VERSION ""

NS_ :

BS_:

BU_: Dummy_FO EOCM2cp_K2_FO EOCM2cp_K1_FO EOCM2cp_IMX6_FO CECM_R1_FO CMMb_FO CMMa_FO RSRR_FO LRR_FO CIPM_FO IMU2_FO IMU1_FO CGM3b_FO

BO_ 1369 UUDT_Resp_From_RSRR_FO: 8 RSRR_FO
 SG_ DgnInf_OBJ559 : 7|64@0+ (1,0) [0|1.84467440737096E+019] ""  CECM_R1_FO,CGM3b_FO

BO_ 1346 UUDT_Resp_From_LRR: 8 LRR_FO
 SG_ DgnInf_OBJ542 : 7|64@0+ (1,0) [0|1.84467440737096E+019] ""  CECM_R1_FO,CGM3b_FO

BO_ 601 USDT_Req_to_RSRR_FO: 8 CGM3b_FO
 SG_ DgnInf : 7|64@0+ (1,0) [0|1.84467440737096E+019] ""  RSRR_FO

BO_ 578 USDT_Req_to_LRR_FO: 8 CGM3b_FO
 SG_ DgnInf : 7|64@0+ (1,0) [0|1.84467440737096E+019] ""  LRR_FO

BO_ 1616 USDT_Resp_From_EOCM2cp_IMX6_FO: 8 EOCM2cp_IMX6_FO
 SG_ DgnInf : 7|64@0+ (1,0) [0|1.84467440737096E+019] ""  CECM_R1_FO,CGM3b_FO

BO_ 1373 UUDT_Resp_From_CGM3b_FO: 8 CGM3b_FO
 SG_ DgnInf_FO55D : 7|64@0+ (1,0) [0|1.84467440737096E+019] ""  CECM_R1_FO

BO_ 1629 USDT_Resp_From_CGM3b_FO: 8 CGM3b_FO
 SG_ DgnInf : 7|64@0+ (1,0) [0|1.84467440737096E+019] ""  CECM_R1_FO

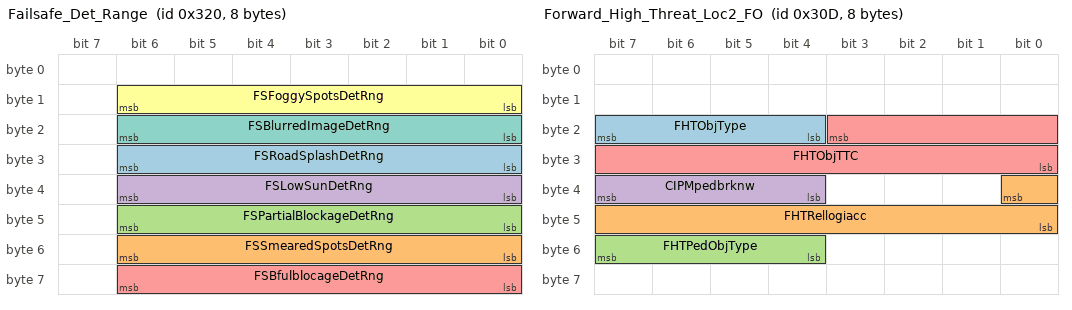
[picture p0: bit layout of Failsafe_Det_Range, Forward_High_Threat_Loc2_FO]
BO_ 800 Failsafe_Det_Range: 8 EOCM2cp_K1_FO
 SG_ FSRoadSplashDetRng : 30|7@0+ (1,-0) [0|127] ""  CGM3b_FO,CECM_R1_FO
 SG_ FSSmearedSpotsDetRng : 54|7@0+ (1,-0) [0|127] ""  CGM3b_FO,CECM_R1_FO
 SG_ FSPartialBlockageDetRng : 46|7@0+ (1,-0) [0|127] ""  CGM3b_FO,CECM_R1_FO
 SG_ FSLowSunDetRng : 38|7@0+ (1,-0) [0|127] ""  CGM3b_FO,CECM_R1_FO
 SG_ FSBfulblocageDetRng : 62|7@0+ (1,-0) [0|127] ""  CGM3b_FO,CECM_R1_FO
 SG_ FSFoggySpotsDetRng : 14|7@0+ (1,-0) [0|127] ""  CGM3b_FO,CECM_R1_FO
 SG_ FSBlurredImageDetRng : 22|7@0+ (1,-0) [0|127] ""  CGM3b_FO,CECM_R1_FO

BO_ 781 Forward_High_Threat_Loc2_FO: 8 EOCM2cp_K1_FO
 SG_ FHTObjType : 23|4@0+ (1,0) [0|15] ""  CECM_R1_FO
 SG_ FHTRellogiacc : 32|9@0- (0.125,0) [-32|31.875] ""  CECM_R1_FO,CGM3b_FO
 SG_ FHTPedObjType : 55|4@0+ (1,0) [0|15] ""  CECM_R1_FO,CGM3b_FO
 SG_ CIPMpedbrknw : 39|4@0+ (1,0) [0|15] ""  CECM_R1_FO,CGM3b_FO
 SG_ FHTObjTTC : 19|12@0+ (0.025,0) [0|102.375] ""  CECM_R1_FO,CGM3b_FO

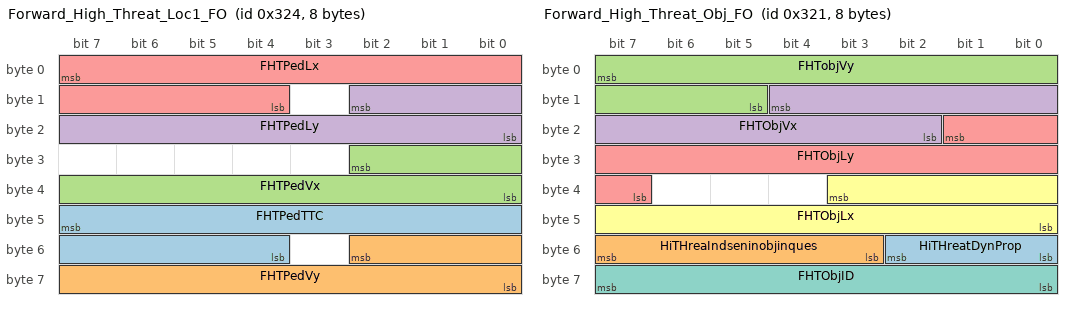
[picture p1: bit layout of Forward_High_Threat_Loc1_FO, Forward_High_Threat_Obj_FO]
BO_ 804 Forward_High_Threat_Loc1_FO: 8 EOCM2cp_K1_FO
 SG_ FHTPedTTC : 47|12@0+ (0.025,0) [0|102.375] ""  CGM3b_FO,CECM_R1_FO
 SG_ FHTPedVy : 50|11@0- (0.125,0) [-128|127.875] ""  CGM3b_FO,CECM_R1_FO
 SG_ FHTPedVx : 26|11@0- (0.125,0) [-128|127.875] ""  CGM3b_FO,CECM_R1_FO
 SG_ FHTPedLy : 10|11@0- (0.125,0) [-128|127.875] ""  CGM3b_FO,CECM_R1_FO
 SG_ FHTPedLx : 7|12@0- (0.125,0) [-256|255.875] ""  CGM3b_FO,CECM_R1_FO

BO_ 801 Forward_High_Threat_Obj_FO: 8 EOCM2cp_K1_FO
 SG_ HiTHreatDynProp : 50|3@0+ (1,0) [0|7] ""  CGM3b_FO,CECM_R1_FO
 SG_ HiTHreaIndseninobjinques : 55|5@0+ (1,0) [0|31] ""  CGM3b_FO,CECM_R1_FO
 SG_ FHTobjVy : 7|11@0- (0.125,0) [-128|127.875] ""  CGM3b_FO,CECM_R1_FO
 SG_ FHTObjVx : 12|11@0- (0.125,0) [-128|127.875] ""  CGM3b_FO,CECM_R1_FO
 SG_ FHTObjLy : 17|11@0- (0.125,0) [-128|127.875] ""  CGM3b_FO,CECM_R1_FO
 SG_ FHTObjLx : 35|12@0- (0.125,0) [-256|255.875] ""  CGM3b_FO,CECM_R1_FO
 SG_ FHTObjID : 63|8@0+ (1,0) [0|255] ""  CGM3b_FO,CECM_R1_FO

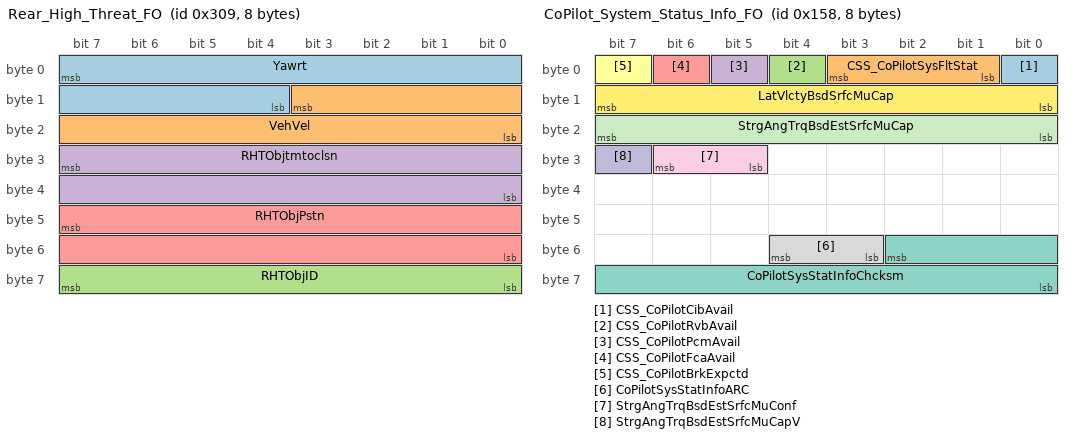
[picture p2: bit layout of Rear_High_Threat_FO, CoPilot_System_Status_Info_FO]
BO_ 777 Rear_High_Threat_FO: 8 EOCM2cp_K2_FO
 SG_ Yawrt : 7|12@0- (0.05,0) [-102.4|102.35] "deg/sec"  CGM3b_FO,CECM_R1_FO
 SG_ VehVel : 11|12@0- (0.0625,0) [-128|127.9375] ""  CGM3b_FO,CECM_R1_FO
 SG_ RHTObjID : 63|8@0+ (1,0) [0|255] ""  CGM3b_FO,CECM_R1_FO
 SG_ RHTObjtmtoclsn : 31|16@0+ (0.001526,0) [0|100.00641] ""  CGM3b_FO,CECM_R1_FO
 SG_ RHTObjPstn : 47|16@0- (0.003052,0) [-100.007936|100.004884] ""  CGM3b_FO,CECM_R1_FO

BO_ 605 USDT_Req_to_CGM3b_FO: 8 CECM_R1_FO
 SG_ DgnInf : 7|64@0+ (1,0) [0|1.84467440737096E+019] ""  CGM3b_FO

BO_ 1366 UUDT_Resp_From_CMMb_FO: 8 CMMb_FO
 SG_ DgnInf_FO556 : 7|64@0+ (1,0) [0|1.84467440737096E+019] ""  CGM3b_FO

BO_ 587 USDT_Req_to_EOCM2cp_K2_FO: 8 CGM3b_FO
 SG_ DgnInf : 7|64@0+ (1,0) [0|1.84467440737096E+019] ""  EOCM2cp_K2_FO

BO_ 1355 UUDT_Resp_From_EOCM2cp_K2_FO: 8 EOCM2cp_K2_FO
 SG_ DgnInf_OBJ54B : 7|64@0+ (1,0) [0|1.84467440737096E+019] ""  CECM_R1_FO,CGM3b_FO

BO_ 1611 USDT_Resp_From_EOCM2cp_K2_FO: 8 EOCM2cp_K2_FO
 SG_ DgnInf : 7|64@0+ (1,0) [0|1.84467440737096E+019] ""  CECM_R1_FO,CGM3b_FO

BO_ 1916 DTC_Triggered_77C_FO: 7 CMMb_FO
 SG_ DTCI_DTCFaultType_77C : 55|8@0+ (1,0) [0|255] ""  CGM3b_FO
 SG_ DTCI_CodeSupported_77C : 40|1@0+ (1,0) [0|1] ""  CGM3b_FO
 SG_ DTCI_CurrentStatus_77C : 41|1@0+ (1,0) [0|1] ""  CGM3b_FO
 SG_ DTCI_TstNPsdCdClrdSt_77C : 42|1@0+ (1,0) [0|1] ""  CGM3b_FO
 SG_ DTCI_TstFldCdClrdStat_77C : 43|1@0+ (1,0) [0|1] ""  CGM3b_FO
 SG_ DTCI_HistStat_77C : 44|1@0+ (1,0) [0|1] ""  CGM3b_FO
 SG_ DTCI_TstNPsdPwrUpSt_77C : 45|1@0+ (1,0) [0|1] ""  CGM3b_FO
 SG_ DTCI_TstFldPwrUpSt_77C : 46|1@0+ (1,0) [0|1] ""  CGM3b_FO
 SG_ DTCI_WrnIndRqdSt_77C : 47|1@0+ (1,0) [0|1] ""  CGM3b_FO
 SG_ DTCI_DTCFailType_77C : 39|8@0+ (1,0) [0|255] ""  CGM3b_FO
 SG_ DTCI_DTCNumber_77C : 23|16@0+ (1,0) [0|65535] ""  CGM3b_FO
 SG_ DTCI_DTCSource_77C : 15|8@0+ (1,0) [0|255] ""  CGM3b_FO
 SG_ DTCI_DTCTriggered_77C : 0|1@0+ (1,0) [0|1] ""  CGM3b_FO
 SG_ DTCIUnused7_77C : 1|1@0+ (1,0) [0|1] ""  CGM3b_FO
 SG_ DTCIUnused6_77C : 2|1@0+ (1,0) [0|1] ""  CGM3b_FO
 SG_ DTCIUnused5_77C : 3|1@0+ (1,0) [0|1] ""  CGM3b_FO
 SG_ DTCIUnused4_77C : 4|1@0+ (1,0) [0|1] ""  CGM3b_FO
 SG_ DTCIUnused3_77C : 5|1@0+ (1,0) [0|1] ""  CGM3b_FO
 SG_ DTCIUnused2_77C : 6|1@0+ (1,0) [0|1] ""  CGM3b_FO
 SG_ DTCIUnused1_77C : 7|1@0+ (1,0) [0|1] ""  CGM3b_FO

BO_ 1365 UUDT_Resp_From_CIPM_FO: 8 CIPM_FO
 SG_ DgnInf_OBJ555 : 7|64@0+ (1,0) [0|1.84467440737096E+019] ""  CECM_R1_FO,CGM3b_FO

BO_ 2034 CCP_Data_Transmission_Object_FO: 8 Dummy_FO
 SG_ DgnInf : 7|64@0+ (1,0) [0|1.84467440737096E+019] ""  CGM3b_FO

BO_ 2032 CCP_Command_Receive_Object_FO: 8 CGM3b_FO
 SG_ DgnInf : 7|64@0+ (1,0) [0|1.84467440737096E+019] ""  Dummy_FO

BO_ 1604 USDT_Resp_From_6DOFIMU1_FO: 8 IMU1_FO
 SG_ DgnInf : 7|64@0+ (1,0) [0|1.84467440737096E+019] ""  CECM_R1_FO,CGM3b_FO

BO_ 1608 USDT_Resp_From_6DOFIMU2_FO: 8 IMU2_FO
 SG_ DgnInf : 7|64@0+ (1,0) [0|1.84467440737096E+019] ""  CECM_R1_FO,CGM3b_FO

BO_ 1348 UUDT_Resp_From_6DOFIMU1_FO: 8 IMU1_FO
 SG_ DgnInf_OBJ544 : 7|64@0+ (1,0) [0|1.84467440737096E+019] ""  CECM_R1_FO,CGM3b_FO

BO_ 1352 UUDT_Resp_From_6DOFIMU2_FO: 8 IMU2_FO
 SG_ DgnInf_OBJ548 : 7|64@0+ (1,0) [0|1.84467440737096E+019] ""  CECM_R1_FO,CGM3b_FO

BO_ 1929 DTC_Triggered_789_FO: 7 Dummy_FO
 SG_ DTCI_CodeSupported_789 : 40|1@0+ (1,0) [0|1] ""  CGM3b_FO
 SG_ DTCI_CurrentStatus_789 : 41|1@0+ (1,0) [0|1] ""  CGM3b_FO
 SG_ DTCI_DTCFailType_789 : 39|8@0+ (1,0) [0|255] ""  CGM3b_FO
 SG_ DTCI_DTCFaultType_789 : 55|8@0+ (1,0) [0|255] ""  CGM3b_FO
 SG_ DTCI_DTCNumber_789 : 23|16@0+ (1,0) [0|65535] ""  CGM3b_FO
 SG_ DTCI_DTCSource_789 : 15|8@0+ (1,0) [0|255] ""  CGM3b_FO
 SG_ DTCI_DTCTriggered_789 : 0|1@0+ (1,0) [0|1] ""  CGM3b_FO
 SG_ DTCI_HistStat_789 : 44|1@0+ (1,0) [0|1] ""  CGM3b_FO
 SG_ DTCI_TstFldCdClrdStat_789 : 43|1@0+ (1,0) [0|1] ""  CGM3b_FO
 SG_ DTCI_TstFldPwrUpSt_789 : 46|1@0+ (1,0) [0|1] ""  CGM3b_FO
 SG_ DTCI_TstNPsdCdClrdSt_789 : 42|1@0+ (1,0) [0|1] ""  CGM3b_FO
 SG_ DTCI_TstNPsdPwrUpSt_789 : 45|1@0+ (1,0) [0|1] ""  CGM3b_FO
 SG_ DTCIUnused1_789 : 7|1@0+ (1,0) [0|1] ""  CGM3b_FO
 SG_ DTCIUnused2_789 : 6|1@0+ (1,0) [0|1] ""  CGM3b_FO
 SG_ DTCIUnused3_789 : 5|1@0+ (1,0) [0|1] ""  CGM3b_FO
 SG_ DTCIUnused4_789 : 4|1@0+ (1,0) [0|1] ""  CGM3b_FO
 SG_ DTCIUnused5_789 : 3|1@0+ (1,0) [0|1] ""  CGM3b_FO
 SG_ DTCIUnused6_789 : 2|1@0+ (1,0) [0|1] ""  CGM3b_FO
 SG_ DTCIUnused7_789 : 1|1@0+ (1,0) [0|1] ""  CGM3b_FO
 SG_ DTCI_WrnIndRqdSt_789 : 47|1@0+ (1,0) [0|1] ""  CGM3b_FO

BO_ 1622 USDT_Resp_From_CMMb_FO: 8 CMMb_FO
 SG_ DgnInf : 7|64@0+ (1,0) [0|1.84467440737096E+019] ""  CGM3b_FO

BO_ 597 USDT_Req_to_CIPM_FO: 8 CECM_R1_FO
 SG_ DgnInf : 7|64@0+ (1,0) [0|1.84467440737096E+019] ""  CIPM_FO

BO_ 580 USDT_Req_to_6DOFIMU1_FO: 8 CGM3b_FO
 SG_ DgnInf : 7|64@0+ (1,0) [0|1.84467440737096E+019] ""  IMU1_FO

BO_ 344 CoPilot_System_Status_Info_FO: 8 EOCM2cp_K1_FO
 SG_ CSS_CoPilotCibAvail : 0|1@0+ (1,0) [0|1] ""  CGM3b_FO,CECM_R1_FO
 SG_ CSS_CoPilotSysFltStat : 3|3@0+ (1,0) [0|7] ""  CGM3b_FO,CECM_R1_FO
 SG_ CSS_CoPilotRvbAvail : 4|1@0+ (1,0) [0|1] ""  CGM3b_FO,CECM_R1_FO
 SG_ CSS_CoPilotPcmAvail : 5|1@0+ (1,0) [0|1] ""  CGM3b_FO,CECM_R1_FO
 SG_ CSS_CoPilotFcaAvail : 6|1@0+ (1,0) [0|1] ""  CGM3b_FO,CECM_R1_FO
 SG_ CSS_CoPilotBrkExpctd : 7|1@0+ (1,0) [0|1] ""  CGM3b_FO,CECM_R1_FO
 SG_ CoPilotSysStatInfoChcksm : 50|11@0+ (1,0) [0|2047] ""  CGM3b_FO,CECM_R1_FO
 SG_ CoPilotSysStatInfoARC : 52|2@0+ (1,0) [0|0] ""  CGM3b_FO,CECM_R1_FO
 SG_ StrgAngTrqBsdEstSrfcMuConf : 30|2@0+ (1,0) [0|3] ""  CGM3b_FO,CECM_R1_FO
 SG_ StrgAngTrqBsdEstSrfcMuCapV : 31|1@0+ (1,0) [0|1] ""  CGM3b_FO,CECM_R1_FO
 SG_ StrgAngTrqBsdEstSrfcMuCap : 23|8@0+ (0.01,0) [0|2.55] ""  CGM3b_FO,CECM_R1_FO
 SG_ LatVlctyBsdSrfcMuCap : 15|8@0+ (0.01,0) [0|2.55] ""  CGM3b_FO,CECM_R1_FO

BO_ 1605 USDT_Resp_From_CECM_FO: 8 CECM_R1_FO
 SG_ DgnInf : 7|64@0+ (1,0) [0|1.84467440737096E+019] ""  CGM3b_FO

BO_ 598 USDT_Req_to_CMMb_FO: 8 CGM3b_FO
 SG_ DgnInf : 7|64@0+ (1,0) [0|1.84467440737096E+019] ""  CMMb_FO

BO_ 1349 UUDT_Resp_From_CECM_FO: 8 CECM_R1_FO
 SG_ DgnInf_FO545 : 7|64@0+ (1,0) [0|1.84467440737096E+019] ""  CGM3b_FO

BO_ 584 USDT_Req_to_6DOFIMU2_FO: 8 CGM3b_FO
 SG_ DgnInf : 7|64@0+ (1,0) [0|1.84467440737096E+019] ""  IMU2_FO

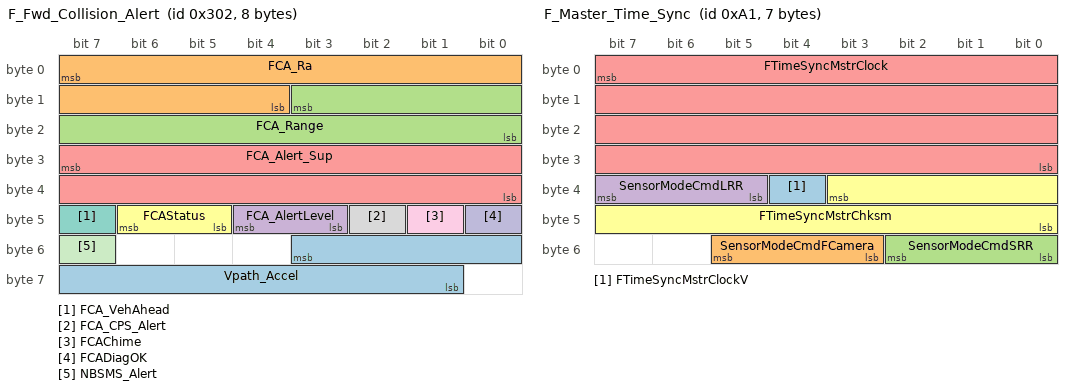
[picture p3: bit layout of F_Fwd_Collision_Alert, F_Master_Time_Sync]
BO_ 770 F_Fwd_Collision_Alert: 8 EOCM2cp_K1_FO
 SG_ Vpath_Accel : 51|11@0- (0.125,0) [-128|127.875] "m/s^2"  CGM3b_FO,Dummy_FO
 SG_ FCA_Ra : 7|12@0- (0.125,0) [-256|255.875] "m"  CGM3b_FO,Dummy_FO
 SG_ FCA_Range : 11|12@0- (0.125,0) [-256|255.875] "m"  CGM3b_FO,Dummy_FO
 SG_ FCA_AlertLevel : 44|2@0+ (1,0) [0|3] ""  CGM3b_FO,Dummy_FO
 SG_ FCA_Alert_Sup : 31|16@0+ (1,0) [0|65535] ""  CGM3b_FO,Dummy_FO
 SG_ FCAStatus : 46|2@0+ (1,0) [0|3] ""  CGM3b_FO,Dummy_FO
 SG_ FCA_VehAhead : 47|1@0+ (1,0) [0|1] ""  CGM3b_FO,Dummy_FO
 SG_ FCA_CPS_Alert : 42|1@0+ (1,0) [0|1] ""  CGM3b_FO,Dummy_FO
 SG_ FCAChime : 41|1@0+ (1,0) [0|1] ""  CGM3b_FO,Dummy_FO
 SG_ FCADiagOK : 40|1@0+ (1,0) [0|1] ""  CGM3b_FO,Dummy_FO
 SG_ NBSMS_Alert : 55|1@0+ (1,0) [0|1] ""  CGM3b_FO,Dummy_FO

BO_ 161 F_Master_Time_Sync: 7 EOCM2cp_K1_FO
 SG_ FTimeSyncMstrClockV : 36|1@0+ (1,0) [0|1] ""  CIPM_FO,RSRR_FO,LRR_FO,CGM3b_FO
 SG_ SensorModeCmdFCamera : 53|3@0+ (1,0) [0|7] ""  CIPM_FO,RSRR_FO,LRR_FO,CGM3b_FO
 SG_ SensorModeCmdSRR : 50|3@0+ (1,0) [0|7] ""  CIPM_FO,RSRR_FO,LRR_FO,CGM3b_FO
 SG_ SensorModeCmdLRR : 39|3@0+ (1,0) [0|7] ""  CIPM_FO,RSRR_FO,LRR_FO,CGM3b_FO
 SG_ FTimeSyncMstrClock : 7|32@0+ (1,0) [0|4294967295] "ms"  CIPM_FO,RSRR_FO,LRR_FO,CGM3b_FO
 SG_ FTimeSyncMstrChksm : 35|12@0+ (1,0) [0|4095] ""  CIPM_FO,RSRR_FO,LRR_FO,CGM3b_FO

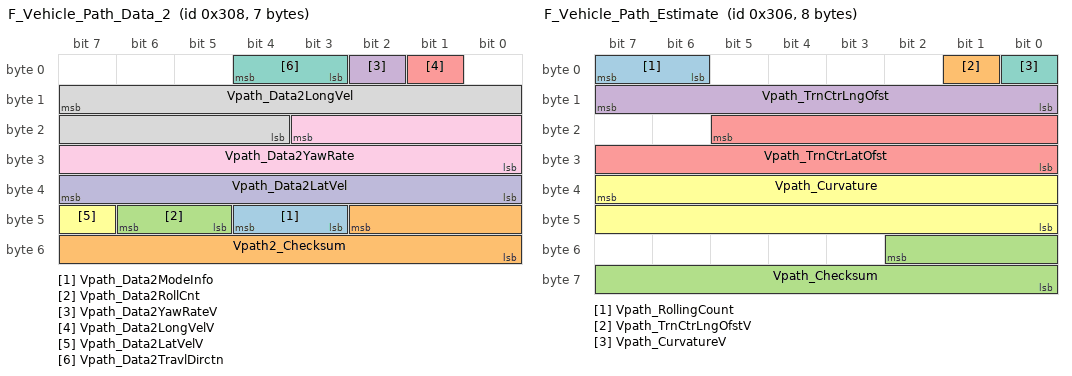
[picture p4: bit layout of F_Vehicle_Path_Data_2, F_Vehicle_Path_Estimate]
BO_ 776 F_Vehicle_Path_Data_2: 7 EOCM2cp_K1_FO
 SG_ Vpath_Data2ModeInfo : 44|2@0+ (1,0) [0|3] ""  CIPM_FO,RSRR_FO,LRR_FO,CGM3b_FO
 SG_ Vpath2_Checksum : 42|11@0+ (1,0) [0|2047] ""  CIPM_FO,RSRR_FO,LRR_FO,CGM3b_FO
 SG_ Vpath_Data2RollCnt : 46|2@0+ (1,0) [0|3] ""  CIPM_FO,RSRR_FO,LRR_FO,CGM3b_FO
 SG_ Vpath_Data2YawRateV : 2|1@0+ (1,0) [0|1] ""  CIPM_FO,RSRR_FO,LRR_FO,CGM3b_FO
 SG_ Vpath_Data2LongVelV : 1|1@0+ (1,0) [0|1] ""  CIPM_FO,RSRR_FO,LRR_FO,CGM3b_FO
 SG_ Vpath_Data2LatVelV : 47|1@0+ (1,0) [0|1] ""  CIPM_FO,RSRR_FO,LRR_FO,CGM3b_FO
 SG_ Vpath_Data2TravlDirctn : 4|2@0+ (1,0) [0|3] ""  CIPM_FO,RSRR_FO,LRR_FO,CGM3b_FO
 SG_ Vpath_Data2LongVel : 15|12@0- (0.0625,0) [-128|127.9375] "m/s"  CIPM_FO,RSRR_FO,LRR_FO,CGM3b_FO
 SG_ Vpath_Data2YawRate : 19|12@0- (0.0625,0) [-128|127.9375] "deg/s"  CIPM_FO,RSRR_FO,LRR_FO,CGM3b_FO
 SG_ Vpath_Data2LatVel : 39|8@0- (0.05,0) [-6.4|6.35] "m/s"  CIPM_FO,RSRR_FO,LRR_FO,CGM3b_FO

BO_ 774 F_Vehicle_Path_Estimate: 8 EOCM2cp_K1_FO
 SG_ Vpath_RollingCount : 7|2@0+ (1,0) [0|3] ""  CIPM_FO,RSRR_FO,LRR_FO,CGM3b_FO
 SG_ Vpath_TrnCtrLngOfstV : 1|1@0+ (1,0) [0|1] ""  CIPM_FO,RSRR_FO,LRR_FO,CGM3b_FO
 SG_ Vpath_Checksum : 50|11@0+ (1,0) [0|2047] ""  CIPM_FO,RSRR_FO,LRR_FO,CGM3b_FO
 SG_ Vpath_TrnCtrLngOfst : 15|8@0- (0.1,0) [-12.8|12.7] "m"  CIPM_FO,RSRR_FO,LRR_FO,CGM3b_FO
 SG_ Vpath_TrnCtrLatOfst : 21|14@0- (1,0) [-8192|8191] "m"  CIPM_FO,RSRR_FO,LRR_FO,CGM3b_FO
 SG_ Vpath_Curvature : 39|16@0- (1E-005,0) [-0.32768|0.32767] "1/m"  CIPM_FO,RSRR_FO,LRR_FO,CGM3b_FO
 SG_ Vpath_CurvatureV : 0|1@0+ (1,0) [0|1] ""  CIPM_FO,RSRR_FO,LRR_FO,CGM3b_FO

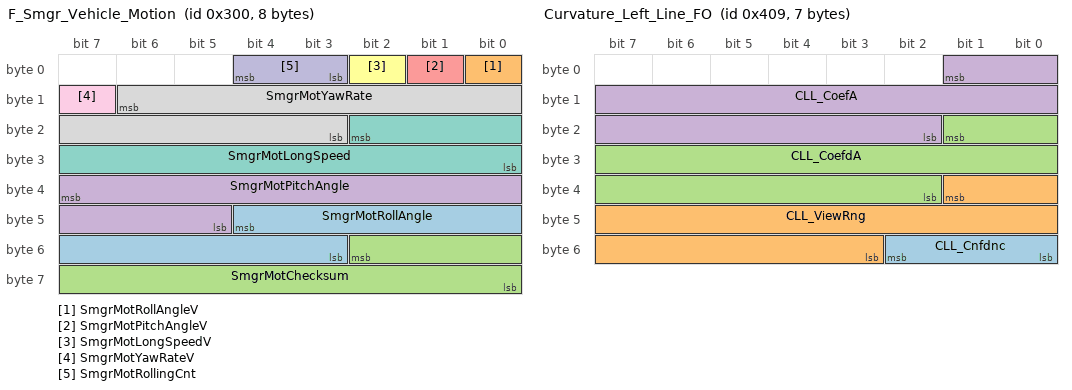
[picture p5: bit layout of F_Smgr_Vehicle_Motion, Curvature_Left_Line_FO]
BO_ 768 F_Smgr_Vehicle_Motion: 8 EOCM2cp_K1_FO
 SG_ SmgrMotRollAngle : 44|10@0- (0.1,0) [-51.2|51.1] "deg"  CIPM_FO,CGM3b_FO
 SG_ SmgrMotRollAngleV : 0|1@0+ (1,0) [0|1] ""  CIPM_FO,CGM3b_FO
 SG_ SmgrMotChecksum : 50|11@0+ (1,0) [0|2047] ""  CIPM_FO,CGM3b_FO
 SG_ SmgrMotPitchAngle : 39|11@0- (0.1,0) [-102.4|102.3] "deg"  CIPM_FO,CGM3b_FO
 SG_ SmgrMotPitchAngleV : 1|1@0+ (1,0) [0|1] ""  CIPM_FO,CGM3b_FO
 SG_ SmgrMotLongSpeedV : 2|1@0+ (1,0) [0|1] " "  CIPM_FO,CGM3b_FO
 SG_ SmgrMotLongSpeed : 18|11@0- (0.1,0) [-102.4|102.3] "m/s"  CIPM_FO,CGM3b_FO
 SG_ SmgrMotYawRate : 14|12@0- (0.05,0) [-102.4|102.35] "deg/s"  CIPM_FO,CGM3b_FO
 SG_ SmgrMotYawRateV : 15|1@0+ (1,0) [0|1] ""  CIPM_FO,CGM3b_FO
 SG_ SmgrMotRollingCnt : 4|2@0+ (1,0) [0|3] ""  CIPM_FO,CGM3b_FO

BO_ 264 Inertial_Trigger_FO: 1 EOCM2cp_K1_FO
 SG_ InrtlSnsrMstrTrgrSync : 7|5@0+ (1,0) [0|31] ""  IMU2_FO,IMU1_FO,CMMb_FO,CMMa_FO,CGM3b_FO

BO_ 586 USDT_Req_to_EOCM2cp_K1_FO: 8 CGM3b_FO
 SG_ DgnInf : 7|64@0+ (1,0) [0|1.84467440737096E+019] ""  EOCM2cp_K1_FO

BO_ 1354 UUDT_Resp_From_EOCM2cp_K1_FO: 8 EOCM2cp_K1_FO
 SG_ DgnInf_OBJ54A : 7|64@0+ (1,0) [0|1.84467440737096E+019] ""  CECM_R1_FO,CGM3b_FO

BO_ 1610 USDT_Resp_From_EOCM2cp_K1_FO: 8 EOCM2cp_K1_FO
 SG_ DgnInf : 7|64@0+ (1,0) [0|1.84467440737096E+019] ""  CECM_R1_FO,CGM3b_FO

BO_ 1033 Curvature_Left_Line_FO: 7 Dummy_FO
 SG_ CLL_Cnfdnc : 50|3@0+ (1,0) [0|7] ""  CGM3b_FO
 SG_ CLL_ViewRng : 33|15@0+ (0.0039064,0) [0|128.0010088] "m"  CGM3b_FO
 SG_ CLL_CoefdA : 17|16@0- (3.6622E-009,0) [-0.0001200029696|0.0001199993074] "1/m^2"  CGM3b_FO
 SG_ CLL_CoefA : 1|16@0- (6.1036E-007,0) [-0.02000027648|0.01999966612] "1/m"  CGM3b_FO

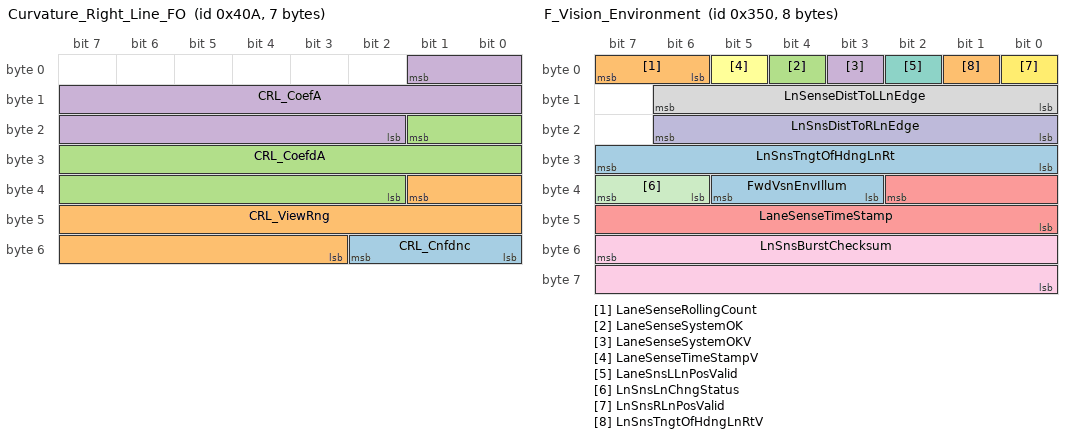
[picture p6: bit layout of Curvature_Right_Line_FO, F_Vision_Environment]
BO_ 1034 Curvature_Right_Line_FO: 7 Dummy_FO
 SG_ CRL_Cnfdnc : 50|3@0+ (1,0) [0|7] ""  CGM3b_FO
 SG_ CRL_ViewRng : 33|15@0+ (0.0039064,0) [0|128.0010088] "m"  CGM3b_FO
 SG_ CRL_CoefdA : 17|16@0- (3.6622E-009,0) [-0.0001200029696|0.0001199993074] "1/m^2"  CGM3b_FO
 SG_ CRL_CoefA : 1|16@0- (6.1036E-007,0) [-0.02000027648|0.01999966612] "1/m"  CGM3b_FO

BO_ 848 F_Vision_Environment: 8 CIPM_FO
 SG_ FwdVsnEnvIllum : 37|3@0+ (1,0) [0|7] ""  CGM3b_FO,EOCM2cp_K2_FO,EOCM2cp_K1_FO,EOCM2cp_IMX6_FO
 SG_ LaneSenseRollingCount : 7|2@0+ (1,0) [0|3] ""  CGM3b_FO,EOCM2cp_K2_FO,EOCM2cp_K1_FO,EOCM2cp_IMX6_FO
 SG_ LaneSenseSystemOK : 4|1@0+ (1,0) [0|1] ""  CGM3b_FO,EOCM2cp_K2_FO,EOCM2cp_K1_FO,EOCM2cp_IMX6_FO
 SG_ LaneSenseSystemOKV : 3|1@0+ (1,0) [0|1] ""  CGM3b_FO,EOCM2cp_K2_FO,EOCM2cp_K1_FO,EOCM2cp_IMX6_FO
 SG_ LaneSenseTimeStamp : 34|11@0+ (1,0) [0|2047] "ms"  CGM3b_FO,EOCM2cp_K2_FO,EOCM2cp_K1_FO,EOCM2cp_IMX6_FO
 SG_ LaneSenseTimeStampV : 5|1@0+ (1,0) [0|1] ""  CGM3b_FO,EOCM2cp_K2_FO,EOCM2cp_K1_FO,EOCM2cp_IMX6_FO
 SG_ LaneSnsLLnPosValid : 2|1@0+ (1,0) [0|1] ""  CGM3b_FO,EOCM2cp_K2_FO,EOCM2cp_K1_FO,EOCM2cp_IMX6_FO
 SG_ LnSenseDistToLLnEdge : 14|7@0+ (0.05,0) [0|6.35] "m"  CGM3b_FO,EOCM2cp_K2_FO,EOCM2cp_K1_FO,EOCM2cp_IMX6_FO
 SG_ LnSnsBurstChecksum : 55|16@0+ (1,0) [0|65535] ""  CGM3b_FO,EOCM2cp_K2_FO,EOCM2cp_K1_FO,EOCM2cp_IMX6_FO
 SG_ LnSnsDistToRLnEdge : 22|7@0+ (0.05,0) [0|6.35] "m"  CGM3b_FO,EOCM2cp_K2_FO,EOCM2cp_K1_FO,EOCM2cp_IMX6_FO
 SG_ LnSnsLnChngStatus : 39|2@0+ (1,0) [0|3] ""  CGM3b_FO,EOCM2cp_K2_FO,EOCM2cp_K1_FO,EOCM2cp_IMX6_FO
 SG_ LnSnsRLnPosValid : 0|1@0+ (1,0) [0|1] ""  CGM3b_FO,EOCM2cp_K2_FO,EOCM2cp_K1_FO,EOCM2cp_IMX6_FO
 SG_ LnSnsTngtOfHdngLnRt : 31|8@0- (0.002,0) [-0.256|0.254] "m/m"  CGM3b_FO,EOCM2cp_K2_FO,EOCM2cp_K1_FO,EOCM2cp_IMX6_FO
 SG_ LnSnsTngtOfHdngLnRtV : 1|1@0+ (1,0) [0|1] ""  CGM3b_FO,EOCM2cp_K2_FO,EOCM2cp_K1_FO,EOCM2cp_IMX6_FO

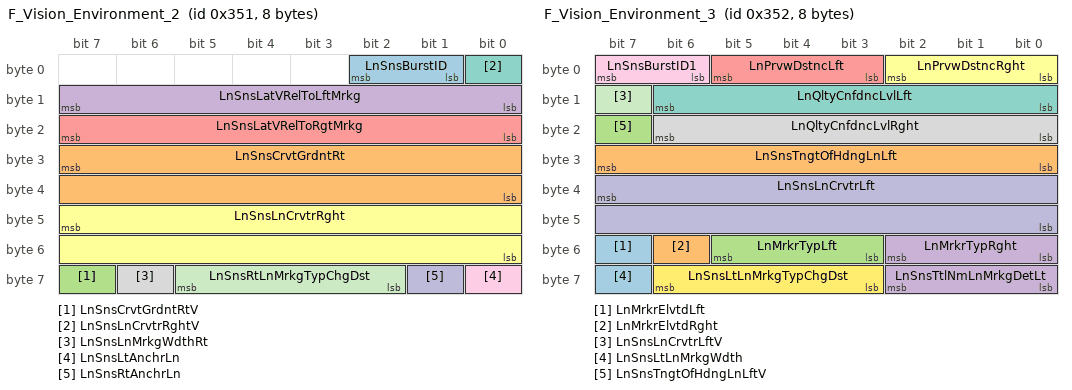
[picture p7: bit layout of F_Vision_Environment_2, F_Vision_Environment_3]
BO_ 849 F_Vision_Environment_2: 8 CIPM_FO
 SG_ LnSnsBurstID : 2|2@0+ (1,0) [0|3] ""  CGM3b_FO,EOCM2cp_K2_FO,EOCM2cp_K1_FO,EOCM2cp_IMX6_FO
 SG_ LnSnsCrvtGrdntRt : 31|16@0- (5.96E-008,0) [-0.0019529728|0.0019529132] "1/rad/s"  CGM3b_FO,EOCM2cp_K2_FO,EOCM2cp_K1_FO,EOCM2cp_IMX6_FO
 SG_ LnSnsCrvtGrdntRtV : 63|1@0+ (1,0) [0|1] ""  CGM3b_FO,EOCM2cp_K2_FO,EOCM2cp_K1_FO,EOCM2cp_IMX6_FO
 SG_ LnSnsLatVRelToLftMrkg : 15|8@0- (0.02,0) [-2.56|2.54] "m/s"  CGM3b_FO,EOCM2cp_K2_FO,EOCM2cp_K1_FO,EOCM2cp_IMX6_FO
 SG_ LnSnsLatVRelToRgtMrkg : 23|8@0- (0.02,0) [-2.56|2.54] "m/s"  CGM3b_FO,EOCM2cp_K2_FO,EOCM2cp_K1_FO,EOCM2cp_IMX6_FO
 SG_ LnSnsLnCrvtrRght : 47|16@0- (9.53E-007,0) [-0.031227904|0.031226951] "1/m"  CGM3b_FO,EOCM2cp_K2_FO,EOCM2cp_K1_FO,EOCM2cp_IMX6_FO
 SG_ LnSnsLnCrvtrRghtV : 0|1@0+ (1,0) [0|1] ""  CGM3b_FO,EOCM2cp_K2_FO,EOCM2cp_K1_FO,EOCM2cp_IMX6_FO
 SG_ LnSnsLnMrkgWdthRt : 62|1@0+ (1,0) [0|1] ""  CGM3b_FO,EOCM2cp_K2_FO,EOCM2cp_K1_FO,EOCM2cp_IMX6_FO
 SG_ LnSnsLtAnchrLn : 56|1@0+ (1,0) [0|1] ""  CGM3b_FO,EOCM2cp_K2_FO,EOCM2cp_K1_FO,EOCM2cp_IMX6_FO
 SG_ LnSnsRtAnchrLn : 57|1@0+ (1,0) [0|1] ""  CGM3b_FO,EOCM2cp_K2_FO,EOCM2cp_K1_FO,EOCM2cp_IMX6_FO
 SG_ LnSnsRtLnMrkgTypChgDst : 61|4@0+ (10,0) [0|150] "m"  CGM3b_FO,EOCM2cp_K2_FO,EOCM2cp_K1_FO,EOCM2cp_IMX6_FO

BO_ 850 F_Vision_Environment_3: 8 CIPM_FO
 SG_ LnMrkrElvtdLft : 55|1@0+ (1,0) [0|1] ""  CGM3b_FO,EOCM2cp_K2_FO,EOCM2cp_K1_FO,EOCM2cp_IMX6_FO
 SG_ LnMrkrElvtdRght : 54|1@0+ (1,0) [0|1] ""  CGM3b_FO,EOCM2cp_K2_FO,EOCM2cp_K1_FO,EOCM2cp_IMX6_FO
 SG_ LnMrkrTypLft : 53|3@0+ (1,0) [0|7] ""  CGM3b_FO,EOCM2cp_K2_FO,EOCM2cp_K1_FO,EOCM2cp_IMX6_FO
 SG_ LnMrkrTypRght : 50|3@0+ (1,0) [0|7] ""  CGM3b_FO,EOCM2cp_K2_FO,EOCM2cp_K1_FO,EOCM2cp_IMX6_FO
 SG_ LnPrvwDstncLft : 5|3@0+ (10,0) [0|70] "m"  CGM3b_FO,EOCM2cp_K2_FO,EOCM2cp_K1_FO,EOCM2cp_IMX6_FO
 SG_ LnPrvwDstncRght : 2|3@0+ (10,0) [0|70] "m"  CGM3b_FO,EOCM2cp_K2_FO,EOCM2cp_K1_FO,EOCM2cp_IMX6_FO
 SG_ LnQltyCnfdncLvlLft : 14|7@0+ (0.7874016,0) [0|100.0000032] "%"  CGM3b_FO,EOCM2cp_K2_FO,EOCM2cp_K1_FO,EOCM2cp_IMX6_FO
 SG_ LnQltyCnfdncLvlRght : 22|7@0+ (0.7874016,0) [0|100.0000032] "%"  CGM3b_FO,EOCM2cp_K2_FO,EOCM2cp_K1_FO,EOCM2cp_IMX6_FO
 SG_ LnSnsBurstID1 : 7|2@0+ (1,0) [0|3] ""  CGM3b_FO,EOCM2cp_K2_FO,EOCM2cp_K1_FO,EOCM2cp_IMX6_FO
 SG_ LnSnsLnCrvtrLft : 39|16@0- (9.53E-007,0) [-0.031227904|0.031226951] "1/m"  CGM3b_FO,EOCM2cp_K2_FO,EOCM2cp_K1_FO,EOCM2cp_IMX6_FO
 SG_ LnSnsLnCrvtrLftV : 15|1@0+ (1,0) [0|1] ""  CGM3b_FO,EOCM2cp_K2_FO,EOCM2cp_K1_FO,EOCM2cp_IMX6_FO
 SG_ LnSnsLtLnMrkgTypChgDst : 62|4@0+ (10,0) [0|150] "m"  CGM3b_FO,EOCM2cp_K2_FO,EOCM2cp_K1_FO,EOCM2cp_IMX6_FO
 SG_ LnSnsLtLnMrkgWdth : 63|1@0+ (1,0) [0|1] ""  CGM3b_FO,EOCM2cp_K2_FO,EOCM2cp_K1_FO,EOCM2cp_IMX6_FO
 SG_ LnSnsTngtOfHdngLnLft : 31|8@0- (0.002,0) [-0.256|0.254] "m/m"  CGM3b_FO,EOCM2cp_K2_FO,EOCM2cp_K1_FO,EOCM2cp_IMX6_FO
 SG_ LnSnsTngtOfHdngLnLftV : 23|1@0+ (1,0) [0|1] ""  CGM3b_FO,EOCM2cp_K2_FO,EOCM2cp_K1_FO,EOCM2cp_IMX6_FO
 SG_ LnSnsTtlNmLnMrkgDetLt : 58|3@0+ (1,0) [0|7] ""  CGM3b_FO,EOCM2cp_K2_FO,EOCM2cp_K1_FO,EOCM2cp_IMX6_FO

BO_ 851 F_Vision_Environment_4: 8 CIPM_FO
 SG_ LnMrkg3AnchrLnLin : 52|1@0+ (1,0) [0|1] ""  CGM3b_FO,EOCM2cp_K2_FO,EOCM2cp_K1_FO,EOCM2cp_IMX6_FO
 SG_ LnMrkg3LnMarkrElvtd : 46|1@0+ (1,0) [0|1] ""  CGM3b_FO,EOCM2cp_K2_FO,EOCM2cp_K1_FO,EOCM2cp_IMX6_FO
 SG_ LnMrkg3LnMrkgTypChgDst : 40|4@0+ (10,0) [0|150] "m"  CGM3b_FO,EOCM2cp_K2_FO,EOCM2cp_K1_FO,EOCM2cp_IMX6_FO
 SG_ LnMrkg3LnMrkgWdth : 41|1@0+ (1,0) [0|1] ""  CGM3b_FO,EOCM2cp_K2_FO,EOCM2cp_K1_FO,EOCM2cp_IMX6_FO
 SG_ LnMrkg3LnPrvwDst : 45|4@0+ (10,0) [0|150] "m"  CGM3b_FO,EOCM2cp_K2_FO,EOCM2cp_K1_FO,EOCM2cp_IMX6_FO
 SG_ LnMrkg4AnchrLnLin : 57|1@0+ (1,0) [0|1] ""  CGM3b_FO,EOCM2cp_K2_FO,EOCM2cp_K1_FO,EOCM2cp_IMX6_FO
 SG_ LnMrkg4LnMarkrElvtd : 51|1@0+ (1,0) [0|1] ""  CGM3b_FO,EOCM2cp_K2_FO,EOCM2cp_K1_FO,EOCM2cp_IMX6_FO
 SG_ LnMrkg4LnMrkgTypChgDst : 61|4@0+ (10,0) [0|150] "m"  CGM3b_FO,EOCM2cp_K2_FO,EOCM2cp_K1_FO,EOCM2cp_IMX6_FO
 SG_ LnMrkg4LnMrkgWdth : 62|1@0+ (1,0) [0|1] ""  CGM3b_FO,EOCM2cp_K2_FO,EOCM2cp_K1_FO,EOCM2cp_IMX6_FO
 SG_ LnMrkg4LnPrvwDst : 50|4@0+ (10,0) [0|150] "m"  CGM3b_FO,EOCM2cp_K2_FO,EOCM2cp_K1_FO,EOCM2cp_IMX6_FO
 SG_ LnSnsBurstID2 : 1|2@0+ (1,0) [0|3] ""  CGM3b_FO,EOCM2cp_K2_FO,EOCM2cp_K1_FO,EOCM2cp_IMX6_FO
 SG_ LnSnsCrvtGrdntLft : 15|16@0- (5.96E-008,0) [-0.0019529728|0.0019529132] "1/rad/s"  CGM3b_FO,EOCM2cp_K2_FO,EOCM2cp_K1_FO,EOCM2cp_IMX6_FO
 SG_ LnSnsCrvtGrdntLftV : 31|1@0+ (1,0) [0|1] ""  CGM3b_FO,EOCM2cp_K2_FO,EOCM2cp_K1_FO,EOCM2cp_IMX6_FO
 SG_ LnSnsLtLinCrsTm : 30|5@0+ (0.1,0) [0|3.1] "s"  CGM3b_FO,EOCM2cp_K2_FO,EOCM2cp_K1_FO,EOCM2cp_IMX6_FO
 SG_ LnSnsNumPrlLnsDetLt : 36|3@0+ (1,0) [0|7] ""  CGM3b_FO,EOCM2cp_K2_FO,EOCM2cp_K1_FO,EOCM2cp_IMX6_FO
 SG_ LnSnsNumPrlLnsDetRt : 33|3@0+ (1,0) [0|7] ""  CGM3b_FO,EOCM2cp_K2_FO,EOCM2cp_K1_FO,EOCM2cp_IMX6_FO
 SG_ LnSnsRtLinCrsTm : 25|5@0+ (0.1,0) [0|3.1] "s"  CGM3b_FO,EOCM2cp_K2_FO,EOCM2cp_K1_FO,EOCM2cp_IMX6_FO
 SG_ LnSnsTtlNmLnMrkgDetRt : 4|3@0+ (1,0) [0|7] ""  CGM3b_FO,EOCM2cp_K2_FO,EOCM2cp_K1_FO,EOCM2cp_IMX6_FO

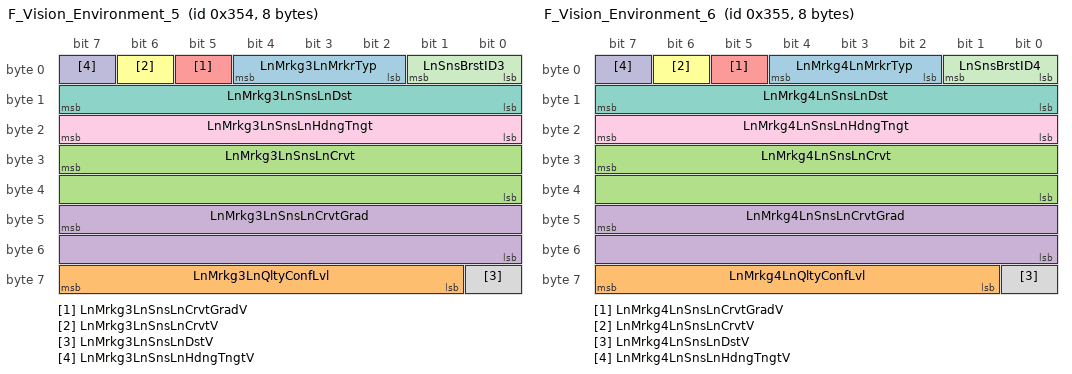
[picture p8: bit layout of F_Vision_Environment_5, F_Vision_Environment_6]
BO_ 852 F_Vision_Environment_5: 8 CIPM_FO
 SG_ LnMrkg3LnMrkrTyp : 4|3@0+ (1,0) [0|7] ""  CGM3b_FO,EOCM2cp_K2_FO,EOCM2cp_K1_FO,EOCM2cp_IMX6_FO
 SG_ LnMrkg3LnQltyConfLvl : 63|7@0+ (0.7874016,0) [0|100.0000032] "%"  CGM3b_FO,EOCM2cp_K2_FO,EOCM2cp_K1_FO,EOCM2cp_IMX6_FO
 SG_ LnMrkg3LnSnsLnCrvt : 31|16@0- (9.53E-007,0) [-0.031227904|0.031226951] "1/m"  CGM3b_FO,EOCM2cp_K2_FO,EOCM2cp_K1_FO,EOCM2cp_IMX6_FO
 SG_ LnMrkg3LnSnsLnCrvtGrad : 47|16@0- (5.96E-008,0) [-0.0019529728|0.0019529132] "1/(m*sec)"  CGM3b_FO,EOCM2cp_K2_FO,EOCM2cp_K1_FO,EOCM2cp_IMX6_FO
 SG_ LnMrkg3LnSnsLnCrvtGradV : 5|1@0+ (1,0) [0|1] ""  CGM3b_FO,EOCM2cp_K2_FO,EOCM2cp_K1_FO,EOCM2cp_IMX6_FO
 SG_ LnMrkg3LnSnsLnCrvtV : 6|1@0+ (1,0) [0|1] ""  CGM3b_FO,EOCM2cp_K2_FO,EOCM2cp_K1_FO,EOCM2cp_IMX6_FO
 SG_ LnMrkg3LnSnsLnDst : 15|8@0- (0.1,0) [-12.8|12.7] "m"  CGM3b_FO,EOCM2cp_K2_FO,EOCM2cp_K1_FO,EOCM2cp_IMX6_FO
 SG_ LnMrkg3LnSnsLnDstV : 56|1@0+ (1,0) [0|1] ""  CGM3b_FO,EOCM2cp_K2_FO,EOCM2cp_K1_FO,EOCM2cp_IMX6_FO
 SG_ LnMrkg3LnSnsLnHdngTngt : 23|8@0- (0.002,0) [-0.256|0.254] "m/m"  CGM3b_FO,EOCM2cp_K2_FO,EOCM2cp_K1_FO,EOCM2cp_IMX6_FO
 SG_ LnMrkg3LnSnsLnHdngTngtV : 7|1@0+ (1,0) [0|1] ""  CGM3b_FO,EOCM2cp_K2_FO,EOCM2cp_K1_FO,EOCM2cp_IMX6_FO
 SG_ LnSnsBrstID3 : 1|2@0+ (1,0) [0|3] ""  CGM3b_FO,EOCM2cp_K2_FO,EOCM2cp_K1_FO,EOCM2cp_IMX6_FO

BO_ 853 F_Vision_Environment_6: 8 CIPM_FO
 SG_ LnMrkg4LnMrkrTyp : 4|3@0+ (1,0) [0|7] ""  CGM3b_FO,EOCM2cp_K2_FO,EOCM2cp_K1_FO,EOCM2cp_IMX6_FO
 SG_ LnMrkg4LnQltyConfLvl : 63|7@0+ (0.7874016,0) [0|100.0000032] "%"  CGM3b_FO,EOCM2cp_K2_FO,EOCM2cp_K1_FO,EOCM2cp_IMX6_FO
 SG_ LnMrkg4LnSnsLnCrvt : 31|16@0- (9.53E-007,0) [-0.031227904|0.031226951] "1/m"  CGM3b_FO,EOCM2cp_K2_FO,EOCM2cp_K1_FO,EOCM2cp_IMX6_FO
 SG_ LnMrkg4LnSnsLnCrvtGrad : 47|16@0- (5.96E-008,0) [-0.0019529728|0.0019529132] "1/(m*sec)"  CGM3b_FO,EOCM2cp_K2_FO,EOCM2cp_K1_FO,EOCM2cp_IMX6_FO
 SG_ LnMrkg4LnSnsLnCrvtGradV : 5|1@0+ (1,0) [0|1] ""  CGM3b_FO,EOCM2cp_K2_FO,EOCM2cp_K1_FO,EOCM2cp_IMX6_FO
 SG_ LnMrkg4LnSnsLnCrvtV : 6|1@0+ (1,0) [0|1] ""  CGM3b_FO,EOCM2cp_K2_FO,EOCM2cp_K1_FO,EOCM2cp_IMX6_FO
 SG_ LnMrkg4LnSnsLnDst : 15|8@0- (0.1,0) [-12.8|12.7] "m"  CGM3b_FO,EOCM2cp_K2_FO,EOCM2cp_K1_FO,EOCM2cp_IMX6_FO
 SG_ LnMrkg4LnSnsLnDstV : 56|1@0+ (1,0) [0|1] ""  CGM3b_FO,EOCM2cp_K2_FO,EOCM2cp_K1_FO,EOCM2cp_IMX6_FO
 SG_ LnMrkg4LnSnsLnHdngTngt : 23|8@0- (0.002,0) [-0.256|0.254] "m/m"  CGM3b_FO,EOCM2cp_K2_FO,EOCM2cp_K1_FO,EOCM2cp_IMX6_FO
 SG_ LnMrkg4LnSnsLnHdngTngtV : 7|1@0+ (1,0) [0|1] ""  CGM3b_FO,EOCM2cp_K2_FO,EOCM2cp_K1_FO,EOCM2cp_IMX6_FO
 SG_ LnSnsBrstID4 : 1|2@0+ (1,0) [0|3] ""  CGM3b_FO,EOCM2cp_K2_FO,EOCM2cp_K1_FO,EOCM2cp_IMX6_FO

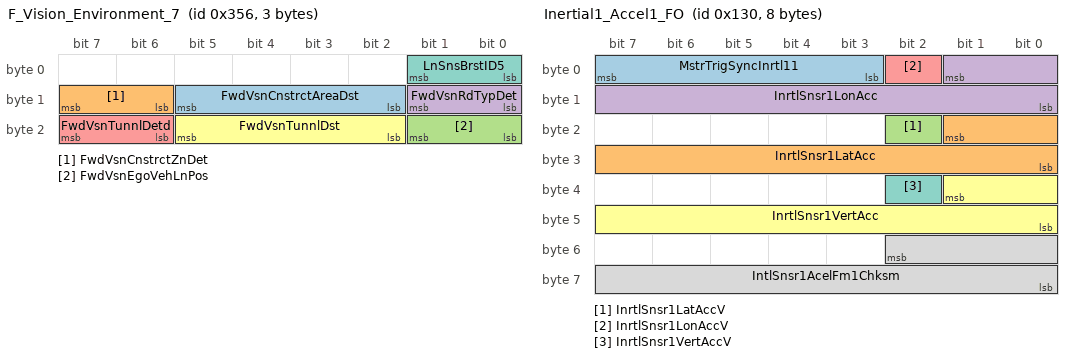
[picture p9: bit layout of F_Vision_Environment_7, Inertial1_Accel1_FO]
BO_ 854 F_Vision_Environment_7: 3 CIPM_FO
 SG_ FwdVsnCnstrctAreaDst : 13|4@0+ (10,0) [0|150] "m"  CGM3b_FO,EOCM2cp_K2_FO,EOCM2cp_K1_FO,EOCM2cp_IMX6_FO
 SG_ FwdVsnCnstrctZnDet : 15|2@0+ (1,0) [0|3] ""  CGM3b_FO,EOCM2cp_K2_FO,EOCM2cp_K1_FO,EOCM2cp_IMX6_FO
 SG_ FwdVsnEgoVehLnPos : 17|2@0+ (1,0) [0|3] ""  CGM3b_FO,EOCM2cp_K2_FO,EOCM2cp_K1_FO,EOCM2cp_IMX6_FO
 SG_ FwdVsnRdTypDet : 9|2@0+ (1,0) [0|3] ""  CGM3b_FO,EOCM2cp_K2_FO,EOCM2cp_K1_FO,EOCM2cp_IMX6_FO
 SG_ FwdVsnTunnlDetd : 23|2@0+ (1,0) [0|3] ""  CGM3b_FO,EOCM2cp_K2_FO,EOCM2cp_K1_FO,EOCM2cp_IMX6_FO
 SG_ FwdVsnTunnlDst : 21|4@0+ (10,0) [0|150] "m"  CGM3b_FO,EOCM2cp_K2_FO,EOCM2cp_K1_FO,EOCM2cp_IMX6_FO
 SG_ LnSnsBrstID5 : 1|2@0+ (1,0) [0|3] ""  CGM3b_FO,EOCM2cp_K2_FO,EOCM2cp_K1_FO,EOCM2cp_IMX6_FO

BO_ 304 Inertial1_Accel1_FO: 8 IMU1_FO
 SG_ MstrTrigSyncInrtl11 : 7|5@0+ (1,0) [0|31] ""  CMMb_FO,CMMa_FO,CGM3b_FO,EOCM2cp_K2_FO
 SG_ InrtlSnsr1LatAcc : 17|10@0- (0.0625,0) [-32|31.9375] "m/s^2"  CMMb_FO,CMMa_FO,CGM3b_FO,EOCM2cp_K2_FO
 SG_ InrtlSnsr1LatAccV : 18|1@0+ (1,0) [0|1] ""  CMMb_FO,CMMa_FO,CGM3b_FO,EOCM2cp_K2_FO
 SG_ InrtlSnsr1LonAcc : 1|10@0- (0.0625,0) [-32|31.9375] "m/s^2"  CMMb_FO,CMMa_FO,CGM3b_FO,EOCM2cp_K2_FO
 SG_ InrtlSnsr1LonAccV : 2|1@0+ (1,0) [0|1] ""  CMMb_FO,CMMa_FO,CGM3b_FO,EOCM2cp_K2_FO
 SG_ InrtlSnsr1VertAcc : 33|10@0- (0.0625,0) [-32|31.9375] "m/s^2"  CMMb_FO,CMMa_FO,CGM3b_FO,EOCM2cp_K2_FO
 SG_ InrtlSnsr1VertAccV : 34|1@0+ (1,0) [0|1] ""  CMMb_FO,CMMa_FO,CGM3b_FO,EOCM2cp_K2_FO
 SG_ IntlSnsr1AcelFm1Chksm : 50|11@0+ (1,0) [0|2047] ""  CMMb_FO,CMMa_FO,CGM3b_FO,EOCM2cp_K2_FO

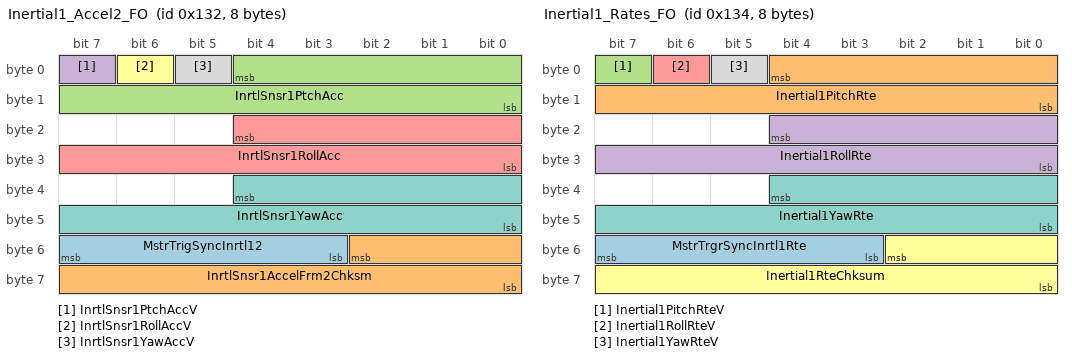
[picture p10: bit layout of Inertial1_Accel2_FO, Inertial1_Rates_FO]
BO_ 306 Inertial1_Accel2_FO: 8 IMU1_FO
 SG_ MstrTrigSyncInrtl12 : 55|5@0+ (1,0) [0|31] ""  CMMb_FO,CMMa_FO,CGM3b_FO,EOCM2cp_K2_FO
 SG_ InrtlSnsr1AccelFrm2Chksm : 50|11@0+ (1,0) [0|2047] ""  CMMb_FO,CMMa_FO,CGM3b_FO,EOCM2cp_K2_FO
 SG_ InrtlSnsr1PtchAcc : 4|13@0- (0.024,0) [-98.304|98.28] "deg/s^2"  CMMb_FO,CMMa_FO,CGM3b_FO,EOCM2cp_K2_FO
 SG_ InrtlSnsr1PtchAccV : 7|1@0+ (1,0) [0|1] ""  CMMb_FO,CMMa_FO,CGM3b_FO,EOCM2cp_K2_FO
 SG_ InrtlSnsr1RollAcc : 20|13@0- (0.024,0) [-98.304|98.28] "deg/s^2"  CMMb_FO,CMMa_FO,CGM3b_FO,EOCM2cp_K2_FO
 SG_ InrtlSnsr1RollAccV : 6|1@0+ (1,0) [0|1] ""  CMMb_FO,CMMa_FO,CGM3b_FO,EOCM2cp_K2_FO
 SG_ InrtlSnsr1YawAcc : 36|13@0- (0.024,0) [-98.304|98.28] "deg/s^2"  CMMb_FO,CMMa_FO,CGM3b_FO,EOCM2cp_K2_FO
 SG_ InrtlSnsr1YawAccV : 5|1@0+ (1,0) [0|1] ""  CMMb_FO,CMMa_FO,CGM3b_FO,EOCM2cp_K2_FO

BO_ 308 Inertial1_Rates_FO: 8 IMU1_FO
 SG_ MstrTrgrSyncInrtl1Rte : 55|5@0+ (1,0) [0|31] ""  CMMb_FO,CMMa_FO,CGM3b_FO,EOCM2cp_K2_FO
 SG_ Inertial1PitchRte : 4|13@0- (0.024,0) [-98.304|98.28] "deg/s"  CMMb_FO,CMMa_FO,CGM3b_FO,EOCM2cp_K2_FO
 SG_ Inertial1PitchRteV : 7|1@0+ (1,0) [0|1] ""  CMMb_FO,CMMa_FO,CGM3b_FO,EOCM2cp_K2_FO
 SG_ Inertial1RollRte : 20|13@0- (0.024,0) [-98.304|98.28] "deg/s"  CMMb_FO,CMMa_FO,CGM3b_FO,EOCM2cp_K2_FO
 SG_ Inertial1RollRteV : 6|1@0+ (1,0) [0|1] ""  CMMb_FO,CMMa_FO,CGM3b_FO,EOCM2cp_K2_FO
 SG_ Inertial1RteChksum : 50|11@0+ (1,0) [0|2047] ""  CMMb_FO,CMMa_FO,CGM3b_FO,EOCM2cp_K2_FO
 SG_ Inertial1YawRte : 36|13@0- (0.024,0) [-98.304|98.28] "deg/s"  CMMb_FO,CMMa_FO,CGM3b_FO,EOCM2cp_K2_FO
 SG_ Inertial1YawRteV : 5|1@0+ (1,0) [0|1] ""  CMMb_FO,CMMa_FO,CGM3b_FO,EOCM2cp_K2_FO

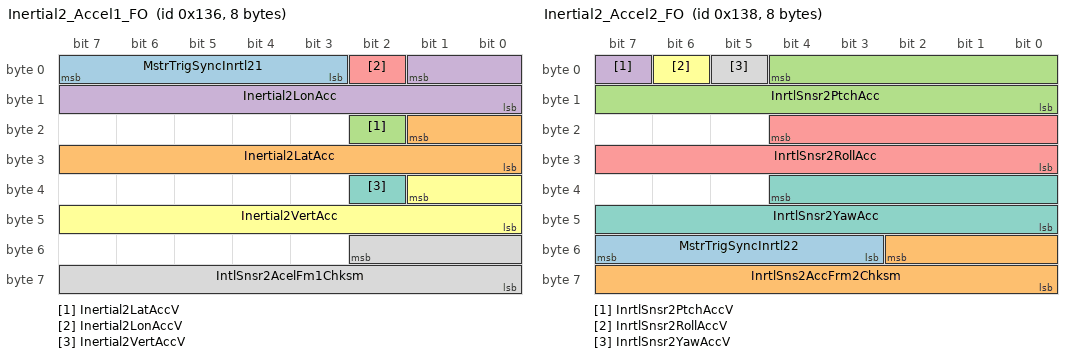
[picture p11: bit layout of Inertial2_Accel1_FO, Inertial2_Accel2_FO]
BO_ 310 Inertial2_Accel1_FO: 8 IMU2_FO
 SG_ MstrTrigSyncInrtl21 : 7|5@0+ (1,0) [0|31] ""  CMMb_FO,CMMa_FO,CGM3b_FO,EOCM2cp_K2_FO
 SG_ Inertial2LatAcc : 17|10@0- (0.0625,0) [-32|31.9375] "m/s^2"  CMMb_FO,CMMa_FO,CGM3b_FO,EOCM2cp_K2_FO
 SG_ Inertial2LatAccV : 18|1@0+ (1,0) [0|1] ""  CMMb_FO,CMMa_FO,CGM3b_FO,EOCM2cp_K2_FO
 SG_ Inertial2LonAcc : 1|10@0- (0.0625,0) [-32|31.9375] "m/s^2"  CMMb_FO,CMMa_FO,CGM3b_FO,EOCM2cp_K2_FO
 SG_ Inertial2LonAccV : 2|1@0+ (1,0) [0|1] ""  CMMb_FO,CMMa_FO,CGM3b_FO,EOCM2cp_K2_FO
 SG_ Inertial2VertAcc : 33|10@0- (0.0625,0) [-32|31.9375] "m/s^2"  CMMb_FO,CMMa_FO,CGM3b_FO,EOCM2cp_K2_FO
 SG_ Inertial2VertAccV : 34|1@0+ (1,0) [0|1] ""  CMMb_FO,CMMa_FO,CGM3b_FO,EOCM2cp_K2_FO
 SG_ IntlSnsr2AcelFm1Chksm : 50|11@0+ (1,0) [0|2047] ""  CMMb_FO,CMMa_FO,CGM3b_FO,EOCM2cp_K2_FO

BO_ 312 Inertial2_Accel2_FO: 8 IMU2_FO
 SG_ MstrTrigSyncInrtl22 : 55|5@0+ (1,0) [0|31] ""  CMMb_FO,CMMa_FO,CGM3b_FO,EOCM2cp_K2_FO
 SG_ InrtlSns2AccFrm2Chksm : 50|11@0+ (1,0) [0|2047] ""  CMMb_FO,CMMa_FO,CGM3b_FO,EOCM2cp_K2_FO
 SG_ InrtlSnsr2PtchAcc : 4|13@0- (0.024,0) [-98.304|98.28] "deg/s^2"  CMMb_FO,CMMa_FO,CGM3b_FO,EOCM2cp_K2_FO
 SG_ InrtlSnsr2PtchAccV : 7|1@0+ (1,0) [0|1] ""  CMMb_FO,CMMa_FO,CGM3b_FO,EOCM2cp_K2_FO
 SG_ InrtlSnsr2RollAcc : 20|13@0- (0.024,0) [-98.304|98.28] "deg/s^2"  CMMb_FO,CMMa_FO,CGM3b_FO,EOCM2cp_K2_FO
 SG_ InrtlSnsr2RollAccV : 6|1@0+ (1,0) [0|1] ""  CMMb_FO,CMMa_FO,CGM3b_FO,EOCM2cp_K2_FO
 SG_ InrtlSnsr2YawAcc : 36|13@0- (0.024,0) [-98.304|98.28] "deg/s^2"  CMMb_FO,CMMa_FO,CGM3b_FO,EOCM2cp_K2_FO
 SG_ InrtlSnsr2YawAccV : 5|1@0+ (1,0) [0|1] ""  CMMb_FO,CMMa_FO,CGM3b_FO,EOCM2cp_K2_FO

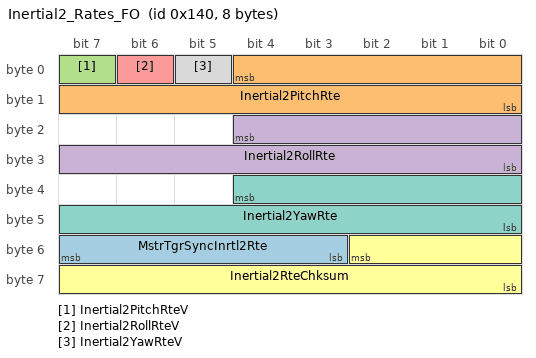
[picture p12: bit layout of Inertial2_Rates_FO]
BO_ 320 Inertial2_Rates_FO: 8 IMU2_FO
 SG_ MstrTgrSyncInrtl2Rte : 55|5@0+ (1,0) [0|31] ""  CGM3b_FO,CMMb_FO,CMMa_FO,EOCM2cp_K2_FO
 SG_ Inertial2PitchRte : 4|13@0- (0.024,0) [-98.304|98.28] "deg/s"  CMMb_FO,CMMa_FO,CGM3b_FO,EOCM2cp_K2_FO
 SG_ Inertial2PitchRteV : 7|1@0+ (1,0) [0|1] ""  CMMb_FO,CMMa_FO,CGM3b_FO,EOCM2cp_K2_FO
 SG_ Inertial2RollRte : 20|13@0- (0.024,0) [-98.304|98.28] "deg/s"  CMMb_FO,CMMa_FO,CGM3b_FO,EOCM2cp_K2_FO
 SG_ Inertial2RollRteV : 6|1@0+ (1,0) [0|1] ""  CMMb_FO,CMMa_FO,CGM3b_FO,EOCM2cp_K2_FO
 SG_ Inertial2RteChksum : 50|11@0+ (1,0) [0|2047] ""  CMMb_FO,CMMa_FO,CGM3b_FO,EOCM2cp_K2_FO
 SG_ Inertial2YawRte : 36|13@0- (0.024,0) [-98.304|98.28] "deg/s"  CMMb_FO,CMMa_FO,CGM3b_FO,EOCM2cp_K2_FO
 SG_ Inertial2YawRteV : 5|1@0+ (1,0) [0|1] ""  CMMb_FO,CMMa_FO,CGM3b_FO,EOCM2cp_K2_FO

BO_ 784 Body_Info_FO: 6 EOCM2cp_K1_FO
 SG_ EngRunAtv : 46|1@0+ (1,0) [0|1] ""  CGM3b_FO,RSRR_FO,LRR_FO,CIPM_FO
 SG_ StrgColUpDwnPos : 39|8@0+ (1,0) [0|255] ""  CGM3b_FO
 SG_ CPMAPINFO4 : 47|1@0+ (1,0) [0|1] ""  CGM3b_FO
 SG_ StrgColInOutPos : 31|8@0+ (1,0) [0|255] ""  CGM3b_FO
 SG_ StrgColCommsFlt : 19|2@0+ (1,0) [0|3] ""  CGM3b_FO
 SG_ DrDoorOpenSwActV : 16|1@0+ (1,0) [0|1] ""  CGM3b_FO
 SG_ DrDoorOpenSwAct : 17|1@0+ (1,0) [0|1] ""  CGM3b_FO
 SG_ DrvWndPosStat : 22|3@0+ (1,0) [0|7] ""  CIPM_FO,CGM3b_FO
 SG_ InterLghtStat : 23|1@0+ (1,0) [0|1] ""  CIPM_FO,CGM3b_FO
 SG_ DrvrHndsOnWhlZn3 : 13|1@0+ (1,0) [0|1] ""  CIPM_FO,CGM3b_FO
 SG_ DrvrHndsOnWhlZn2 : 14|1@0+ (1,0) [0|1] ""  CIPM_FO,CGM3b_FO
 SG_ DrvrHndsOnWhlZn1 : 15|1@0+ (1,0) [0|1] ""  CIPM_FO,CGM3b_FO
 SG_ WSWshSwAtv : 11|1@0+ (1,0) [0|1] ""  CIPM_FO,CGM3b_FO
 SG_ WSWprAct : 2|1@0+ (1,0) [0|1] ""  CIPM_FO,CGM3b_FO
 SG_ RtLwBmFld : 4|1@0+ (1,0) [0|1] ""  CIPM_FO,CGM3b_FO
 SG_ OtsdAmbtLtLvlStatV : 5|1@0+ (1,0) [0|1] ""  CIPM_FO,CGM3b_FO
 SG_ OtsdAmbtLtLvlStat : 7|2@0+ (1,0) [0|3] ""  CIPM_FO,CGM3b_FO
 SG_ LowBmAct : 1|1@0+ (1,0) [0|1] ""  CIPM_FO,CGM3b_FO
 SG_ LftLwBmFld : 3|1@0+ (1,0) [0|1] ""  CIPM_FO,CGM3b_FO
 SG_ HighBmAct : 0|1@0+ (1,0) [0|1] ""  CIPM_FO,CGM3b_FO
 SG_ TrStLgMdAtv : 12|1@0+ (1,0) [0|1] ""  CIPM_FO,CGM3b_FO,RSRR_FO,LRR_FO
 SG_ SysPwrMd : 10|2@0+ (1,0) [0|3] ""  RSRR_FO,LRR_FO,CGM3b_FO,CIPM_FO
 SG_ SysPwrMdV : 8|1@0+ (1,0) [0|1] ""  RSRR_FO,LRR_FO,CGM3b_FO,CIPM_FO

BO_ 257 USDT_Req_to_All_FO_ECUs: 8 CGM3b_FO
 SG_ DgnInf : 7|64@0+ (1,0) [0|1.84467440737096E+019] ""  IMU2_FO,IMU1_FO,CECM_R1_FO,RSRR_FO,LRR_FO,CMMb_FO,CMMa_FO,EOCM2cp_K2_FO,EOCM2cp_K1_FO,EOCM2cp_IMX6_FO,CIPM_FO

BO_ 592 USDT_Req_to_EOCM2cp_IMX6_FO: 8 CGM3b_FO
 SG_ DgnInf : 7|64@0+ (1,0) [0|1.84467440737096E+019] ""  EOCM2cp_IMX6_FO

BO_ 1360 UUDT_Resp_From_EOCM2cp_IMX6_FO: 8 EOCM2cp_IMX6_FO
 SG_ DgnInf_OBJ550 : 7|64@0+ (1,0) [0|1.84467440737096E+019] ""  CECM_R1_FO,CGM3b_FO

BO_ 1621 USDT_Resp_From_CIPM_FO: 8 CIPM_FO
 SG_ DgnInf : 7|64@0+ (1,0) [0|1.84467440737096E+019] ""  CECM_R1_FO,CGM3b_FO

BO_ 581 USDT_Req_to_CECM_FO: 8 CGM3b_FO
 SG_ DgnInf : 7|64@0+ (1,0) [0|1.84467440737096E+019] ""  CECM_R1_FO

BO_ 1627 USDT_Resp_From_CMM_FO: 8 CMMa_FO
 SG_ DgnInf : 7|64@0+ (1,0) [0|1.84467440737096E+019] ""  CGM3b_FO

BO_ 1371 UUDT_Resp_From_CMM_FO: 8 CMMa_FO
 SG_ DgnInf_FO55B : 7|64@0+ (1,0) [0|1.84467440737096E+019] ""  CGM3b_FO

BO_ 603 USDT_Req_to_CMM_FO: 8 CGM3b_FO
 SG_ DgnInf : 7|64@0+ (1,0) [0|1.84467440737096E+019] ""  CMMa_FO

BO_ 1915 DTC_Triggered_77B_FO: 7 CMMa_FO
 SG_ DTCI_DTCFaultType_77B : 55|8@0+ (1,0) [0|255] ""  CGM3b_FO
 SG_ DTCI_CodeSupported_77B : 40|1@0+ (1,0) [0|1] ""  CGM3b_FO
 SG_ DTCI_CurrentStatus_77B : 41|1@0+ (1,0) [0|1] ""  CGM3b_FO
 SG_ DTCI_TstNPsdCdClrdSt_77B : 42|1@0+ (1,0) [0|1] ""  CGM3b_FO
 SG_ DTCI_TstFldCdClrdStat_77B : 43|1@0+ (1,0) [0|1] ""  CGM3b_FO
 SG_ DTCI_HistStat_77B : 44|1@0+ (1,0) [0|1] ""  CGM3b_FO
 SG_ DTCI_TstNPsdPwrUpSt_77B : 45|1@0+ (1,0) [0|1] ""  CGM3b_FO
 SG_ DTCI_TstFldPwrUpSt_77B : 46|1@0+ (1,0) [0|1] ""  CGM3b_FO
 SG_ DTCI_WrnIndRqdSt_77B : 47|1@0+ (1,0) [0|1] ""  CGM3b_FO
 SG_ DTCI_DTCFailType_77B : 39|8@0+ (1,0) [0|255] ""  CGM3b_FO
 SG_ DTCI_DTCNumber_77B : 23|16@0+ (1,0) [0|65535] ""  CGM3b_FO
 SG_ DTCI_DTCSource_77B : 15|8@0+ (1,0) [0|255] ""  CGM3b_FO
 SG_ DTCI_DTCTriggered_77B : 0|1@0+ (1,0) [0|1] ""  CGM3b_FO
 SG_ DTCIUnused7_77B : 1|1@0+ (1,0) [0|1] ""  CGM3b_FO
 SG_ DTCIUnused6_77B : 2|1@0+ (1,0) [0|1] ""  CGM3b_FO
 SG_ DTCIUnused5_77B : 3|1@0+ (1,0) [0|1] ""  CGM3b_FO
 SG_ DTCIUnused4_77B : 4|1@0+ (1,0) [0|1] ""  CGM3b_FO
 SG_ DTCIUnused3_77B : 5|1@0+ (1,0) [0|1] ""  CGM3b_FO
 SG_ DTCIUnused2_77B : 6|1@0+ (1,0) [0|1] ""  CGM3b_FO
 SG_ DTCIUnused1_77B : 7|1@0+ (1,0) [0|1] ""  CGM3b_FO

BO_TX_BU_ 601 : CECM_R1_FO,CGM3b_FO;
BO_TX_BU_ 578 : CECM_R1_FO,CGM3b_FO;
BO_TX_BU_ 587 : CECM_R1_FO,CGM3b_FO;
BO_TX_BU_ 1929 : CIPM_FO,Dummy_FO;
BO_TX_BU_ 597 : CECM_R1_FO,CGM3b_FO;
BO_TX_BU_ 580 : CECM_R1_FO,CGM3b_FO;
BO_TX_BU_ 584 : CECM_R1_FO,CGM3b_FO;
BO_TX_BU_ 586 : CECM_R1_FO,CGM3b_FO;
BO_TX_BU_ 1033 : CIPM_FO,Dummy_FO;
BO_TX_BU_ 1034 : CIPM_FO,Dummy_FO;
BO_TX_BU_ 592 : CECM_R1_FO,CGM3b_FO;
CM_ SG_ 1916 DTCI_DTCFaultType_77C "Based on Powertrain definition.  Not expected to be supported by all devices.";
CM_ SG_ 1916 DTCI_DTCFailType_77C "Assigned per GMW3110, Appendix E";
CM_ SG_ 1916 DTCI_DTCSource_77C "This shall be equal to the Diagnostic Address of the transmittting device.";
CM_ SG_ 1929 DTCI_DTCFailType_789 "Assigned per GMW3110, Appendix E";
CM_ SG_ 1929 DTCI_DTCFaultType_789 "Based on Powertrain definition.  Not expected to be supported by all devices.";
CM_ SG_ 1929 DTCI_DTCSource_789 "This shall be equal to the Diagnostic Address of the transmittting device.";
CM_ SG_ 344 CSS_CoPilotCibAvail "Indicates if the CIB function is currently operational";
CM_ SG_ 344 CSS_CoPilotSysFltStat "

";
CM_ SG_ 344 CSS_CoPilotRvbAvail "CoPilot RVB Available";
CM_ SG_ 344 CSS_CoPilotPcmAvail "Indicates if the PCM function is currently operational";
CM_ SG_ 344 CSS_CoPilotFcaAvail "Indicates if the FCA function is currentlay operational";
CM_ SG_ 344 CSS_CoPilotBrkExpctd "Is Emergency Braking function expected to be functioning";
CM_ BO_ 848 "Application Is Tx ing this frame at the rate of 60 ms";
CM_ BO_ 849 "Application Is Tx ing this frame at the rate of 60 ms";
CM_ BO_ 850 "Application Is Tx ing this frame at the rate of 60 ms";
CM_ BO_ 851 "Application Is Tx ing this frame at the rate of 60 ms";
CM_ SG_ 784 EngRunAtv "Indication from powertrain that the engine is running (Has RPM > 0)";
CM_ SG_ 1915 DTCI_DTCFaultType_77B "Based on Powertrain definition.  Not expected to be supported by all devices.";
CM_ SG_ 1915 DTCI_DTCFailType_77B "Assigned per GMW3110, Appendix E";
CM_ SG_ 1915 DTCI_DTCSource_77B "This shall be equal to the Diagnostic Address of the transmittting device.";
BA_DEF_ SG_  "VNSigSLHSSharedDiagnostic" ENUM  "No","Yes";
BA_DEF_ SG_  "SignalType" STRING ;
BA_DEF_ SG_  "PacketOrder" INT 0 65535;
BA_DEF_ SG_  "SignalLongName" STRING ;
BA_DEF_ SG_  "GenSigStartValue" INT 0 65535;
BA_DEF_ SG_  "VNSigAllNodes" ENUM  "No","Yes";
BA_DEF_ SG_  "GenSigDeltaValue" INT 0 0;
BA_DEF_ SG_  "GenSigSendType" ENUM  "not used","not used","not used","not used","not used","not used","not used","NoSigSendType","not used","not used","OnAnyChange","OnChangeIfActive","OnDelta";
BA_DEF_ SG_  "GenSigSendOnInit" ENUM  "Not Initialized","Application","Handler";
BA_DEF_ BO_  "AppGenMsgCycleTime" INT 0 0;
BA_DEF_ BO_  "GenMsgILSupport" ENUM  "No","Yes";
BA_DEF_ BO_  "TpApplType" STRING ;
BA_DEF_ BO_  "Prio" INT 0 7;
BA_DEF_ BO_  "MessageSubnet" ENUM  "LS","HS","CE","PE","HV","FO","LE","HE2","PHS","PCE","DLCLS","DLCHS","DLCCE","DLCFO";
BA_DEF_ BO_  "DiagState" ENUM  "No","Yes";
BA_DEF_ BO_  "GenMsgDelayTime" INT 0 100000;
BA_DEF_ BO_  "GenMsgCycleTime" INT 0 100000;
BA_DEF_ BO_  "GenMsgCycleTimeFast" INT 0 100000;
BA_DEF_ BO_  "GenMsgSendType" ENUM  "cyclicX","spontanX","cyclicIfActiveX","spontanWithDelay","cyclicAndSpontanX","cyclicAndSpontanWithDelay","spontanWithRepitition","cyclicIfActiveAndSpontanWD";
BA_DEF_ BO_  "DiagResponse" ENUM  "No","Yes";
BA_DEF_ BO_  "DiagRequest" ENUM  "No","Yes";
BA_DEF_ BO_  "NmMessage" ENUM  "No","Yes";
BA_DEF_REL_ BU_SG_REL_  "GenSigSuprvRespComment" STRING ;
BA_DEF_REL_ BU_SG_REL_  "GenSigVBitResp" ENUM  "No","Yes";
BA_DEF_REL_ BU_SG_REL_  "GenSigVBitRespComment" STRING ;
BA_DEF_REL_ BU_SG_REL_  "GenSigVDAFailComment" STRING ;
BA_DEF_REL_ BU_SG_REL_  "GenSigRxStartValue" STRING ;
BA_DEF_REL_ BU_SG_REL_  "GenSigSuprvResp" ENUM  "None","Notify App","Substitute Default";
BA_DEF_REL_ BU_SG_REL_  "GenSigTimeoutMsg" HEX 0 268435455;
BA_DEF_REL_ BU_SG_REL_  "GenSigTimeoutTime" INT 0 15000;
BA_DEF_DEF_  "VNSigSLHSSharedDiagnostic" "No";
BA_DEF_DEF_  "SignalType" "";
BA_DEF_DEF_  "PacketOrder" 0;
BA_DEF_DEF_  "SignalLongName" "";
BA_DEF_DEF_  "GenSigStartValue" 0;
BA_DEF_DEF_  "VNSigAllNodes" "No";
BA_DEF_DEF_  "GenSigDeltaValue" 0;
BA_DEF_DEF_  "GenSigSendType" "NoSigSendType";
BA_DEF_DEF_  "GenSigSendOnInit" "Not Initialized";
BA_DEF_DEF_  "AppGenMsgCycleTime" 0;
BA_DEF_DEF_  "GenMsgILSupport" "Yes";
BA_DEF_DEF_  "TpApplType" "";
BA_DEF_DEF_  "Prio" 4;
BA_DEF_DEF_  "MessageSubnet" "LS";
BA_DEF_DEF_  "DiagState" "No";
BA_DEF_DEF_  "GenMsgDelayTime" 0;
BA_DEF_DEF_  "GenMsgCycleTime" 0;
BA_DEF_DEF_  "GenMsgCycleTimeFast" 0;
BA_DEF_DEF_  "GenMsgSendType" "spontanX";
BA_DEF_DEF_  "DiagResponse" "No";
BA_DEF_DEF_  "DiagRequest" "No";
BA_DEF_DEF_  "NmMessage" "No";
BA_DEF_DEF_REL_ "GenSigSuprvRespComment" "";
BA_DEF_DEF_REL_ "GenSigVBitResp" "No";
BA_DEF_DEF_REL_ "GenSigVBitRespComment" "";
BA_DEF_DEF_REL_ "GenSigVDAFailComment" "";
BA_DEF_DEF_REL_ "GenSigRxStartValue" "";
BA_DEF_DEF_REL_ "GenSigSuprvResp" "None";
BA_DEF_DEF_REL_ "GenSigTimeoutMsg" 0;
BA_DEF_DEF_REL_ "GenSigTimeoutTime" 0;
BA_ "TpApplType" BO_ 1369 "DiagUUDTResponse";
BA_ "Prio" BO_ 1369 0;
BA_ "MessageSubnet" BO_ 1369 5;
BA_ "TpApplType" BO_ 1346 "DiagUUDTResponse";
BA_ "Prio" BO_ 1346 0;
BA_ "MessageSubnet" BO_ 1346 5;
BA_ "Prio" BO_ 601 0;
BA_ "MessageSubnet" BO_ 601 5;
BA_ "DiagRequest" BO_ 601 1;
BA_ "Prio" BO_ 578 0;
BA_ "MessageSubnet" BO_ 578 5;
BA_ "DiagRequest" BO_ 578 1;
BA_ "Prio" BO_ 1616 0;
BA_ "MessageSubnet" BO_ 1616 5;
BA_ "DiagResponse" BO_ 1616 1;
BA_ "GenMsgILSupport" BO_ 1373 0;
BA_ "TpApplType" BO_ 1373 "DiagUUDTResponse";
BA_ "Prio" BO_ 1373 0;
BA_ "MessageSubnet" BO_ 1373 5;
BA_ "Prio" BO_ 1629 0;
BA_ "MessageSubnet" BO_ 1629 5;
BA_ "DiagResponse" BO_ 1629 1;
BA_ "Prio" BO_ 800 0;
BA_ "MessageSubnet" BO_ 800 5;
BA_ "GenMsgCycleTime" BO_ 800 40;
BA_ "GenMsgSendType" BO_ 800 0;
BA_ "Prio" BO_ 781 0;
BA_ "MessageSubnet" BO_ 781 5;
BA_ "GenMsgCycleTime" BO_ 781 40;
BA_ "GenMsgSendType" BO_ 781 0;
BA_ "Prio" BO_ 804 0;
BA_ "MessageSubnet" BO_ 804 5;
BA_ "GenMsgCycleTime" BO_ 804 40;
BA_ "GenMsgSendType" BO_ 804 0;
BA_ "Prio" BO_ 801 0;
BA_ "MessageSubnet" BO_ 801 5;
BA_ "GenMsgCycleTime" BO_ 801 40;
BA_ "GenMsgSendType" BO_ 801 0;
BA_ "Prio" BO_ 777 0;
BA_ "MessageSubnet" BO_ 777 5;
BA_ "GenMsgCycleTime" BO_ 777 40;
BA_ "GenMsgSendType" BO_ 777 0;
BA_ "Prio" BO_ 605 0;
BA_ "MessageSubnet" BO_ 605 5;
BA_ "DiagRequest" BO_ 605 1;
BA_ "GenMsgILSupport" BO_ 1366 0;
BA_ "TpApplType" BO_ 1366 "DiagUUDTResponse";
BA_ "Prio" BO_ 1366 0;
BA_ "MessageSubnet" BO_ 1366 5;
BA_ "GenMsgILSupport" BO_ 587 0;
BA_ "Prio" BO_ 587 0;
BA_ "MessageSubnet" BO_ 587 5;
BA_ "DiagRequest" BO_ 587 1;
BA_ "GenMsgILSupport" BO_ 1355 0;
BA_ "TpApplType" BO_ 1355 "DiagUUDTResponse";
BA_ "Prio" BO_ 1355 0;
BA_ "MessageSubnet" BO_ 1355 5;
BA_ "GenMsgILSupport" BO_ 1611 0;
BA_ "Prio" BO_ 1611 0;
BA_ "MessageSubnet" BO_ 1611 5;
BA_ "DiagResponse" BO_ 1611 1;
BA_ "Prio" BO_ 1916 0;
BA_ "MessageSubnet" BO_ 1916 5;
BA_ "GenMsgCycleTime" BO_ 1916 1000;
BA_ "TpApplType" BO_ 1365 "DiagUUDTResponse";
BA_ "Prio" BO_ 1365 0;
BA_ "MessageSubnet" BO_ 1365 5;
BA_ "Prio" BO_ 2034 0;
BA_ "MessageSubnet" BO_ 2034 5;
BA_ "DiagResponse" BO_ 2034 1;
BA_ "Prio" BO_ 2032 0;
BA_ "MessageSubnet" BO_ 2032 5;
BA_ "DiagRequest" BO_ 2032 1;
BA_ "Prio" BO_ 1604 0;
BA_ "MessageSubnet" BO_ 1604 5;
BA_ "DiagResponse" BO_ 1604 1;
BA_ "Prio" BO_ 1608 0;
BA_ "MessageSubnet" BO_ 1608 5;
BA_ "DiagResponse" BO_ 1608 1;
BA_ "GenMsgILSupport" BO_ 1348 0;
BA_ "TpApplType" BO_ 1348 "DiagUUDTResponse";
BA_ "Prio" BO_ 1348 0;
BA_ "MessageSubnet" BO_ 1348 5;
BA_ "GenMsgILSupport" BO_ 1352 0;
BA_ "TpApplType" BO_ 1352 "DiagUUDTResponse";
BA_ "Prio" BO_ 1352 0;
BA_ "MessageSubnet" BO_ 1352 5;
BA_ "Prio" BO_ 1929 0;
BA_ "MessageSubnet" BO_ 1929 5;
BA_ "GenMsgCycleTime" BO_ 1929 1000;
BA_ "GenMsgSendType" BO_ 1929 0;
BA_ "Prio" BO_ 1622 0;
BA_ "MessageSubnet" BO_ 1622 5;
BA_ "DiagResponse" BO_ 1622 1;
BA_ "Prio" BO_ 597 0;
BA_ "MessageSubnet" BO_ 597 5;
BA_ "DiagRequest" BO_ 597 1;
BA_ "Prio" BO_ 580 0;
BA_ "MessageSubnet" BO_ 580 5;
BA_ "DiagRequest" BO_ 580 1;
BA_ "Prio" BO_ 344 0;
BA_ "MessageSubnet" BO_ 344 5;
BA_ "GenMsgCycleTime" BO_ 344 10;
BA_ "GenMsgSendType" BO_ 344 0;
BA_ "Prio" BO_ 1605 0;
BA_ "MessageSubnet" BO_ 1605 5;
BA_ "DiagResponse" BO_ 1605 1;
BA_ "Prio" BO_ 598 0;
BA_ "MessageSubnet" BO_ 598 5;
BA_ "DiagRequest" BO_ 598 1;
BA_ "GenMsgILSupport" BO_ 1349 0;
BA_ "TpApplType" BO_ 1349 "DiagUUDTResponse";
BA_ "Prio" BO_ 1349 0;
BA_ "MessageSubnet" BO_ 1349 5;
BA_ "Prio" BO_ 584 0;
BA_ "MessageSubnet" BO_ 584 5;
BA_ "DiagRequest" BO_ 584 1;
BA_ "Prio" BO_ 770 0;
BA_ "MessageSubnet" BO_ 770 5;
BA_ "GenMsgCycleTime" BO_ 770 100;
BA_ "GenMsgSendType" BO_ 770 0;
BA_ "Prio" BO_ 161 0;
BA_ "MessageSubnet" BO_ 161 5;
BA_ "GenMsgCycleTime" BO_ 161 100;
BA_ "GenMsgSendType" BO_ 161 0;
BA_ "Prio" BO_ 776 0;
BA_ "MessageSubnet" BO_ 776 5;
BA_ "GenMsgCycleTime" BO_ 776 20;
BA_ "GenMsgSendType" BO_ 776 0;
BA_ "Prio" BO_ 774 0;
BA_ "MessageSubnet" BO_ 774 5;
BA_ "GenMsgCycleTime" BO_ 774 20;
BA_ "GenMsgSendType" BO_ 774 0;
BA_ "Prio" BO_ 768 0;
BA_ "MessageSubnet" BO_ 768 5;
BA_ "GenMsgCycleTime" BO_ 768 50;
BA_ "GenMsgSendType" BO_ 768 0;
BA_ "Prio" BO_ 264 0;
BA_ "MessageSubnet" BO_ 264 5;
BA_ "GenMsgCycleTime" BO_ 264 10;
BA_ "GenMsgSendType" BO_ 264 0;
BA_ "GenMsgILSupport" BO_ 586 0;
BA_ "Prio" BO_ 586 0;
BA_ "MessageSubnet" BO_ 586 5;
BA_ "DiagRequest" BO_ 586 1;
BA_ "GenMsgILSupport" BO_ 1354 0;
BA_ "TpApplType" BO_ 1354 "DiagUUDTResponse";
BA_ "Prio" BO_ 1354 0;
BA_ "MessageSubnet" BO_ 1354 5;
BA_ "GenMsgILSupport" BO_ 1610 0;
BA_ "Prio" BO_ 1610 0;
BA_ "MessageSubnet" BO_ 1610 5;
BA_ "DiagResponse" BO_ 1610 1;
BA_ "Prio" BO_ 1033 0;
BA_ "MessageSubnet" BO_ 1033 5;
BA_ "GenMsgCycleTime" BO_ 1033 100;
BA_ "GenMsgSendType" BO_ 1033 0;
BA_ "Prio" BO_ 1034 0;
BA_ "MessageSubnet" BO_ 1034 5;
BA_ "GenMsgCycleTime" BO_ 1034 100;
BA_ "GenMsgSendType" BO_ 1034 0;
BA_ "AppGenMsgCycleTime" BO_ 848 60;
BA_ "Prio" BO_ 848 0;
BA_ "MessageSubnet" BO_ 848 5;
BA_ "AppGenMsgCycleTime" BO_ 849 60;
BA_ "Prio" BO_ 849 0;
BA_ "MessageSubnet" BO_ 849 5;
BA_ "AppGenMsgCycleTime" BO_ 850 60;
BA_ "Prio" BO_ 850 0;
BA_ "MessageSubnet" BO_ 850 5;
BA_ "AppGenMsgCycleTime" BO_ 851 60;
BA_ "Prio" BO_ 851 0;
BA_ "MessageSubnet" BO_ 851 5;
BA_ "AppGenMsgCycleTime" BO_ 852 60;
BA_ "Prio" BO_ 852 0;
BA_ "MessageSubnet" BO_ 852 5;
BA_ "AppGenMsgCycleTime" BO_ 853 60;
BA_ "Prio" BO_ 853 0;
BA_ "MessageSubnet" BO_ 853 5;
BA_ "AppGenMsgCycleTime" BO_ 854 60;
BA_ "Prio" BO_ 854 0;
BA_ "MessageSubnet" BO_ 854 5;
BA_ "Prio" BO_ 304 0;
BA_ "MessageSubnet" BO_ 304 5;
BA_ "GenMsgCycleTime" BO_ 304 10;
BA_ "GenMsgSendType" BO_ 304 0;
BA_ "Prio" BO_ 306 0;
BA_ "MessageSubnet" BO_ 306 5;
BA_ "GenMsgCycleTime" BO_ 306 10;
BA_ "GenMsgSendType" BO_ 306 0;
BA_ "Prio" BO_ 308 0;
BA_ "MessageSubnet" BO_ 308 5;
BA_ "GenMsgCycleTime" BO_ 308 10;
BA_ "GenMsgSendType" BO_ 308 0;
BA_ "Prio" BO_ 310 0;
BA_ "MessageSubnet" BO_ 310 5;
BA_ "GenMsgCycleTime" BO_ 310 10;
BA_ "GenMsgSendType" BO_ 310 0;
BA_ "Prio" BO_ 312 0;
BA_ "MessageSubnet" BO_ 312 5;
BA_ "GenMsgCycleTime" BO_ 312 10;
BA_ "GenMsgSendType" BO_ 312 0;
BA_ "Prio" BO_ 320 0;
BA_ "MessageSubnet" BO_ 320 5;
BA_ "GenMsgCycleTime" BO_ 320 10;
BA_ "GenMsgSendType" BO_ 320 0;
BA_ "Prio" BO_ 784 0;
BA_ "MessageSubnet" BO_ 784 5;
BA_ "GenMsgDelayTime" BO_ 784 10;
BA_ "GenMsgCycleTime" BO_ 784 100;
BA_ "GenMsgSendType" BO_ 784 0;
BA_ "GenMsgILSupport" BO_ 257 0;
BA_ "Prio" BO_ 257 0;
BA_ "MessageSubnet" BO_ 257 5;
BA_ "DiagState" BO_ 257 1;
BA_ "Prio" BO_ 592 0;
BA_ "MessageSubnet" BO_ 592 5;
BA_ "DiagRequest" BO_ 592 1;
BA_ "GenMsgILSupport" BO_ 1360 0;
BA_ "TpApplType" BO_ 1360 "DiagUUDTResponse";
BA_ "Prio" BO_ 1360 0;
BA_ "MessageSubnet" BO_ 1360 5;
BA_ "Prio" BO_ 1621 0;
BA_ "MessageSubnet" BO_ 1621 5;
BA_ "DiagResponse" BO_ 1621 1;
BA_ "Prio" BO_ 581 0;
BA_ "MessageSubnet" BO_ 581 5;
BA_ "DiagRequest" BO_ 581 1;
BA_ "Prio" BO_ 1627 0;
BA_ "MessageSubnet" BO_ 1627 5;
BA_ "DiagResponse" BO_ 1627 1;
BA_ "GenMsgILSupport" BO_ 1371 0;
BA_ "TpApplType" BO_ 1371 "DiagUUDTResponse";
BA_ "Prio" BO_ 1371 0;
BA_ "MessageSubnet" BO_ 1371 5;
BA_ "Prio" BO_ 603 0;
BA_ "MessageSubnet" BO_ 603 5;
BA_ "DiagRequest" BO_ 603 1;
BA_ "Prio" BO_ 1915 0;
BA_ "MessageSubnet" BO_ 1915 5;
BA_ "GenMsgCycleTime" BO_ 1915 1000;
BA_ "SignalType" SG_ 1369 DgnInf_OBJ559 "UNM";
BA_ "SignalLongName" SG_ 1369 DgnInf_OBJ559 "Diagnostic Information OBJ559";
BA_ "VNSigAllNodes" SG_ 1369 DgnInf_OBJ559 1;
BA_ "SignalType" SG_ 1346 DgnInf_OBJ542 "UNM";
BA_ "SignalLongName" SG_ 1346 DgnInf_OBJ542 "Diagnostic Information OBJ542";
BA_ "VNSigAllNodes" SG_ 1346 DgnInf_OBJ542 1;
BA_ "VNSigSLHSSharedDiagnostic" SG_ 601 DgnInf 1;
BA_ "SignalType" SG_ 601 DgnInf "UNM";
BA_ "SignalLongName" SG_ 601 DgnInf "Diagnostic Information";
BA_ "VNSigAllNodes" SG_ 601 DgnInf 1;
BA_ "VNSigSLHSSharedDiagnostic" SG_ 578 DgnInf 1;
BA_ "SignalType" SG_ 578 DgnInf "UNM";
BA_ "SignalLongName" SG_ 578 DgnInf "Diagnostic Information";
BA_ "VNSigAllNodes" SG_ 578 DgnInf 1;
BA_ "VNSigSLHSSharedDiagnostic" SG_ 1616 DgnInf 1;
BA_ "SignalType" SG_ 1616 DgnInf "UNM";
BA_ "SignalLongName" SG_ 1616 DgnInf "Diagnostic Information";
BA_ "VNSigAllNodes" SG_ 1616 DgnInf 1;
BA_ "SignalType" SG_ 1373 DgnInf_FO55D "UNM";
BA_ "SignalLongName" SG_ 1373 DgnInf_FO55D "Diagnostic Information FO55D";
BA_ "VNSigAllNodes" SG_ 1373 DgnInf_FO55D 1;
BA_ "VNSigSLHSSharedDiagnostic" SG_ 1629 DgnInf 1;
BA_ "SignalType" SG_ 1629 DgnInf "UNM";
BA_ "SignalLongName" SG_ 1629 DgnInf "Diagnostic Information";
BA_ "VNSigAllNodes" SG_ 1629 DgnInf 1;
BA_ "SignalType" SG_ 800 FSRoadSplashDetRng "UNM";
BA_ "SignalLongName" SG_ 800 FSRoadSplashDetRng "Fail Safe Splashes Detection Range";
BA_ "VNSigAllNodes" SG_ 800 FSRoadSplashDetRng 1;
BA_ "SignalType" SG_ 800 FSSmearedSpotsDetRng "UNM";
BA_ "SignalLongName" SG_ 800 FSSmearedSpotsDetRng "Fail Safe Smeared Spots Detection Range";
BA_ "VNSigAllNodes" SG_ 800 FSSmearedSpotsDetRng 1;
BA_ "SignalType" SG_ 800 FSPartialBlockageDetRng "UNM";
BA_ "SignalLongName" SG_ 800 FSPartialBlockageDetRng "Fail Safe Partial Blockage Detection Range";
BA_ "VNSigAllNodes" SG_ 800 FSPartialBlockageDetRng 1;
BA_ "SignalType" SG_ 800 FSLowSunDetRng "UNM";
BA_ "SignalLongName" SG_ 800 FSLowSunDetRng "Fail Safe Low Sun Detection Range";
BA_ "VNSigAllNodes" SG_ 800 FSLowSunDetRng 1;
BA_ "SignalType" SG_ 800 FSBfulblocageDetRng "UNM";
BA_ "SignalLongName" SG_ 800 FSBfulblocageDetRng "Fail Safe Full Blockage Detection Range";
BA_ "VNSigAllNodes" SG_ 800 FSBfulblocageDetRng 1;
BA_ "SignalType" SG_ 800 FSFoggySpotsDetRng "UNM";
BA_ "SignalLongName" SG_ 800 FSFoggySpotsDetRng "Fail Safe Foggy Scene Detection Range";
BA_ "VNSigAllNodes" SG_ 800 FSFoggySpotsDetRng 1;
BA_ "SignalType" SG_ 800 FSBlurredImageDetRng "UNM";
BA_ "SignalLongName" SG_ 800 FSBlurredImageDetRng "Fail Safe Blured Image Detection Range";
BA_ "VNSigAllNodes" SG_ 800 FSBlurredImageDetRng 1;
BA_ "SignalType" SG_ 781 FHTObjType "ENM";
BA_ "SignalLongName" SG_ 781 FHTObjType "Forward High Threat Object Type";
BA_ "VNSigAllNodes" SG_ 781 FHTObjType 1;
BA_ "SignalType" SG_ 781 FHTRellogiacc "SNM";
BA_ "SignalLongName" SG_ 781 FHTRellogiacc "Relative longitudinal acceleration of the high threat object";
BA_ "VNSigAllNodes" SG_ 781 FHTRellogiacc 1;
BA_ "SignalType" SG_ 781 FHTPedObjType "UNM";
BA_ "SignalLongName" SG_ 781 FHTPedObjType "Forward High Threat Pedestrian Object Type";
BA_ "VNSigAllNodes" SG_ 781 FHTPedObjType 1;
BA_ "SignalType" SG_ 781 CIPMpedbrknw "ENM";
BA_ "SignalLongName" SG_ 781 CIPMpedbrknw "CIPM Pedestrian Break Now";
BA_ "VNSigAllNodes" SG_ 781 CIPMpedbrknw 1;
BA_ "SignalType" SG_ 781 FHTObjTTC "UNM";
BA_ "SignalLongName" SG_ 781 FHTObjTTC "Forward High Threat Object Time to Collision";
BA_ "VNSigAllNodes" SG_ 781 FHTObjTTC 1;
BA_ "SignalType" SG_ 804 FHTPedTTC "UNM";
BA_ "SignalLongName" SG_ 804 FHTPedTTC "Forward High Threat Pedestrian Time to Collision";
BA_ "VNSigAllNodes" SG_ 804 FHTPedTTC 1;
BA_ "SignalType" SG_ 804 FHTPedVy "SNM";
BA_ "SignalLongName" SG_ 804 FHTPedVy "Forward High Threat Pedestrian Velocity (y-axis)";
BA_ "VNSigAllNodes" SG_ 804 FHTPedVy 1;
BA_ "SignalType" SG_ 804 FHTPedVx "SNM";
BA_ "SignalLongName" SG_ 804 FHTPedVx "Forward High Threat Pedestrian Velocity (x-axis)";
BA_ "VNSigAllNodes" SG_ 804 FHTPedVx 1;
BA_ "SignalType" SG_ 804 FHTPedLy "SNM";
BA_ "SignalLongName" SG_ 804 FHTPedLy "Forward High Threat Pedestrian Location (y-axis)";
BA_ "VNSigAllNodes" SG_ 804 FHTPedLy 1;
BA_ "SignalType" SG_ 804 FHTPedLx "SNM";
BA_ "SignalLongName" SG_ 804 FHTPedLx "Forward High Threat Pedestrian Location (x-axis)";
BA_ "VNSigAllNodes" SG_ 804 FHTPedLx 1;
BA_ "SignalType" SG_ 801 HiTHreatDynProp "ENM";
BA_ "SignalLongName" SG_ 801 HiTHreatDynProp "Indication of the dynamic property of the high threat object";
BA_ "VNSigAllNodes" SG_ 801 HiTHreatDynProp 1;
BA_ "SignalType" SG_ 801 HiTHreaIndseninobjinques "UNM";
BA_ "SignalLongName" SG_ 801 HiTHreaIndseninobjinques "Indication of sensors seeing the object in question";
BA_ "VNSigAllNodes" SG_ 801 HiTHreaIndseninobjinques 1;
BA_ "SignalType" SG_ 801 FHTobjVy "SNM";
BA_ "SignalLongName" SG_ 801 FHTobjVy "Forward High Threat Object Velocity (y-axis)";
BA_ "VNSigAllNodes" SG_ 801 FHTobjVy 1;
BA_ "SignalType" SG_ 801 FHTObjVx "SNM";
BA_ "SignalLongName" SG_ 801 FHTObjVx "Forward High Threat Object Velocity (x-axis)";
BA_ "VNSigAllNodes" SG_ 801 FHTObjVx 1;
BA_ "SignalType" SG_ 801 FHTObjLy "SNM";
BA_ "SignalLongName" SG_ 801 FHTObjLy "Forward High Threat Object Location (y-axis)";
BA_ "VNSigAllNodes" SG_ 801 FHTObjLy 1;
BA_ "SignalType" SG_ 801 FHTObjLx "SNM";
BA_ "SignalLongName" SG_ 801 FHTObjLx "Forward High Threat Object Location (x-axis)";
BA_ "VNSigAllNodes" SG_ 801 FHTObjLx 1;
BA_ "SignalType" SG_ 801 FHTObjID "UNM";
BA_ "SignalLongName" SG_ 801 FHTObjID "Forward High Threat Object ID";
BA_ "VNSigAllNodes" SG_ 801 FHTObjID 1;
BA_ "SignalType" SG_ 777 Yawrt "SNM";
BA_ "SignalLongName" SG_ 777 Yawrt "Yaw Rate";
BA_ "VNSigAllNodes" SG_ 777 Yawrt 1;
BA_ "SignalType" SG_ 777 VehVel "SNM";
BA_ "SignalLongName" SG_ 777 VehVel "Vehicle Velocity";
BA_ "VNSigAllNodes" SG_ 777 VehVel 1;
BA_ "SignalType" SG_ 777 RHTObjID "UNM";
BA_ "SignalLongName" SG_ 777 RHTObjID "Rear High Threat Object ID";
BA_ "VNSigAllNodes" SG_ 777 RHTObjID 1;
BA_ "SignalType" SG_ 777 RHTObjtmtoclsn "UNM";
BA_ "SignalLongName" SG_ 777 RHTObjtmtoclsn "Rear High Threat Object Time to Collision";
BA_ "VNSigAllNodes" SG_ 777 RHTObjtmtoclsn 1;
BA_ "SignalType" SG_ 777 RHTObjPstn "SNM";
BA_ "SignalLongName" SG_ 777 RHTObjPstn "Rear High Threat Object Position";
BA_ "VNSigAllNodes" SG_ 777 RHTObjPstn 1;
BA_ "VNSigSLHSSharedDiagnostic" SG_ 605 DgnInf 1;
BA_ "SignalType" SG_ 605 DgnInf "UNM";
BA_ "SignalLongName" SG_ 605 DgnInf "Diagnostic Information";
BA_ "VNSigAllNodes" SG_ 605 DgnInf 1;
BA_ "VNSigSLHSSharedDiagnostic" SG_ 1366 DgnInf_FO556 1;
BA_ "SignalType" SG_ 1366 DgnInf_FO556 "UNM";
BA_ "SignalLongName" SG_ 1366 DgnInf_FO556 "Diagnostic Information FO556";
BA_ "VNSigAllNodes" SG_ 1366 DgnInf_FO556 1;
BA_ "VNSigSLHSSharedDiagnostic" SG_ 587 DgnInf 1;
BA_ "SignalType" SG_ 587 DgnInf "UNM";
BA_ "SignalLongName" SG_ 587 DgnInf "Diagnostic Information";
BA_ "VNSigAllNodes" SG_ 587 DgnInf 1;
BA_ "VNSigSLHSSharedDiagnostic" SG_ 1355 DgnInf_OBJ54B 1;
BA_ "SignalType" SG_ 1355 DgnInf_OBJ54B "UNM";
BA_ "SignalLongName" SG_ 1355 DgnInf_OBJ54B "Diagnostic Information OBJ54B";
BA_ "VNSigAllNodes" SG_ 1355 DgnInf_OBJ54B 1;
BA_ "VNSigSLHSSharedDiagnostic" SG_ 1611 DgnInf 1;
BA_ "SignalType" SG_ 1611 DgnInf "UNM";
BA_ "SignalLongName" SG_ 1611 DgnInf "Diagnostic Information";
BA_ "VNSigAllNodes" SG_ 1611 DgnInf 1;
BA_ "SignalType" SG_ 1916 DTCI_DTCFaultType_77C "ENM";
BA_ "PacketOrder" SG_ 1916 DTCI_DTCFaultType_77C 20;
BA_ "SignalLongName" SG_ 1916 DTCI_DTCFaultType_77C "Diagnostic Trouble Code Information Extended 77C : Diagnostic Trouble Code Fault Type";
BA_ "VNSigAllNodes" SG_ 1916 DTCI_DTCFaultType_77C 1;
BA_ "SignalType" SG_ 1916 DTCI_CodeSupported_77C "BLN";
BA_ "PacketOrder" SG_ 1916 DTCI_CodeSupported_77C 19;
BA_ "SignalLongName" SG_ 1916 DTCI_CodeSupported_77C "Diagnostic Trouble Code Information Extended 77C : Code Supported";
BA_ "VNSigAllNodes" SG_ 1916 DTCI_CodeSupported_77C 1;
BA_ "SignalType" SG_ 1916 DTCI_CurrentStatus_77C "BLN";
BA_ "PacketOrder" SG_ 1916 DTCI_CurrentStatus_77C 18;
BA_ "SignalLongName" SG_ 1916 DTCI_CurrentStatus_77C "Diagnostic Trouble Code Information Extended 77C : Current Status";
BA_ "VNSigAllNodes" SG_ 1916 DTCI_CurrentStatus_77C 1;
BA_ "SignalType" SG_ 1916 DTCI_TstNPsdCdClrdSt_77C "BLN";
BA_ "PacketOrder" SG_ 1916 DTCI_TstNPsdCdClrdSt_77C 17;
BA_ "SignalLongName" SG_ 1916 DTCI_TstNPsdCdClrdSt_77C "Diagnostic Trouble Code Information Extended 77C : Test Not Passed Since Code Cleared Status";
BA_ "VNSigAllNodes" SG_ 1916 DTCI_TstNPsdCdClrdSt_77C 1;
BA_ "SignalType" SG_ 1916 DTCI_TstFldCdClrdStat_77C "BLN";
BA_ "PacketOrder" SG_ 1916 DTCI_TstFldCdClrdStat_77C 16;
BA_ "SignalLongName" SG_ 1916 DTCI_TstFldCdClrdStat_77C "Diagnostic Trouble Code Information Extended 77C : Test Failed Since Code Cleared Status";
BA_ "VNSigAllNodes" SG_ 1916 DTCI_TstFldCdClrdStat_77C 1;
BA_ "SignalType" SG_ 1916 DTCI_HistStat_77C "BLN";
BA_ "PacketOrder" SG_ 1916 DTCI_HistStat_77C 15;
BA_ "SignalLongName" SG_ 1916 DTCI_HistStat_77C "Diagnostic Trouble Code Information Extended 77C : History Status";
BA_ "VNSigAllNodes" SG_ 1916 DTCI_HistStat_77C 1;
BA_ "SignalType" SG_ 1916 DTCI_TstNPsdPwrUpSt_77C "BLN";
BA_ "PacketOrder" SG_ 1916 DTCI_TstNPsdPwrUpSt_77C 14;
BA_ "SignalLongName" SG_ 1916 DTCI_TstNPsdPwrUpSt_77C "Diagnostic Trouble Code Information Extended 77C : Test Not Passed Since Power Up Status";
BA_ "VNSigAllNodes" SG_ 1916 DTCI_TstNPsdPwrUpSt_77C 1;
BA_ "SignalType" SG_ 1916 DTCI_TstFldPwrUpSt_77C "BLN";
BA_ "PacketOrder" SG_ 1916 DTCI_TstFldPwrUpSt_77C 13;
BA_ "SignalLongName" SG_ 1916 DTCI_TstFldPwrUpSt_77C "Diagnostic Trouble Code Information Extended 77C : Test Failed Since Power Up Status";
BA_ "VNSigAllNodes" SG_ 1916 DTCI_TstFldPwrUpSt_77C 1;
BA_ "SignalType" SG_ 1916 DTCI_WrnIndRqdSt_77C "BLN";
BA_ "PacketOrder" SG_ 1916 DTCI_WrnIndRqdSt_77C 12;
BA_ "SignalLongName" SG_ 1916 DTCI_WrnIndRqdSt_77C "Diagnostic Trouble Code Information Extended 77C : Warning Indicator Requested Status";
BA_ "VNSigAllNodes" SG_ 1916 DTCI_WrnIndRqdSt_77C 1;
BA_ "SignalType" SG_ 1916 DTCI_DTCFailType_77C "UNM";
BA_ "PacketOrder" SG_ 1916 DTCI_DTCFailType_77C 11;
BA_ "SignalLongName" SG_ 1916 DTCI_DTCFailType_77C "Diagnostic Trouble Code Information Extended 77C : Diagnostic Trouble Code Failure Type";
BA_ "VNSigAllNodes" SG_ 1916 DTCI_DTCFailType_77C 1;
BA_ "SignalType" SG_ 1916 DTCI_DTCNumber_77C "UNM";
BA_ "PacketOrder" SG_ 1916 DTCI_DTCNumber_77C 10;
BA_ "SignalLongName" SG_ 1916 DTCI_DTCNumber_77C "Diagnostic Trouble Code Information Extended 77C : Diagnostic Trouble Code Number";
BA_ "VNSigAllNodes" SG_ 1916 DTCI_DTCNumber_77C 1;
BA_ "SignalType" SG_ 1916 DTCI_DTCSource_77C "UNM";
BA_ "PacketOrder" SG_ 1916 DTCI_DTCSource_77C 9;
BA_ "SignalLongName" SG_ 1916 DTCI_DTCSource_77C "Diagnostic Trouble Code Information Extended 77C : Diagnostic Trouble Code Source";
BA_ "VNSigAllNodes" SG_ 1916 DTCI_DTCSource_77C 1;
BA_ "SignalType" SG_ 1916 DTCI_DTCTriggered_77C "BLN";
BA_ "PacketOrder" SG_ 1916 DTCI_DTCTriggered_77C 8;
BA_ "SignalLongName" SG_ 1916 DTCI_DTCTriggered_77C "Diagnostic Trouble Code Information Extended 77C : Diagnostic Trouble Code Triggered";
BA_ "VNSigAllNodes" SG_ 1916 DTCI_DTCTriggered_77C 1;
BA_ "SignalType" SG_ 1916 DTCIUnused7_77C "BLN";
BA_ "PacketOrder" SG_ 1916 DTCIUnused7_77C 7;
BA_ "SignalLongName" SG_ 1916 DTCIUnused7_77C "Diagnostic Trouble Code Information Extended 77C : Unused 7";
BA_ "VNSigAllNodes" SG_ 1916 DTCIUnused7_77C 1;
BA_ "SignalType" SG_ 1916 DTCIUnused6_77C "BLN";
BA_ "PacketOrder" SG_ 1916 DTCIUnused6_77C 6;
BA_ "SignalLongName" SG_ 1916 DTCIUnused6_77C "Diagnostic Trouble Code Information Extended 77C : Unused 6";
BA_ "VNSigAllNodes" SG_ 1916 DTCIUnused6_77C 1;
BA_ "SignalType" SG_ 1916 DTCIUnused5_77C "BLN";
BA_ "PacketOrder" SG_ 1916 DTCIUnused5_77C 5;
BA_ "SignalLongName" SG_ 1916 DTCIUnused5_77C "Diagnostic Trouble Code Information Extended 77C : Unused 5";
BA_ "VNSigAllNodes" SG_ 1916 DTCIUnused5_77C 1;
BA_ "SignalType" SG_ 1916 DTCIUnused4_77C "BLN";
BA_ "PacketOrder" SG_ 1916 DTCIUnused4_77C 4;
BA_ "SignalLongName" SG_ 1916 DTCIUnused4_77C "Diagnostic Trouble Code Information Extended 77C : Unused 4";
BA_ "VNSigAllNodes" SG_ 1916 DTCIUnused4_77C 1;
BA_ "SignalType" SG_ 1916 DTCIUnused3_77C "BLN";
BA_ "PacketOrder" SG_ 1916 DTCIUnused3_77C 3;
BA_ "SignalLongName" SG_ 1916 DTCIUnused3_77C "Diagnostic Trouble Code Information Extended 77C : Unused 3";
BA_ "VNSigAllNodes" SG_ 1916 DTCIUnused3_77C 1;
BA_ "SignalType" SG_ 1916 DTCIUnused2_77C "BLN";
BA_ "PacketOrder" SG_ 1916 DTCIUnused2_77C 2;
BA_ "SignalLongName" SG_ 1916 DTCIUnused2_77C "Diagnostic Trouble Code Information Extended 77C : Unused 2";
BA_ "VNSigAllNodes" SG_ 1916 DTCIUnused2_77C 1;
BA_ "SignalType" SG_ 1916 DTCIUnused1_77C "BLN";
BA_ "PacketOrder" SG_ 1916 DTCIUnused1_77C 1;
BA_ "SignalLongName" SG_ 1916 DTCIUnused1_77C "Diagnostic Trouble Code Information Extended 77C : Unused 1";
BA_ "VNSigAllNodes" SG_ 1916 DTCIUnused1_77C 1;
BA_ "SignalType" SG_ 1365 DgnInf_OBJ555 "UNM";
BA_ "SignalLongName" SG_ 1365 DgnInf_OBJ555 "Diagnostic Information OBJ555";
BA_ "VNSigAllNodes" SG_ 1365 DgnInf_OBJ555 1;
BA_ "VNSigSLHSSharedDiagnostic" SG_ 2034 DgnInf 1;
BA_ "SignalType" SG_ 2034 DgnInf "UNM";
BA_ "SignalLongName" SG_ 2034 DgnInf "Diagnostic Information";
BA_ "VNSigAllNodes" SG_ 2034 DgnInf 1;
BA_ "VNSigSLHSSharedDiagnostic" SG_ 2032 DgnInf 1;
BA_ "SignalType" SG_ 2032 DgnInf "UNM";
BA_ "SignalLongName" SG_ 2032 DgnInf "Diagnostic Information";
BA_ "VNSigAllNodes" SG_ 2032 DgnInf 1;
BA_ "VNSigSLHSSharedDiagnostic" SG_ 1604 DgnInf 1;
BA_ "SignalType" SG_ 1604 DgnInf "UNM";
BA_ "SignalLongName" SG_ 1604 DgnInf "Diagnostic Information";
BA_ "VNSigAllNodes" SG_ 1604 DgnInf 1;
BA_ "VNSigSLHSSharedDiagnostic" SG_ 1608 DgnInf 1;
BA_ "SignalType" SG_ 1608 DgnInf "UNM";
BA_ "SignalLongName" SG_ 1608 DgnInf "Diagnostic Information";
BA_ "VNSigAllNodes" SG_ 1608 DgnInf 1;
BA_ "SignalType" SG_ 1348 DgnInf_OBJ544 "UNM";
BA_ "SignalLongName" SG_ 1348 DgnInf_OBJ544 "Diagnostic Information OBJ544";
BA_ "VNSigAllNodes" SG_ 1348 DgnInf_OBJ544 1;
BA_ "VNSigSLHSSharedDiagnostic" SG_ 1352 DgnInf_OBJ548 1;
BA_ "SignalType" SG_ 1352 DgnInf_OBJ548 "UNM";
BA_ "SignalLongName" SG_ 1352 DgnInf_OBJ548 "Diagnostic Information OBJ548";
BA_ "VNSigAllNodes" SG_ 1352 DgnInf_OBJ548 1;
BA_ "SignalType" SG_ 1929 DTCI_CodeSupported_789 "BLN";
BA_ "PacketOrder" SG_ 1929 DTCI_CodeSupported_789 19;
BA_ "SignalLongName" SG_ 1929 DTCI_CodeSupported_789 "Diagnostic Trouble Code Information Extended 789 : Code Supported";
BA_ "VNSigAllNodes" SG_ 1929 DTCI_CodeSupported_789 1;
BA_ "SignalType" SG_ 1929 DTCI_CurrentStatus_789 "BLN";
BA_ "PacketOrder" SG_ 1929 DTCI_CurrentStatus_789 18;
BA_ "SignalLongName" SG_ 1929 DTCI_CurrentStatus_789 "Diagnostic Trouble Code Information Extended 789 : Current Status";
BA_ "VNSigAllNodes" SG_ 1929 DTCI_CurrentStatus_789 1;
BA_ "SignalType" SG_ 1929 DTCI_DTCFailType_789 "UNM";
BA_ "PacketOrder" SG_ 1929 DTCI_DTCFailType_789 11;
BA_ "SignalLongName" SG_ 1929 DTCI_DTCFailType_789 "Diagnostic Trouble Code Information Extended 789 : Diagnostic Trouble Code Failure Type";
BA_ "VNSigAllNodes" SG_ 1929 DTCI_DTCFailType_789 1;
BA_ "SignalType" SG_ 1929 DTCI_DTCFaultType_789 "ENM";
BA_ "PacketOrder" SG_ 1929 DTCI_DTCFaultType_789 20;
BA_ "SignalLongName" SG_ 1929 DTCI_DTCFaultType_789 "Diagnostic Trouble Code Information Extended 789 : Diagnostic Trouble Code Fault Type";
BA_ "VNSigAllNodes" SG_ 1929 DTCI_DTCFaultType_789 1;
BA_ "SignalType" SG_ 1929 DTCI_DTCNumber_789 "UNM";
BA_ "PacketOrder" SG_ 1929 DTCI_DTCNumber_789 10;
BA_ "SignalLongName" SG_ 1929 DTCI_DTCNumber_789 "Diagnostic Trouble Code Information Extended 789 : Diagnostic Trouble Code Number";
BA_ "VNSigAllNodes" SG_ 1929 DTCI_DTCNumber_789 1;
BA_ "SignalType" SG_ 1929 DTCI_DTCSource_789 "UNM";
BA_ "PacketOrder" SG_ 1929 DTCI_DTCSource_789 9;
BA_ "SignalLongName" SG_ 1929 DTCI_DTCSource_789 "Diagnostic Trouble Code Information Extended 789 : Diagnostic Trouble Code Source";
BA_ "VNSigAllNodes" SG_ 1929 DTCI_DTCSource_789 1;
BA_ "SignalType" SG_ 1929 DTCI_DTCTriggered_789 "BLN";
BA_ "PacketOrder" SG_ 1929 DTCI_DTCTriggered_789 8;
BA_ "SignalLongName" SG_ 1929 DTCI_DTCTriggered_789 "Diagnostic Trouble Code Information Extended 789 : Diagnostic Trouble Code Triggered";
BA_ "VNSigAllNodes" SG_ 1929 DTCI_DTCTriggered_789 1;
BA_ "SignalType" SG_ 1929 DTCI_HistStat_789 "BLN";
BA_ "PacketOrder" SG_ 1929 DTCI_HistStat_789 15;
BA_ "SignalLongName" SG_ 1929 DTCI_HistStat_789 "Diagnostic Trouble Code Information Extended 789 : History Status";
BA_ "VNSigAllNodes" SG_ 1929 DTCI_HistStat_789 1;
BA_ "SignalType" SG_ 1929 DTCI_TstFldCdClrdStat_789 "BLN";
BA_ "PacketOrder" SG_ 1929 DTCI_TstFldCdClrdStat_789 16;
BA_ "SignalLongName" SG_ 1929 DTCI_TstFldCdClrdStat_789 "Diagnostic Trouble Code Information Extended 789 : Test Failed Since Code Cleared Status";
BA_ "VNSigAllNodes" SG_ 1929 DTCI_TstFldCdClrdStat_789 1;
BA_ "SignalType" SG_ 1929 DTCI_TstFldPwrUpSt_789 "BLN";
BA_ "PacketOrder" SG_ 1929 DTCI_TstFldPwrUpSt_789 13;
BA_ "SignalLongName" SG_ 1929 DTCI_TstFldPwrUpSt_789 "Diagnostic Trouble Code Information Extended 789 : Test Failed Since Power Up Status";
BA_ "VNSigAllNodes" SG_ 1929 DTCI_TstFldPwrUpSt_789 1;
BA_ "SignalType" SG_ 1929 DTCI_TstNPsdCdClrdSt_789 "BLN";
BA_ "PacketOrder" SG_ 1929 DTCI_TstNPsdCdClrdSt_789 17;
BA_ "SignalLongName" SG_ 1929 DTCI_TstNPsdCdClrdSt_789 "Diagnostic Trouble Code Information Extended 789 : Test Not Passed Since Code Cleared Status";
BA_ "VNSigAllNodes" SG_ 1929 DTCI_TstNPsdCdClrdSt_789 1;
BA_ "SignalType" SG_ 1929 DTCI_TstNPsdPwrUpSt_789 "BLN";
BA_ "PacketOrder" SG_ 1929 DTCI_TstNPsdPwrUpSt_789 14;
BA_ "SignalLongName" SG_ 1929 DTCI_TstNPsdPwrUpSt_789 "Diagnostic Trouble Code Information Extended 789 : Test Not Passed Since Power Up Status";
BA_ "VNSigAllNodes" SG_ 1929 DTCI_TstNPsdPwrUpSt_789 1;
BA_ "SignalType" SG_ 1929 DTCIUnused1_789 "BLN";
BA_ "PacketOrder" SG_ 1929 DTCIUnused1_789 1;
BA_ "SignalLongName" SG_ 1929 DTCIUnused1_789 "Diagnostic Trouble Code Information Extended 789 : Unused 1";
BA_ "VNSigAllNodes" SG_ 1929 DTCIUnused1_789 1;
BA_ "SignalType" SG_ 1929 DTCIUnused2_789 "BLN";
BA_ "PacketOrder" SG_ 1929 DTCIUnused2_789 2;
BA_ "SignalLongName" SG_ 1929 DTCIUnused2_789 "Diagnostic Trouble Code Information Extended 789 : Unused 2";
BA_ "VNSigAllNodes" SG_ 1929 DTCIUnused2_789 1;
BA_ "SignalType" SG_ 1929 DTCIUnused3_789 "BLN";
BA_ "PacketOrder" SG_ 1929 DTCIUnused3_789 3;
BA_ "SignalLongName" SG_ 1929 DTCIUnused3_789 "Diagnostic Trouble Code Information Extended 789 : Unused 3";
BA_ "VNSigAllNodes" SG_ 1929 DTCIUnused3_789 1;
BA_ "SignalType" SG_ 1929 DTCIUnused4_789 "BLN";
BA_ "PacketOrder" SG_ 1929 DTCIUnused4_789 4;
BA_ "SignalLongName" SG_ 1929 DTCIUnused4_789 "Diagnostic Trouble Code Information Extended 789 : Unused 4";
BA_ "VNSigAllNodes" SG_ 1929 DTCIUnused4_789 1;
BA_ "SignalType" SG_ 1929 DTCIUnused5_789 "BLN";
BA_ "PacketOrder" SG_ 1929 DTCIUnused5_789 5;
BA_ "SignalLongName" SG_ 1929 DTCIUnused5_789 "Diagnostic Trouble Code Information Extended 789 : Unused 5";
BA_ "VNSigAllNodes" SG_ 1929 DTCIUnused5_789 1;
BA_ "SignalType" SG_ 1929 DTCIUnused6_789 "BLN";
BA_ "PacketOrder" SG_ 1929 DTCIUnused6_789 6;
BA_ "SignalLongName" SG_ 1929 DTCIUnused6_789 "Diagnostic Trouble Code Information Extended 789 : Unused 6";
BA_ "VNSigAllNodes" SG_ 1929 DTCIUnused6_789 1;
BA_ "SignalType" SG_ 1929 DTCIUnused7_789 "BLN";
BA_ "PacketOrder" SG_ 1929 DTCIUnused7_789 7;
BA_ "SignalLongName" SG_ 1929 DTCIUnused7_789 "Diagnostic Trouble Code Information Extended 789 : Unused 7";
BA_ "VNSigAllNodes" SG_ 1929 DTCIUnused7_789 1;
BA_ "SignalType" SG_ 1929 DTCI_WrnIndRqdSt_789 "BLN";
BA_ "PacketOrder" SG_ 1929 DTCI_WrnIndRqdSt_789 12;
BA_ "SignalLongName" SG_ 1929 DTCI_WrnIndRqdSt_789 "Diagnostic Trouble Code Information Extended 789 : Warning Indicator Requested Status";
BA_ "VNSigAllNodes" SG_ 1929 DTCI_WrnIndRqdSt_789 1;
BA_ "VNSigSLHSSharedDiagnostic" SG_ 1622 DgnInf 1;
BA_ "SignalType" SG_ 1622 DgnInf "UNM";
BA_ "SignalLongName" SG_ 1622 DgnInf "Diagnostic Information";
BA_ "VNSigAllNodes" SG_ 1622 DgnInf 1;
BA_ "VNSigSLHSSharedDiagnostic" SG_ 597 DgnInf 1;
BA_ "SignalType" SG_ 597 DgnInf "UNM";
BA_ "SignalLongName" SG_ 597 DgnInf "Diagnostic Information";
BA_ "VNSigAllNodes" SG_ 597 DgnInf 1;
BA_ "VNSigSLHSSharedDiagnostic" SG_ 580 DgnInf 1;
BA_ "SignalType" SG_ 580 DgnInf "UNM";
BA_ "SignalLongName" SG_ 580 DgnInf "Diagnostic Information";
BA_ "VNSigAllNodes" SG_ 580 DgnInf 1;
BA_ "SignalType" SG_ 344 CSS_CoPilotCibAvail "BLN";
BA_ "SignalLongName" SG_ 344 CSS_CoPilotCibAvail "CoPilot System Status : CoPilot Collision Imminent Braking Available";
BA_ "VNSigAllNodes" SG_ 344 CSS_CoPilotCibAvail 1;
BA_ "SignalType" SG_ 344 CSS_CoPilotSysFltStat "ENM";
BA_ "SignalLongName" SG_ 344 CSS_CoPilotSysFltStat "CoPilot System Status : CoPilot System Fault Status";
BA_ "VNSigAllNodes" SG_ 344 CSS_CoPilotSysFltStat 1;
BA_ "SignalType" SG_ 344 CSS_CoPilotRvbAvail "BLN";
BA_ "SignalLongName" SG_ 344 CSS_CoPilotRvbAvail "CoPilot System Status : CoPilot Rear Virtual Bumper Available";
BA_ "VNSigAllNodes" SG_ 344 CSS_CoPilotRvbAvail 1;
BA_ "SignalType" SG_ 344 CSS_CoPilotPcmAvail "BLN";
BA_ "SignalLongName" SG_ 344 CSS_CoPilotPcmAvail "CoPilot System Status : CoPilot Pedestrian Collision Mitigation Available";
BA_ "VNSigAllNodes" SG_ 344 CSS_CoPilotPcmAvail 1;
BA_ "SignalType" SG_ 344 CSS_CoPilotFcaAvail "BLN";
BA_ "SignalLongName" SG_ 344 CSS_CoPilotFcaAvail "CoPilot System Status : CoPilot Forward Collision Alert Available";
BA_ "VNSigAllNodes" SG_ 344 CSS_CoPilotFcaAvail 1;
BA_ "SignalType" SG_ 344 CSS_CoPilotBrkExpctd "BLN";
BA_ "SignalLongName" SG_ 344 CSS_CoPilotBrkExpctd "CoPilot System Status : CoPilot Braking Expected";
BA_ "VNSigAllNodes" SG_ 344 CSS_CoPilotBrkExpctd 1;
BA_ "SignalType" SG_ 344 CoPilotSysStatInfoChcksm "UNM";
BA_ "SignalLongName" SG_ 344 CoPilotSysStatInfoChcksm "CoPilot System Status Info Checksum";
BA_ "VNSigAllNodes" SG_ 344 CoPilotSysStatInfoChcksm 1;
BA_ "SignalType" SG_ 344 CoPilotSysStatInfoARC "UNM";
BA_ "SignalLongName" SG_ 344 CoPilotSysStatInfoARC "CoPilot System Status Info Alive Rolling Count";
BA_ "VNSigAllNodes" SG_ 344 CoPilotSysStatInfoARC 1;
BA_ "SignalType" SG_ 344 StrgAngTrqBsdEstSrfcMuConf "ENM";
BA_ "SignalLongName" SG_ 344 StrgAngTrqBsdEstSrfcMuConf "Steering Angle Torque Based Estimated Surface Mu Confidence";
BA_ "VNSigAllNodes" SG_ 344 StrgAngTrqBsdEstSrfcMuConf 1;
BA_ "SignalType" SG_ 344 StrgAngTrqBsdEstSrfcMuCapV "ENM";
BA_ "SignalLongName" SG_ 344 StrgAngTrqBsdEstSrfcMuCapV "Steering Angle Torque Based Estimated Surface Mu Capacity Validity";
BA_ "VNSigAllNodes" SG_ 344 StrgAngTrqBsdEstSrfcMuCapV 1;
BA_ "SignalType" SG_ 344 StrgAngTrqBsdEstSrfcMuCap "UNM";
BA_ "SignalLongName" SG_ 344 StrgAngTrqBsdEstSrfcMuCap "Steering Angle Torque Based Estimated Surface Mu Capacity";
BA_ "VNSigAllNodes" SG_ 344 StrgAngTrqBsdEstSrfcMuCap 1;
BA_ "SignalType" SG_ 344 LatVlctyBsdSrfcMuCap "UNM";
BA_ "SignalLongName" SG_ 344 LatVlctyBsdSrfcMuCap "Lateral Velocity Based Surface Mu Capacity";
BA_ "VNSigAllNodes" SG_ 344 LatVlctyBsdSrfcMuCap 1;
BA_ "VNSigSLHSSharedDiagnostic" SG_ 1605 DgnInf 1;
BA_ "SignalType" SG_ 1605 DgnInf "UNM";
BA_ "SignalLongName" SG_ 1605 DgnInf "Diagnostic Information";
BA_ "VNSigAllNodes" SG_ 1605 DgnInf 1;
BA_ "VNSigSLHSSharedDiagnostic" SG_ 598 DgnInf 1;
BA_ "SignalType" SG_ 598 DgnInf "UNM";
BA_ "SignalLongName" SG_ 598 DgnInf "Diagnostic Information";
BA_ "VNSigAllNodes" SG_ 598 DgnInf 1;
BA_ "VNSigSLHSSharedDiagnostic" SG_ 1349 DgnInf_FO545 1;
BA_ "SignalType" SG_ 1349 DgnInf_FO545 "UNM";
BA_ "SignalLongName" SG_ 1349 DgnInf_FO545 "Diagnostic Information FO545";
BA_ "VNSigAllNodes" SG_ 1349 DgnInf_FO545 1;
BA_ "VNSigSLHSSharedDiagnostic" SG_ 584 DgnInf 1;
BA_ "SignalType" SG_ 584 DgnInf "UNM";
BA_ "SignalLongName" SG_ 584 DgnInf "Diagnostic Information";
BA_ "VNSigAllNodes" SG_ 584 DgnInf 1;
BA_ "SignalType" SG_ 770 Vpath_Accel "SNM";
BA_ "SignalLongName" SG_ 770 Vpath_Accel "Vehicle Path Acceleration";
BA_ "VNSigAllNodes" SG_ 770 Vpath_Accel 1;
BA_ "SignalType" SG_ 770 FCA_Ra "SNM";
BA_ "SignalLongName" SG_ 770 FCA_Ra "FCA Ra";
BA_ "VNSigAllNodes" SG_ 770 FCA_Ra 1;
BA_ "SignalType" SG_ 770 FCA_Range "SNM";
BA_ "SignalLongName" SG_ 770 FCA_Range "FCA Range";
BA_ "VNSigAllNodes" SG_ 770 FCA_Range 1;
BA_ "SignalType" SG_ 770 FCA_AlertLevel "UNM";
BA_ "SignalLongName" SG_ 770 FCA_AlertLevel "FCA Alert level";
BA_ "VNSigAllNodes" SG_ 770 FCA_AlertLevel 1;
BA_ "SignalType" SG_ 770 FCA_Alert_Sup "UNM";
BA_ "SignalLongName" SG_ 770 FCA_Alert_Sup "FCA Alert Suppresion";
BA_ "VNSigAllNodes" SG_ 770 FCA_Alert_Sup 1;
BA_ "SignalType" SG_ 770 FCAStatus "UNM";
BA_ "SignalLongName" SG_ 770 FCAStatus "FCA Status";
BA_ "VNSigAllNodes" SG_ 770 FCAStatus 1;
BA_ "SignalType" SG_ 770 FCA_VehAhead "UNM";
BA_ "SignalLongName" SG_ 770 FCA_VehAhead "FCA Vehicle Ahead";
BA_ "VNSigAllNodes" SG_ 770 FCA_VehAhead 1;
BA_ "SignalType" SG_ 770 FCA_CPS_Alert "UNM";
BA_ "SignalLongName" SG_ 770 FCA_CPS_Alert "FCA CPS Alert";
BA_ "VNSigAllNodes" SG_ 770 FCA_CPS_Alert 1;
BA_ "SignalType" SG_ 770 FCAChime "UNM";
BA_ "SignalLongName" SG_ 770 FCAChime "FCA Chime";
BA_ "VNSigAllNodes" SG_ 770 FCAChime 1;
BA_ "SignalType" SG_ 770 FCADiagOK "UNM";
BA_ "SignalLongName" SG_ 770 FCADiagOK "FCA Diagnostics OK";
BA_ "VNSigAllNodes" SG_ 770 FCADiagOK 1;
BA_ "SignalType" SG_ 770 NBSMS_Alert "UNM";
BA_ "SignalLongName" SG_ 770 NBSMS_Alert "NBMS Alert";
BA_ "VNSigAllNodes" SG_ 770 NBSMS_Alert 1;
BA_ "SignalType" SG_ 161 FTimeSyncMstrClockV "ENM";
BA_ "SignalLongName" SG_ 161 FTimeSyncMstrClockV "Front Time Sync Master Clock Validity";
BA_ "VNSigAllNodes" SG_ 161 FTimeSyncMstrClockV 1;
BA_ "SignalType" SG_ 161 SensorModeCmdFCamera "ENM";
BA_ "SignalLongName" SG_ 161 SensorModeCmdFCamera "Sensor Mode Command Front Camera";
BA_ "VNSigAllNodes" SG_ 161 SensorModeCmdFCamera 1;
BA_ "SignalType" SG_ 161 SensorModeCmdSRR "ENM";
BA_ "SignalLongName" SG_ 161 SensorModeCmdSRR "Sensor Mode Command Short Range Radar";
BA_ "VNSigAllNodes" SG_ 161 SensorModeCmdSRR 1;
BA_ "SignalType" SG_ 161 SensorModeCmdLRR "ENM";
BA_ "SignalLongName" SG_ 161 SensorModeCmdLRR "Front Long Range Sensor Mode Command";
BA_ "VNSigAllNodes" SG_ 161 SensorModeCmdLRR 1;
BA_ "SignalType" SG_ 161 FTimeSyncMstrClock "UNM";
BA_ "SignalLongName" SG_ 161 FTimeSyncMstrClock "Front Time Sync Master Clock";
BA_ "VNSigAllNodes" SG_ 161 FTimeSyncMstrClock 1;
BA_ "SignalType" SG_ 161 FTimeSyncMstrChksm "UNM";
BA_ "SignalLongName" SG_ 161 FTimeSyncMstrChksm "Front Time Sync Master Clock Checksum";
BA_ "VNSigAllNodes" SG_ 161 FTimeSyncMstrChksm 1;
BA_ "SignalType" SG_ 776 Vpath_Data2ModeInfo "ENM";
BA_ "SignalLongName" SG_ 776 Vpath_Data2ModeInfo "Vehicle Path Data 2 Mode Information";
BA_ "VNSigAllNodes" SG_ 776 Vpath_Data2ModeInfo 1;
BA_ "SignalType" SG_ 776 Vpath2_Checksum "UNM";
BA_ "SignalLongName" SG_ 776 Vpath2_Checksum "Vehicle Path Data 2 Checksum";
BA_ "VNSigAllNodes" SG_ 776 Vpath2_Checksum 1;
BA_ "SignalType" SG_ 776 Vpath_Data2RollCnt "UNM";
BA_ "SignalLongName" SG_ 776 Vpath_Data2RollCnt "Vehicle Path Data 2 Rolling Count";
BA_ "VNSigAllNodes" SG_ 776 Vpath_Data2RollCnt 1;
BA_ "SignalType" SG_ 776 Vpath_Data2YawRateV "ENM";
BA_ "SignalLongName" SG_ 776 Vpath_Data2YawRateV "Vehicle Path Data 2 Yaw Rate Validity";
BA_ "VNSigAllNodes" SG_ 776 Vpath_Data2YawRateV 1;
BA_ "SignalType" SG_ 776 Vpath_Data2LongVelV "ENM";
BA_ "SignalLongName" SG_ 776 Vpath_Data2LongVelV "Vehicle Path Data 2 Longitudinal Velocity Validity";
BA_ "VNSigAllNodes" SG_ 776 Vpath_Data2LongVelV 1;
BA_ "SignalType" SG_ 776 Vpath_Data2LatVelV "ENM";
BA_ "SignalLongName" SG_ 776 Vpath_Data2LatVelV "Vehicle Path Data 2 Lateral Velocity Validity";
BA_ "VNSigAllNodes" SG_ 776 Vpath_Data2LatVelV 1;
BA_ "SignalType" SG_ 776 Vpath_Data2TravlDirctn "ENM";
BA_ "SignalLongName" SG_ 776 Vpath_Data2TravlDirctn "Vehicle Path Data 2 Travel Direction";
BA_ "VNSigAllNodes" SG_ 776 Vpath_Data2TravlDirctn 1;
BA_ "SignalType" SG_ 776 Vpath_Data2LongVel "SNM";
BA_ "SignalLongName" SG_ 776 Vpath_Data2LongVel "Vehicle Path Data 2 Longitudinal Velocity";
BA_ "VNSigAllNodes" SG_ 776 Vpath_Data2LongVel 1;
BA_ "SignalType" SG_ 776 Vpath_Data2YawRate "SNM";
BA_ "SignalLongName" SG_ 776 Vpath_Data2YawRate "Vehicle Path Data 2 Yaw Rate";
BA_ "VNSigAllNodes" SG_ 776 Vpath_Data2YawRate 1;
BA_ "SignalType" SG_ 776 Vpath_Data2LatVel "SNM";
BA_ "SignalLongName" SG_ 776 Vpath_Data2LatVel "Vehicle Path Data 2 Lateral Velocity";
BA_ "VNSigAllNodes" SG_ 776 Vpath_Data2LatVel 1;
BA_ "SignalType" SG_ 774 Vpath_RollingCount "UNM";
BA_ "SignalLongName" SG_ 774 Vpath_RollingCount "Vehicle Path Rolling Count";
BA_ "VNSigAllNodes" SG_ 774 Vpath_RollingCount 1;
BA_ "SignalType" SG_ 774 Vpath_TrnCtrLngOfstV "ENM";
BA_ "SignalLongName" SG_ 774 Vpath_TrnCtrLngOfstV "Vehicle Path Turn Center Longitudinal Offset Validity";
BA_ "VNSigAllNodes" SG_ 774 Vpath_TrnCtrLngOfstV 1;
BA_ "SignalType" SG_ 774 Vpath_Checksum "UNM";
BA_ "SignalLongName" SG_ 774 Vpath_Checksum "Vehicle Path Checksum";
BA_ "VNSigAllNodes" SG_ 774 Vpath_Checksum 1;
BA_ "SignalType" SG_ 774 Vpath_TrnCtrLngOfst "SNM";
BA_ "SignalLongName" SG_ 774 Vpath_TrnCtrLngOfst "Vehicle Path Turn Center Longitudinal Offset";
BA_ "VNSigAllNodes" SG_ 774 Vpath_TrnCtrLngOfst 1;
BA_ "SignalType" SG_ 774 Vpath_TrnCtrLatOfst "SNM";
BA_ "SignalLongName" SG_ 774 Vpath_TrnCtrLatOfst "Vehcile Path Turn Center Lateral Offset";
BA_ "VNSigAllNodes" SG_ 774 Vpath_TrnCtrLatOfst 1;
BA_ "SignalType" SG_ 774 Vpath_Curvature "SNM";
BA_ "SignalLongName" SG_ 774 Vpath_Curvature "Vehicle Path Curvature";
BA_ "VNSigAllNodes" SG_ 774 Vpath_Curvature 1;
BA_ "SignalType" SG_ 774 Vpath_CurvatureV "ENM";
BA_ "SignalLongName" SG_ 774 Vpath_CurvatureV "Vehicle Path Curvature Validity";
BA_ "VNSigAllNodes" SG_ 774 Vpath_CurvatureV 1;
BA_ "SignalType" SG_ 768 SmgrMotRollAngle "SNM";
BA_ "SignalLongName" SG_ 768 SmgrMotRollAngle "Sensor Manager Motion Roll Angle";
BA_ "VNSigAllNodes" SG_ 768 SmgrMotRollAngle 1;
BA_ "SignalType" SG_ 768 SmgrMotRollAngleV "ENM";
BA_ "SignalLongName" SG_ 768 SmgrMotRollAngleV "Sensor Manager Motion Roll Angle Validity";
BA_ "VNSigAllNodes" SG_ 768 SmgrMotRollAngleV 1;
BA_ "SignalType" SG_ 768 SmgrMotChecksum "UNM";
BA_ "SignalLongName" SG_ 768 SmgrMotChecksum "Sensor Manager Motion Checksum";
BA_ "VNSigAllNodes" SG_ 768 SmgrMotChecksum 1;
BA_ "SignalType" SG_ 768 SmgrMotPitchAngle "SNM";
BA_ "SignalLongName" SG_ 768 SmgrMotPitchAngle "Sensor Manager Motion Pitch Angle";
BA_ "VNSigAllNodes" SG_ 768 SmgrMotPitchAngle 1;
BA_ "SignalType" SG_ 768 SmgrMotPitchAngleV "ENM";
BA_ "SignalLongName" SG_ 768 SmgrMotPitchAngleV "Sensor Manager Motion Pitch Angle Validity";
BA_ "VNSigAllNodes" SG_ 768 SmgrMotPitchAngleV 1;
BA_ "SignalType" SG_ 768 SmgrMotLongSpeedV "ENM";
BA_ "SignalLongName" SG_ 768 SmgrMotLongSpeedV "Sensor Manager Motion Longitudinal Speed Validity";
BA_ "VNSigAllNodes" SG_ 768 SmgrMotLongSpeedV 1;
BA_ "SignalType" SG_ 768 SmgrMotLongSpeed "SNM";
BA_ "SignalLongName" SG_ 768 SmgrMotLongSpeed "Sensor Manager Motion Longitudinal Speed";
BA_ "VNSigAllNodes" SG_ 768 SmgrMotLongSpeed 1;
BA_ "SignalType" SG_ 768 SmgrMotYawRate "SNM";
BA_ "SignalLongName" SG_ 768 SmgrMotYawRate "Sensor Manager Motion Yaw Rate";
BA_ "VNSigAllNodes" SG_ 768 SmgrMotYawRate 1;
BA_ "SignalType" SG_ 768 SmgrMotYawRateV "ENM";
BA_ "SignalLongName" SG_ 768 SmgrMotYawRateV "Sensor Manager Motion Yaw Rate Validity";
BA_ "VNSigAllNodes" SG_ 768 SmgrMotYawRateV 1;
BA_ "SignalType" SG_ 768 SmgrMotRollingCnt "UNM";
BA_ "SignalLongName" SG_ 768 SmgrMotRollingCnt "Sensor Manager Motion Rolling Count";
BA_ "VNSigAllNodes" SG_ 768 SmgrMotRollingCnt 1;
BA_ "SignalType" SG_ 264 InrtlSnsrMstrTrgrSync "UNM";
BA_ "SignalLongName" SG_ 264 InrtlSnsrMstrTrgrSync "Inertial Sensor Master Trigger Synchronization";
BA_ "VNSigAllNodes" SG_ 264 InrtlSnsrMstrTrgrSync 1;
BA_ "VNSigSLHSSharedDiagnostic" SG_ 586 DgnInf 1;
BA_ "SignalType" SG_ 586 DgnInf "UNM";
BA_ "SignalLongName" SG_ 586 DgnInf "Diagnostic Information";
BA_ "VNSigAllNodes" SG_ 586 DgnInf 1;
BA_ "VNSigSLHSSharedDiagnostic" SG_ 1354 DgnInf_OBJ54A 1;
BA_ "SignalType" SG_ 1354 DgnInf_OBJ54A "UNM";
BA_ "SignalLongName" SG_ 1354 DgnInf_OBJ54A "Diagnostic Information OBJ54A";
BA_ "VNSigAllNodes" SG_ 1354 DgnInf_OBJ54A 1;
BA_ "VNSigSLHSSharedDiagnostic" SG_ 1610 DgnInf 1;
BA_ "SignalType" SG_ 1610 DgnInf "UNM";
BA_ "SignalLongName" SG_ 1610 DgnInf "Diagnostic Information";
BA_ "VNSigAllNodes" SG_ 1610 DgnInf 1;
BA_ "SignalType" SG_ 1033 CLL_Cnfdnc "ENM";
BA_ "PacketOrder" SG_ 1033 CLL_Cnfdnc 4;
BA_ "SignalLongName" SG_ 1033 CLL_Cnfdnc "Curvature Left Line : Confidence";
BA_ "VNSigAllNodes" SG_ 1033 CLL_Cnfdnc 1;
BA_ "SignalType" SG_ 1033 CLL_ViewRng "UNM";
BA_ "PacketOrder" SG_ 1033 CLL_ViewRng 3;
BA_ "SignalLongName" SG_ 1033 CLL_ViewRng "Curvature Left Line : View Range";
BA_ "VNSigAllNodes" SG_ 1033 CLL_ViewRng 1;
BA_ "SignalType" SG_ 1033 CLL_CoefdA "SNM";
BA_ "PacketOrder" SG_ 1033 CLL_CoefdA 2;
BA_ "SignalLongName" SG_ 1033 CLL_CoefdA "Curvature Left Line : Coefficient dA";
BA_ "VNSigAllNodes" SG_ 1033 CLL_CoefdA 1;
BA_ "SignalType" SG_ 1033 CLL_CoefA "SNM";
BA_ "PacketOrder" SG_ 1033 CLL_CoefA 1;
BA_ "SignalLongName" SG_ 1033 CLL_CoefA "Curvature Left Line : Coefficient A";
BA_ "VNSigAllNodes" SG_ 1033 CLL_CoefA 1;
BA_ "SignalType" SG_ 1034 CRL_Cnfdnc "ENM";
BA_ "PacketOrder" SG_ 1034 CRL_Cnfdnc 4;
BA_ "SignalLongName" SG_ 1034 CRL_Cnfdnc "Curvature Right Line : Confidence";
BA_ "VNSigAllNodes" SG_ 1034 CRL_Cnfdnc 1;
BA_ "SignalType" SG_ 1034 CRL_ViewRng "UNM";
BA_ "PacketOrder" SG_ 1034 CRL_ViewRng 3;
BA_ "SignalLongName" SG_ 1034 CRL_ViewRng "Curvature Right Line : View Range";
BA_ "VNSigAllNodes" SG_ 1034 CRL_ViewRng 1;
BA_ "SignalType" SG_ 1034 CRL_CoefdA "SNM";
BA_ "PacketOrder" SG_ 1034 CRL_CoefdA 2;
BA_ "SignalLongName" SG_ 1034 CRL_CoefdA "Curvature Right Line : Coefficient dA";
BA_ "VNSigAllNodes" SG_ 1034 CRL_CoefdA 1;
BA_ "SignalType" SG_ 1034 CRL_CoefA "SNM";
BA_ "PacketOrder" SG_ 1034 CRL_CoefA 1;
BA_ "SignalLongName" SG_ 1034 CRL_CoefA "Curvature Right Line : Coefficient A";
BA_ "VNSigAllNodes" SG_ 1034 CRL_CoefA 1;
BA_ "SignalType" SG_ 848 FwdVsnEnvIllum "ENM";
BA_ "SignalLongName" SG_ 848 FwdVsnEnvIllum "Forward Vision Environment Illumination";
BA_ "VNSigAllNodes" SG_ 848 FwdVsnEnvIllum 1;
BA_ "SignalType" SG_ 848 LaneSenseRollingCount "UNM";
BA_ "SignalLongName" SG_ 848 LaneSenseRollingCount "Lane Sense Rolling Count";
BA_ "VNSigAllNodes" SG_ 848 LaneSenseRollingCount 1;
BA_ "SignalType" SG_ 848 LaneSenseSystemOK "BLN";
BA_ "SignalLongName" SG_ 848 LaneSenseSystemOK "Lane Sense System OK";
BA_ "VNSigAllNodes" SG_ 848 LaneSenseSystemOK 1;
BA_ "SignalType" SG_ 848 LaneSenseSystemOKV "ENM";
BA_ "SignalLongName" SG_ 848 LaneSenseSystemOKV "Lane Sense System OK Validity";
BA_ "VNSigAllNodes" SG_ 848 LaneSenseSystemOKV 1;
BA_ "SignalType" SG_ 848 LaneSenseTimeStamp "UNM";
BA_ "SignalLongName" SG_ 848 LaneSenseTimeStamp "Lane Sense Data Time Stamp";
BA_ "VNSigAllNodes" SG_ 848 LaneSenseTimeStamp 1;
BA_ "SignalType" SG_ 848 LaneSenseTimeStampV "ENM";
BA_ "SignalLongName" SG_ 848 LaneSenseTimeStampV "Lane Sense Data Time Stamp Validity";
BA_ "VNSigAllNodes" SG_ 848 LaneSenseTimeStampV 1;
BA_ "SignalType" SG_ 848 LaneSnsLLnPosValid "ENM";
BA_ "SignalLongName" SG_ 848 LaneSnsLLnPosValid "Lane Sense Left Lane Position Valid";
BA_ "VNSigAllNodes" SG_ 848 LaneSnsLLnPosValid 1;
BA_ "SignalType" SG_ 848 LnSenseDistToLLnEdge "UNM";
BA_ "SignalLongName" SG_ 848 LnSenseDistToLLnEdge "Lane Sense Distance to Left Lane Edge";
BA_ "VNSigAllNodes" SG_ 848 LnSenseDistToLLnEdge 1;
BA_ "SignalType" SG_ 848 LnSnsBurstChecksum "UNM";
BA_ "SignalLongName" SG_ 848 LnSnsBurstChecksum "Lane Sense Burst Checksum";
BA_ "VNSigAllNodes" SG_ 848 LnSnsBurstChecksum 1;
BA_ "SignalType" SG_ 848 LnSnsDistToRLnEdge "UNM";
BA_ "SignalLongName" SG_ 848 LnSnsDistToRLnEdge "Lane Sense Distance to Right Lane Edge";
BA_ "VNSigAllNodes" SG_ 848 LnSnsDistToRLnEdge 1;
BA_ "SignalType" SG_ 848 LnSnsLnChngStatus "ENM";
BA_ "SignalLongName" SG_ 848 LnSnsLnChngStatus "Lane Sense Lane Change Status";
BA_ "VNSigAllNodes" SG_ 848 LnSnsLnChngStatus 1;
BA_ "SignalType" SG_ 848 LnSnsRLnPosValid "ENM";
BA_ "SignalLongName" SG_ 848 LnSnsRLnPosValid "Lane Sense Right Lane Position Valid";
BA_ "VNSigAllNodes" SG_ 848 LnSnsRLnPosValid 1;
BA_ "SignalType" SG_ 848 LnSnsTngtOfHdngLnRt "SNM";
BA_ "SignalLongName" SG_ 848 LnSnsTngtOfHdngLnRt "Lane Sense Tangent Of Heading In Lane Right";
BA_ "VNSigAllNodes" SG_ 848 LnSnsTngtOfHdngLnRt 1;
BA_ "SignalType" SG_ 848 LnSnsTngtOfHdngLnRtV "ENM";
BA_ "SignalLongName" SG_ 848 LnSnsTngtOfHdngLnRtV "Lane Sense Tangent Of Heading In Lane Right Validity";
BA_ "VNSigAllNodes" SG_ 848 LnSnsTngtOfHdngLnRtV 1;
BA_ "SignalType" SG_ 849 LnSnsBurstID "UNM";
BA_ "SignalLongName" SG_ 849 LnSnsBurstID "Lane Sense Burst ID";
BA_ "VNSigAllNodes" SG_ 849 LnSnsBurstID 1;
BA_ "SignalType" SG_ 849 LnSnsCrvtGrdntRt "SNM";
BA_ "SignalLongName" SG_ 849 LnSnsCrvtGrdntRt "Lane Sense Curvature Gradient Right";
BA_ "VNSigAllNodes" SG_ 849 LnSnsCrvtGrdntRt 1;
BA_ "SignalType" SG_ 849 LnSnsCrvtGrdntRtV "ENM";
BA_ "SignalLongName" SG_ 849 LnSnsCrvtGrdntRtV "Lane Sense Curvature Gradient Right Validity";
BA_ "VNSigAllNodes" SG_ 849 LnSnsCrvtGrdntRtV 1;
BA_ "SignalType" SG_ 849 LnSnsLatVRelToLftMrkg "SNM";
BA_ "SignalLongName" SG_ 849 LnSnsLatVRelToLftMrkg "Lane Sense Lateral Velocity Relative To Left Marking";
BA_ "VNSigAllNodes" SG_ 849 LnSnsLatVRelToLftMrkg 1;
BA_ "SignalType" SG_ 849 LnSnsLatVRelToRgtMrkg "SNM";
BA_ "SignalLongName" SG_ 849 LnSnsLatVRelToRgtMrkg "Lane Sense Lateral Velocity Relative To Right Marking";
BA_ "VNSigAllNodes" SG_ 849 LnSnsLatVRelToRgtMrkg 1;
BA_ "SignalType" SG_ 849 LnSnsLnCrvtrRght "SNM";
BA_ "SignalLongName" SG_ 849 LnSnsLnCrvtrRght "Lane Sense Lane Curvature Right";
BA_ "VNSigAllNodes" SG_ 849 LnSnsLnCrvtrRght 1;
BA_ "SignalType" SG_ 849 LnSnsLnCrvtrRghtV "ENM";
BA_ "SignalLongName" SG_ 849 LnSnsLnCrvtrRghtV "Lane Sense Lane Curvature Right Validity";
BA_ "VNSigAllNodes" SG_ 849 LnSnsLnCrvtrRghtV 1;
BA_ "SignalType" SG_ 849 LnSnsLnMrkgWdthRt "ENM";
BA_ "SignalLongName" SG_ 849 LnSnsLnMrkgWdthRt "Lane Sense Lane Marking Width Right";
BA_ "VNSigAllNodes" SG_ 849 LnSnsLnMrkgWdthRt 1;
BA_ "SignalType" SG_ 849 LnSnsLtAnchrLn "BLN";
BA_ "SignalLongName" SG_ 849 LnSnsLtAnchrLn "Lane Sense Left Anchor Lane";
BA_ "VNSigAllNodes" SG_ 849 LnSnsLtAnchrLn 1;
BA_ "SignalType" SG_ 849 LnSnsRtAnchrLn "BLN";
BA_ "SignalLongName" SG_ 849 LnSnsRtAnchrLn "Lane Sense Right Anchor Lane";
BA_ "VNSigAllNodes" SG_ 849 LnSnsRtAnchrLn 1;
BA_ "SignalType" SG_ 849 LnSnsRtLnMrkgTypChgDst "UNM";
BA_ "SignalLongName" SG_ 849 LnSnsRtLnMrkgTypChgDst "Lane Sense Right Lane Marking Type Change Distance";
BA_ "VNSigAllNodes" SG_ 849 LnSnsRtLnMrkgTypChgDst 1;
BA_ "SignalType" SG_ 850 LnMrkrElvtdLft "BLN";
BA_ "SignalLongName" SG_ 850 LnMrkrElvtdLft "Lane Marker Elevated Left";
BA_ "VNSigAllNodes" SG_ 850 LnMrkrElvtdLft 1;
BA_ "SignalType" SG_ 850 LnMrkrElvtdRght "BLN";
BA_ "SignalLongName" SG_ 850 LnMrkrElvtdRght "Lane Marker Elevated Right";
BA_ "VNSigAllNodes" SG_ 850 LnMrkrElvtdRght 1;
BA_ "SignalType" SG_ 850 LnMrkrTypLft "ENM";
BA_ "SignalLongName" SG_ 850 LnMrkrTypLft "Lane Marker Type Left";
BA_ "VNSigAllNodes" SG_ 850 LnMrkrTypLft 1;
BA_ "SignalType" SG_ 850 LnMrkrTypRght "ENM";
BA_ "SignalLongName" SG_ 850 LnMrkrTypRght "Lane Marker Type Right";
BA_ "VNSigAllNodes" SG_ 850 LnMrkrTypRght 1;
BA_ "SignalType" SG_ 850 LnPrvwDstncLft "UNM";
BA_ "SignalLongName" SG_ 850 LnPrvwDstncLft "Lane Preview Distance Left";
BA_ "VNSigAllNodes" SG_ 850 LnPrvwDstncLft 1;
BA_ "SignalType" SG_ 850 LnPrvwDstncRght "UNM";
BA_ "SignalLongName" SG_ 850 LnPrvwDstncRght "Lane Preview Distance Right";
BA_ "VNSigAllNodes" SG_ 850 LnPrvwDstncRght 1;
BA_ "SignalType" SG_ 850 LnQltyCnfdncLvlLft "UNM";
BA_ "SignalLongName" SG_ 850 LnQltyCnfdncLvlLft "Lane Quality Confidence Level Left";
BA_ "VNSigAllNodes" SG_ 850 LnQltyCnfdncLvlLft 1;
BA_ "SignalType" SG_ 850 LnQltyCnfdncLvlRght "UNM";
BA_ "SignalLongName" SG_ 850 LnQltyCnfdncLvlRght "Lane Quality Confidence Level Right";
BA_ "VNSigAllNodes" SG_ 850 LnQltyCnfdncLvlRght 1;
BA_ "SignalType" SG_ 850 LnSnsBurstID1 "UNM";
BA_ "SignalLongName" SG_ 850 LnSnsBurstID1 "Lane Sense Burst ID 1";
BA_ "VNSigAllNodes" SG_ 850 LnSnsBurstID1 1;
BA_ "SignalType" SG_ 850 LnSnsLnCrvtrLft "SNM";
BA_ "SignalLongName" SG_ 850 LnSnsLnCrvtrLft "Lane Sense Lane Curvature Left";
BA_ "VNSigAllNodes" SG_ 850 LnSnsLnCrvtrLft 1;
BA_ "SignalType" SG_ 850 LnSnsLnCrvtrLftV "ENM";
BA_ "SignalLongName" SG_ 850 LnSnsLnCrvtrLftV "Lane Sense Lane Curvature Left Validity";
BA_ "VNSigAllNodes" SG_ 850 LnSnsLnCrvtrLftV 1;
BA_ "SignalType" SG_ 850 LnSnsLtLnMrkgTypChgDst "UNM";
BA_ "SignalLongName" SG_ 850 LnSnsLtLnMrkgTypChgDst "Lane Sense Left Lane Marking Type Change Distance";
BA_ "VNSigAllNodes" SG_ 850 LnSnsLtLnMrkgTypChgDst 1;
BA_ "SignalType" SG_ 850 LnSnsLtLnMrkgWdth "ENM";
BA_ "SignalLongName" SG_ 850 LnSnsLtLnMrkgWdth "Lane Sense Left Lane Marking Width";
BA_ "VNSigAllNodes" SG_ 850 LnSnsLtLnMrkgWdth 1;
BA_ "SignalType" SG_ 850 LnSnsTngtOfHdngLnLft "SNM";
BA_ "SignalLongName" SG_ 850 LnSnsTngtOfHdngLnLft "Lane Sense Tangent Of Heading In Lane Left";
BA_ "VNSigAllNodes" SG_ 850 LnSnsTngtOfHdngLnLft 1;
BA_ "SignalType" SG_ 850 LnSnsTngtOfHdngLnLftV "ENM";
BA_ "SignalLongName" SG_ 850 LnSnsTngtOfHdngLnLftV "Lane Sense Tangent Of Heading In Lane Left Validity";
BA_ "VNSigAllNodes" SG_ 850 LnSnsTngtOfHdngLnLftV 1;
BA_ "SignalType" SG_ 850 LnSnsTtlNmLnMrkgDetLt "UNM";
BA_ "SignalLongName" SG_ 850 LnSnsTtlNmLnMrkgDetLt "Lane Sense Total Number Lane Markings Detected Left";
BA_ "VNSigAllNodes" SG_ 850 LnSnsTtlNmLnMrkgDetLt 1;
BA_ "SignalType" SG_ 851 LnMrkg3AnchrLnLin "BLN";
BA_ "SignalLongName" SG_ 851 LnMrkg3AnchrLnLin "Lane Marking 3 Anchor Lane Line";
BA_ "VNSigAllNodes" SG_ 851 LnMrkg3AnchrLnLin 1;
BA_ "SignalType" SG_ 851 LnMrkg3LnMarkrElvtd "BLN";
BA_ "SignalLongName" SG_ 851 LnMrkg3LnMarkrElvtd "Lane Marking 3 Lane Marker Elevated";
BA_ "VNSigAllNodes" SG_ 851 LnMrkg3LnMarkrElvtd 1;
BA_ "SignalType" SG_ 851 LnMrkg3LnMrkgTypChgDst "UNM";
BA_ "SignalLongName" SG_ 851 LnMrkg3LnMrkgTypChgDst "Lane Marking 3 Lane Marking Type Change Distance";
BA_ "VNSigAllNodes" SG_ 851 LnMrkg3LnMrkgTypChgDst 1;
BA_ "SignalType" SG_ 851 LnMrkg3LnMrkgWdth "ENM";
BA_ "SignalLongName" SG_ 851 LnMrkg3LnMrkgWdth "Lane Marking 3 Lane Marking Width";
BA_ "VNSigAllNodes" SG_ 851 LnMrkg3LnMrkgWdth 1;
BA_ "SignalType" SG_ 851 LnMrkg3LnPrvwDst "UNM";
BA_ "SignalLongName" SG_ 851 LnMrkg3LnPrvwDst "Lane Marking 3 Lane Preview Distance";
BA_ "VNSigAllNodes" SG_ 851 LnMrkg3LnPrvwDst 1;
BA_ "SignalType" SG_ 851 LnMrkg4AnchrLnLin "BLN";
BA_ "SignalLongName" SG_ 851 LnMrkg4AnchrLnLin "Lane Marking 4 Anchor Lane Line";
BA_ "VNSigAllNodes" SG_ 851 LnMrkg4AnchrLnLin 1;
BA_ "SignalType" SG_ 851 LnMrkg4LnMarkrElvtd "BLN";
BA_ "SignalLongName" SG_ 851 LnMrkg4LnMarkrElvtd "Lane Marking 4 Lane Marker Elevated";
BA_ "VNSigAllNodes" SG_ 851 LnMrkg4LnMarkrElvtd 1;
BA_ "SignalType" SG_ 851 LnMrkg4LnMrkgTypChgDst "UNM";
BA_ "SignalLongName" SG_ 851 LnMrkg4LnMrkgTypChgDst "Lane Marking 4 Lane Marking Type Change Distance";
BA_ "VNSigAllNodes" SG_ 851 LnMrkg4LnMrkgTypChgDst 1;
BA_ "SignalType" SG_ 851 LnMrkg4LnMrkgWdth "ENM";
BA_ "SignalLongName" SG_ 851 LnMrkg4LnMrkgWdth "Lane Marking 4 Lane Marking Width";
BA_ "VNSigAllNodes" SG_ 851 LnMrkg4LnMrkgWdth 1;
BA_ "SignalType" SG_ 851 LnMrkg4LnPrvwDst "UNM";
BA_ "SignalLongName" SG_ 851 LnMrkg4LnPrvwDst "Lane Marking 4 Lane Preview Distance";
BA_ "VNSigAllNodes" SG_ 851 LnMrkg4LnPrvwDst 1;
BA_ "SignalType" SG_ 851 LnSnsBurstID2 "UNM";
BA_ "SignalLongName" SG_ 851 LnSnsBurstID2 "Lane Sense Burst ID 2";
BA_ "VNSigAllNodes" SG_ 851 LnSnsBurstID2 1;
BA_ "SignalType" SG_ 851 LnSnsCrvtGrdntLft "SNM";
BA_ "SignalLongName" SG_ 851 LnSnsCrvtGrdntLft "Lane Sense Curvature Gradient Left";
BA_ "VNSigAllNodes" SG_ 851 LnSnsCrvtGrdntLft 1;
BA_ "SignalType" SG_ 851 LnSnsCrvtGrdntLftV "ENM";
BA_ "SignalLongName" SG_ 851 LnSnsCrvtGrdntLftV "Lane Sense Curvature Gradient Left Validity";
BA_ "VNSigAllNodes" SG_ 851 LnSnsCrvtGrdntLftV 1;
BA_ "SignalType" SG_ 851 LnSnsLtLinCrsTm "UNM";
BA_ "SignalLongName" SG_ 851 LnSnsLtLinCrsTm "Lane Sense Left Line-Cross Time";
BA_ "VNSigAllNodes" SG_ 851 LnSnsLtLinCrsTm 1;
BA_ "SignalType" SG_ 851 LnSnsNumPrlLnsDetLt "UNM";
BA_ "SignalLongName" SG_ 851 LnSnsNumPrlLnsDetLt "Lane Sense Number of Parallel Lanes Detected Left";
BA_ "VNSigAllNodes" SG_ 851 LnSnsNumPrlLnsDetLt 1;
BA_ "SignalType" SG_ 851 LnSnsNumPrlLnsDetRt "UNM";
BA_ "SignalLongName" SG_ 851 LnSnsNumPrlLnsDetRt "Lane Sense Number of Parallel Lanes Detected Right";
BA_ "VNSigAllNodes" SG_ 851 LnSnsNumPrlLnsDetRt 1;
BA_ "SignalType" SG_ 851 LnSnsRtLinCrsTm "UNM";
BA_ "SignalLongName" SG_ 851 LnSnsRtLinCrsTm "Lane Sense Right Line-Cross Time";
BA_ "VNSigAllNodes" SG_ 851 LnSnsRtLinCrsTm 1;
BA_ "SignalType" SG_ 851 LnSnsTtlNmLnMrkgDetRt "UNM";
BA_ "SignalLongName" SG_ 851 LnSnsTtlNmLnMrkgDetRt "Lane Sense Total Number Lane Markings Detected Right";
BA_ "VNSigAllNodes" SG_ 851 LnSnsTtlNmLnMrkgDetRt 1;
BA_ "SignalType" SG_ 852 LnMrkg3LnMrkrTyp "ENM";
BA_ "SignalLongName" SG_ 852 LnMrkg3LnMrkrTyp "Lane Marking 3 Lane Marker Type";
BA_ "VNSigAllNodes" SG_ 852 LnMrkg3LnMrkrTyp 1;
BA_ "SignalType" SG_ 852 LnMrkg3LnQltyConfLvl "UNM";
BA_ "SignalLongName" SG_ 852 LnMrkg3LnQltyConfLvl "Lane Marking 3 Lane Quality Confidence Level";
BA_ "VNSigAllNodes" SG_ 852 LnMrkg3LnQltyConfLvl 1;
BA_ "SignalType" SG_ 852 LnMrkg3LnSnsLnCrvt "SNM";
BA_ "SignalLongName" SG_ 852 LnMrkg3LnSnsLnCrvt "Lane Marking 3 Lane Sense Lane Curvature";
BA_ "VNSigAllNodes" SG_ 852 LnMrkg3LnSnsLnCrvt 1;
BA_ "SignalType" SG_ 852 LnMrkg3LnSnsLnCrvtGrad "SNM";
BA_ "SignalLongName" SG_ 852 LnMrkg3LnSnsLnCrvtGrad "Lane Marking 3 Lane Sense Lane Curvature Gradient";
BA_ "VNSigAllNodes" SG_ 852 LnMrkg3LnSnsLnCrvtGrad 1;
BA_ "SignalType" SG_ 852 LnMrkg3LnSnsLnCrvtGradV "ENM";
BA_ "SignalLongName" SG_ 852 LnMrkg3LnSnsLnCrvtGradV "Lane Marking 3 Lane Sense Lane Curvature Gradient Validity";
BA_ "VNSigAllNodes" SG_ 852 LnMrkg3LnSnsLnCrvtGradV 1;
BA_ "SignalType" SG_ 852 LnMrkg3LnSnsLnCrvtV "ENM";
BA_ "SignalLongName" SG_ 852 LnMrkg3LnSnsLnCrvtV "Lane Marking 3 Lane Sense Lane Curvature Validity";
BA_ "VNSigAllNodes" SG_ 852 LnMrkg3LnSnsLnCrvtV 1;
BA_ "SignalType" SG_ 852 LnMrkg3LnSnsLnDst "SNM";
BA_ "SignalLongName" SG_ 852 LnMrkg3LnSnsLnDst "Lane Marking 3 Lane Sense Lane Distance";
BA_ "VNSigAllNodes" SG_ 852 LnMrkg3LnSnsLnDst 1;
BA_ "SignalType" SG_ 852 LnMrkg3LnSnsLnDstV "ENM";
BA_ "SignalLongName" SG_ 852 LnMrkg3LnSnsLnDstV "Lane Marking 3 Lane Sense Lane Distance Validity";
BA_ "VNSigAllNodes" SG_ 852 LnMrkg3LnSnsLnDstV 1;
BA_ "SignalType" SG_ 852 LnMrkg3LnSnsLnHdngTngt "SNM";
BA_ "SignalLongName" SG_ 852 LnMrkg3LnSnsLnHdngTngt "Lane Marking 3 Lane Sense Lane Heading Tangent";
BA_ "VNSigAllNodes" SG_ 852 LnMrkg3LnSnsLnHdngTngt 1;
BA_ "SignalType" SG_ 852 LnMrkg3LnSnsLnHdngTngtV "ENM";
BA_ "SignalLongName" SG_ 852 LnMrkg3LnSnsLnHdngTngtV "Lane Marking 3 Lane Sense Lane Heading Tangent Validity";
BA_ "VNSigAllNodes" SG_ 852 LnMrkg3LnSnsLnHdngTngtV 1;
BA_ "SignalType" SG_ 852 LnSnsBrstID3 "UNM";
BA_ "SignalLongName" SG_ 852 LnSnsBrstID3 "Lane Sense Burst ID 3";
BA_ "VNSigAllNodes" SG_ 852 LnSnsBrstID3 1;
BA_ "SignalType" SG_ 853 LnMrkg4LnMrkrTyp "ENM";
BA_ "SignalLongName" SG_ 853 LnMrkg4LnMrkrTyp "Lane Marking 4 Lane Marker Type";
BA_ "VNSigAllNodes" SG_ 853 LnMrkg4LnMrkrTyp 1;
BA_ "SignalType" SG_ 853 LnMrkg4LnQltyConfLvl "UNM";
BA_ "SignalLongName" SG_ 853 LnMrkg4LnQltyConfLvl "Lane Marking 4 Lane Quality Confidence Level";
BA_ "VNSigAllNodes" SG_ 853 LnMrkg4LnQltyConfLvl 1;
BA_ "SignalType" SG_ 853 LnMrkg4LnSnsLnCrvt "SNM";
BA_ "SignalLongName" SG_ 853 LnMrkg4LnSnsLnCrvt "Lane Marking 4 Lane Sense Lane Curvature";
BA_ "VNSigAllNodes" SG_ 853 LnMrkg4LnSnsLnCrvt 1;
BA_ "SignalType" SG_ 853 LnMrkg4LnSnsLnCrvtGrad "SNM";
BA_ "SignalLongName" SG_ 853 LnMrkg4LnSnsLnCrvtGrad "Lane Marking 4 Lane Sense Lane Curvature Gradient";
BA_ "VNSigAllNodes" SG_ 853 LnMrkg4LnSnsLnCrvtGrad 1;
BA_ "SignalType" SG_ 853 LnMrkg4LnSnsLnCrvtGradV "ENM";
BA_ "SignalLongName" SG_ 853 LnMrkg4LnSnsLnCrvtGradV "Lane Marking 4 Lane Sense Lane Curvature Gradient Validity";
BA_ "VNSigAllNodes" SG_ 853 LnMrkg4LnSnsLnCrvtGradV 1;
BA_ "SignalType" SG_ 853 LnMrkg4LnSnsLnCrvtV "ENM";
BA_ "SignalLongName" SG_ 853 LnMrkg4LnSnsLnCrvtV "Lane Marking 4 Lane Sense Lane Curvature Validity";
BA_ "VNSigAllNodes" SG_ 853 LnMrkg4LnSnsLnCrvtV 1;
BA_ "SignalType" SG_ 853 LnMrkg4LnSnsLnDst "SNM";
BA_ "SignalLongName" SG_ 853 LnMrkg4LnSnsLnDst "Lane Marking 4 Lane Sense Lane Distance";
BA_ "VNSigAllNodes" SG_ 853 LnMrkg4LnSnsLnDst 1;
BA_ "SignalType" SG_ 853 LnMrkg4LnSnsLnDstV "ENM";
BA_ "SignalLongName" SG_ 853 LnMrkg4LnSnsLnDstV "Lane Marking 4 Lane Sense Lane Distance Validity";
BA_ "VNSigAllNodes" SG_ 853 LnMrkg4LnSnsLnDstV 1;
BA_ "SignalType" SG_ 853 LnMrkg4LnSnsLnHdngTngt "SNM";
BA_ "SignalLongName" SG_ 853 LnMrkg4LnSnsLnHdngTngt "Lane Marking 4 Lane Sense Lane Heading Tangent";
BA_ "VNSigAllNodes" SG_ 853 LnMrkg4LnSnsLnHdngTngt 1;
BA_ "SignalType" SG_ 853 LnMrkg4LnSnsLnHdngTngtV "ENM";
BA_ "SignalLongName" SG_ 853 LnMrkg4LnSnsLnHdngTngtV "Lane Marking 4 Lane Sense Lane Heading Tangent Validity";
BA_ "VNSigAllNodes" SG_ 853 LnMrkg4LnSnsLnHdngTngtV 1;
BA_ "SignalType" SG_ 853 LnSnsBrstID4 "UNM";
BA_ "SignalLongName" SG_ 853 LnSnsBrstID4 "Lane Sense Burst ID 4";
BA_ "VNSigAllNodes" SG_ 853 LnSnsBrstID4 1;
BA_ "SignalType" SG_ 854 FwdVsnCnstrctAreaDst "UNM";
BA_ "SignalLongName" SG_ 854 FwdVsnCnstrctAreaDst "Forward Vision Construction Area Distance";
BA_ "VNSigAllNodes" SG_ 854 FwdVsnCnstrctAreaDst 1;
BA_ "SignalType" SG_ 854 FwdVsnCnstrctZnDet "ENM";
BA_ "SignalLongName" SG_ 854 FwdVsnCnstrctZnDet "Forward Vision Construction Zone Detected";
BA_ "VNSigAllNodes" SG_ 854 FwdVsnCnstrctZnDet 1;
BA_ "SignalType" SG_ 854 FwdVsnEgoVehLnPos "ENM";
BA_ "SignalLongName" SG_ 854 FwdVsnEgoVehLnPos "Forward Vision Ego Vehicle Lane Position";
BA_ "VNSigAllNodes" SG_ 854 FwdVsnEgoVehLnPos 1;
BA_ "SignalType" SG_ 854 FwdVsnRdTypDet "ENM";
BA_ "SignalLongName" SG_ 854 FwdVsnRdTypDet "Forward Vision Road Type Detected";
BA_ "VNSigAllNodes" SG_ 854 FwdVsnRdTypDet 1;
BA_ "SignalType" SG_ 854 FwdVsnTunnlDetd "ENM";
BA_ "SignalLongName" SG_ 854 FwdVsnTunnlDetd "Forward Vision Tunnel Detected";
BA_ "VNSigAllNodes" SG_ 854 FwdVsnTunnlDetd 1;
BA_ "SignalType" SG_ 854 FwdVsnTunnlDst "UNM";
BA_ "SignalLongName" SG_ 854 FwdVsnTunnlDst "Forward Vision Tunnel Distance";
BA_ "VNSigAllNodes" SG_ 854 FwdVsnTunnlDst 1;
BA_ "SignalType" SG_ 854 LnSnsBrstID5 "UNM";
BA_ "SignalLongName" SG_ 854 LnSnsBrstID5 "Lane Sense Burst ID 5";
BA_ "VNSigAllNodes" SG_ 854 LnSnsBrstID5 1;
BA_ "SignalType" SG_ 304 MstrTrigSyncInrtl11 "UNM";
BA_ "SignalLongName" SG_ 304 MstrTrigSyncInrtl11 "Master Trigger Sync Inertial 11";
BA_ "VNSigAllNodes" SG_ 304 MstrTrigSyncInrtl11 1;
BA_ "SignalType" SG_ 304 InrtlSnsr1LatAcc "SNM";
BA_ "SignalLongName" SG_ 304 InrtlSnsr1LatAcc "Inertial Sensor 1 Lateral Acceleration";
BA_ "VNSigAllNodes" SG_ 304 InrtlSnsr1LatAcc 1;
BA_ "SignalType" SG_ 304 InrtlSnsr1LatAccV "ENM";
BA_ "SignalLongName" SG_ 304 InrtlSnsr1LatAccV "Inertial Sensor 1 Lateral Acceleration Validity";
BA_ "VNSigAllNodes" SG_ 304 InrtlSnsr1LatAccV 1;
BA_ "SignalType" SG_ 304 InrtlSnsr1LonAcc "SNM";
BA_ "SignalLongName" SG_ 304 InrtlSnsr1LonAcc "Inertial Sensor 1 Longitudinal Acceleration";
BA_ "VNSigAllNodes" SG_ 304 InrtlSnsr1LonAcc 1;
BA_ "SignalType" SG_ 304 InrtlSnsr1LonAccV "ENM";
BA_ "SignalLongName" SG_ 304 InrtlSnsr1LonAccV "Inertial Sensor 1 Longitudinal Acceleration Validity";
BA_ "VNSigAllNodes" SG_ 304 InrtlSnsr1LonAccV 1;
BA_ "SignalType" SG_ 304 InrtlSnsr1VertAcc "SNM";
BA_ "SignalLongName" SG_ 304 InrtlSnsr1VertAcc "Inertial Sensor 1 Vertical Acceleration";
BA_ "VNSigAllNodes" SG_ 304 InrtlSnsr1VertAcc 1;
BA_ "SignalType" SG_ 304 InrtlSnsr1VertAccV "ENM";
BA_ "SignalLongName" SG_ 304 InrtlSnsr1VertAccV "Inertial Sensor 1 Vertical Acceleration Validity";
BA_ "VNSigAllNodes" SG_ 304 InrtlSnsr1VertAccV 1;
BA_ "SignalType" SG_ 304 IntlSnsr1AcelFm1Chksm "UNM";
BA_ "SignalLongName" SG_ 304 IntlSnsr1AcelFm1Chksm "Inertial Sensor 1 Accel Frame 1 Checksum";
BA_ "VNSigAllNodes" SG_ 304 IntlSnsr1AcelFm1Chksm 1;
BA_ "SignalType" SG_ 306 MstrTrigSyncInrtl12 "UNM";
BA_ "SignalLongName" SG_ 306 MstrTrigSyncInrtl12 "Master Trigger Sync Inertial 12";
BA_ "VNSigAllNodes" SG_ 306 MstrTrigSyncInrtl12 1;
BA_ "SignalType" SG_ 306 InrtlSnsr1AccelFrm2Chksm "UNM";
BA_ "SignalLongName" SG_ 306 InrtlSnsr1AccelFrm2Chksm "Inertial Sensor 1 Accel Frame 2 Checksum";
BA_ "VNSigAllNodes" SG_ 306 InrtlSnsr1AccelFrm2Chksm 1;
BA_ "SignalType" SG_ 306 InrtlSnsr1PtchAcc "SNM";
BA_ "SignalLongName" SG_ 306 InrtlSnsr1PtchAcc "Inertial Sensor 1 Pitch Acceleration";
BA_ "VNSigAllNodes" SG_ 306 InrtlSnsr1PtchAcc 1;
BA_ "SignalType" SG_ 306 InrtlSnsr1PtchAccV "ENM";
BA_ "SignalLongName" SG_ 306 InrtlSnsr1PtchAccV "Inertial Sensor 1 Pitch Acceleration Validity";
BA_ "VNSigAllNodes" SG_ 306 InrtlSnsr1PtchAccV 1;
BA_ "SignalType" SG_ 306 InrtlSnsr1RollAcc "SNM";
BA_ "SignalLongName" SG_ 306 InrtlSnsr1RollAcc "Inertial Sensor 1 Roll Acceleration";
BA_ "VNSigAllNodes" SG_ 306 InrtlSnsr1RollAcc 1;
BA_ "SignalType" SG_ 306 InrtlSnsr1RollAccV "ENM";
BA_ "SignalLongName" SG_ 306 InrtlSnsr1RollAccV "Inertial Sensor 1 Roll Acceleration Validity";
BA_ "VNSigAllNodes" SG_ 306 InrtlSnsr1RollAccV 1;
BA_ "SignalType" SG_ 306 InrtlSnsr1YawAcc "SNM";
BA_ "SignalLongName" SG_ 306 InrtlSnsr1YawAcc "Inertial Sensor 1 Yaw Acceleration";
BA_ "VNSigAllNodes" SG_ 306 InrtlSnsr1YawAcc 1;
BA_ "SignalType" SG_ 306 InrtlSnsr1YawAccV "ENM";
BA_ "SignalLongName" SG_ 306 InrtlSnsr1YawAccV "Inertial Sensor 1 Yaw Acceleration Validity";
BA_ "VNSigAllNodes" SG_ 306 InrtlSnsr1YawAccV 1;
BA_ "SignalType" SG_ 308 MstrTrgrSyncInrtl1Rte "UNM";
BA_ "SignalLongName" SG_ 308 MstrTrgrSyncInrtl1Rte "Master Trigger Sync Inertial 1 Rate";
BA_ "VNSigAllNodes" SG_ 308 MstrTrgrSyncInrtl1Rte 1;
BA_ "SignalType" SG_ 308 Inertial1PitchRte "SNM";
BA_ "SignalLongName" SG_ 308 Inertial1PitchRte "Inertial Sensor 1 Pitch Rate";
BA_ "VNSigAllNodes" SG_ 308 Inertial1PitchRte 1;
BA_ "SignalType" SG_ 308 Inertial1PitchRteV "ENM";
BA_ "SignalLongName" SG_ 308 Inertial1PitchRteV "Inertial Sensor 1 Pitch Rate Validity";
BA_ "VNSigAllNodes" SG_ 308 Inertial1PitchRteV 1;
BA_ "SignalType" SG_ 308 Inertial1RollRte "SNM";
BA_ "SignalLongName" SG_ 308 Inertial1RollRte "Inertial Sensor 1 Roll Rate";
BA_ "VNSigAllNodes" SG_ 308 Inertial1RollRte 1;
BA_ "SignalType" SG_ 308 Inertial1RollRteV "ENM";
BA_ "SignalLongName" SG_ 308 Inertial1RollRteV "Inertial Sensor 1 Roll Rate Validity";
BA_ "VNSigAllNodes" SG_ 308 Inertial1RollRteV 1;
BA_ "SignalType" SG_ 308 Inertial1RteChksum "UNM";
BA_ "SignalLongName" SG_ 308 Inertial1RteChksum "Inertial Sensor 1 Rate Checksum";
BA_ "VNSigAllNodes" SG_ 308 Inertial1RteChksum 1;
BA_ "SignalType" SG_ 308 Inertial1YawRte "SNM";
BA_ "SignalLongName" SG_ 308 Inertial1YawRte "Inertial Sensor 1 Yaw Rate";
BA_ "VNSigAllNodes" SG_ 308 Inertial1YawRte 1;
BA_ "SignalType" SG_ 308 Inertial1YawRteV "ENM";
BA_ "SignalLongName" SG_ 308 Inertial1YawRteV "Inertial Sensor 1 Yaw Rate Validity";
BA_ "VNSigAllNodes" SG_ 308 Inertial1YawRteV 1;
BA_ "SignalType" SG_ 310 MstrTrigSyncInrtl21 "UNM";
BA_ "SignalLongName" SG_ 310 MstrTrigSyncInrtl21 "Master Trigger Sync Inertial 21";
BA_ "VNSigAllNodes" SG_ 310 MstrTrigSyncInrtl21 1;
BA_ "SignalType" SG_ 310 Inertial2LatAcc "SNM";
BA_ "SignalLongName" SG_ 310 Inertial2LatAcc "Inertial Sensor 2 Lateral Acceleration";
BA_ "VNSigAllNodes" SG_ 310 Inertial2LatAcc 1;
BA_ "SignalType" SG_ 310 Inertial2LatAccV "ENM";
BA_ "SignalLongName" SG_ 310 Inertial2LatAccV "Inertial Sensor 2 Lateral Acceleration Validity";
BA_ "VNSigAllNodes" SG_ 310 Inertial2LatAccV 1;
BA_ "SignalType" SG_ 310 Inertial2LonAcc "SNM";
BA_ "SignalLongName" SG_ 310 Inertial2LonAcc "Inertial Sensor 2 Longitudinal Acceleration";
BA_ "VNSigAllNodes" SG_ 310 Inertial2LonAcc 1;
BA_ "SignalType" SG_ 310 Inertial2LonAccV "ENM";
BA_ "SignalLongName" SG_ 310 Inertial2LonAccV "Inertial Sensor 2 Longitudinal Acceleration Validity";
BA_ "VNSigAllNodes" SG_ 310 Inertial2LonAccV 1;
BA_ "SignalType" SG_ 310 Inertial2VertAcc "SNM";
BA_ "SignalLongName" SG_ 310 Inertial2VertAcc "Inertial Sensor 2 Vertical Acceleration";
BA_ "VNSigAllNodes" SG_ 310 Inertial2VertAcc 1;
BA_ "SignalType" SG_ 310 Inertial2VertAccV "ENM";
BA_ "SignalLongName" SG_ 310 Inertial2VertAccV "Inertial Sensor 2 Vertical Acceleration Validity";
BA_ "VNSigAllNodes" SG_ 310 Inertial2VertAccV 1;
BA_ "SignalType" SG_ 310 IntlSnsr2AcelFm1Chksm "UNM";
BA_ "SignalLongName" SG_ 310 IntlSnsr2AcelFm1Chksm "Inertial Sensor 2 Accel Frame 1 Checksum";
BA_ "VNSigAllNodes" SG_ 310 IntlSnsr2AcelFm1Chksm 1;
BA_ "SignalType" SG_ 312 MstrTrigSyncInrtl22 "UNM";
BA_ "SignalLongName" SG_ 312 MstrTrigSyncInrtl22 "Master Trigger Sync Inertial 22";
BA_ "VNSigAllNodes" SG_ 312 MstrTrigSyncInrtl22 1;
BA_ "SignalType" SG_ 312 InrtlSns2AccFrm2Chksm "UNM";
BA_ "SignalLongName" SG_ 312 InrtlSns2AccFrm2Chksm "Inertial Sensor 2 Accel Frame 2 Checksum";
BA_ "VNSigAllNodes" SG_ 312 InrtlSns2AccFrm2Chksm 1;
BA_ "SignalType" SG_ 312 InrtlSnsr2PtchAcc "SNM";
BA_ "SignalLongName" SG_ 312 InrtlSnsr2PtchAcc "Inertial Sensor 2 Pitch Acceleration";
BA_ "VNSigAllNodes" SG_ 312 InrtlSnsr2PtchAcc 1;
BA_ "SignalType" SG_ 312 InrtlSnsr2PtchAccV "ENM";
BA_ "SignalLongName" SG_ 312 InrtlSnsr2PtchAccV "Inertial Sensor 2 Pitch Acceleration Validity";
BA_ "VNSigAllNodes" SG_ 312 InrtlSnsr2PtchAccV 1;
BA_ "SignalType" SG_ 312 InrtlSnsr2RollAcc "SNM";
BA_ "SignalLongName" SG_ 312 InrtlSnsr2RollAcc "Inertial Sensor 2 Roll Acceleration";
BA_ "VNSigAllNodes" SG_ 312 InrtlSnsr2RollAcc 1;
BA_ "SignalType" SG_ 312 InrtlSnsr2RollAccV "ENM";
BA_ "SignalLongName" SG_ 312 InrtlSnsr2RollAccV "Inertial Sensor 2 Roll Acceleration Validity";
BA_ "VNSigAllNodes" SG_ 312 InrtlSnsr2RollAccV 1;
BA_ "SignalType" SG_ 312 InrtlSnsr2YawAcc "SNM";
BA_ "SignalLongName" SG_ 312 InrtlSnsr2YawAcc "Inertial Sensor 2 Yaw Acceleration";
BA_ "VNSigAllNodes" SG_ 312 InrtlSnsr2YawAcc 1;
BA_ "SignalType" SG_ 312 InrtlSnsr2YawAccV "ENM";
BA_ "SignalLongName" SG_ 312 InrtlSnsr2YawAccV "Inertial Sensor 2 Yaw Acceleration Validity";
BA_ "VNSigAllNodes" SG_ 312 InrtlSnsr2YawAccV 1;
BA_ "SignalType" SG_ 320 MstrTgrSyncInrtl2Rte "UNM";
BA_ "SignalLongName" SG_ 320 MstrTgrSyncInrtl2Rte "Master Trigger Sync Inertial 2 Rate";
BA_ "VNSigAllNodes" SG_ 320 MstrTgrSyncInrtl2Rte 1;
BA_ "SignalType" SG_ 320 Inertial2PitchRte "SNM";
BA_ "SignalLongName" SG_ 320 Inertial2PitchRte "Inertial Sensor 2 Pitch Rate";
BA_ "VNSigAllNodes" SG_ 320 Inertial2PitchRte 1;
BA_ "SignalType" SG_ 320 Inertial2PitchRteV "ENM";
BA_ "SignalLongName" SG_ 320 Inertial2PitchRteV "Inertial Sensor 2 Pitch Rate Validity";
BA_ "VNSigAllNodes" SG_ 320 Inertial2PitchRteV 1;
BA_ "SignalType" SG_ 320 Inertial2RollRte "SNM";
BA_ "SignalLongName" SG_ 320 Inertial2RollRte "Inertial Sensor 2 Roll Rate";
BA_ "VNSigAllNodes" SG_ 320 Inertial2RollRte 1;
BA_ "SignalType" SG_ 320 Inertial2RollRteV "ENM";
BA_ "SignalLongName" SG_ 320 Inertial2RollRteV "Inertial Sensor 2 Roll Rate Validity";
BA_ "VNSigAllNodes" SG_ 320 Inertial2RollRteV 1;
BA_ "SignalType" SG_ 320 Inertial2RteChksum "UNM";
BA_ "SignalLongName" SG_ 320 Inertial2RteChksum "Inertial Sensor 2 Rate Checksum";
BA_ "VNSigAllNodes" SG_ 320 Inertial2RteChksum 1;
BA_ "SignalType" SG_ 320 Inertial2YawRte "SNM";
BA_ "SignalLongName" SG_ 320 Inertial2YawRte "Inertial Sensor 2 Yaw Rate";
BA_ "VNSigAllNodes" SG_ 320 Inertial2YawRte 1;
BA_ "SignalType" SG_ 320 Inertial2YawRteV "ENM";
BA_ "SignalLongName" SG_ 320 Inertial2YawRteV "Inertial Sensor 2 Yaw Rate Validity";
BA_ "VNSigAllNodes" SG_ 320 Inertial2YawRteV 1;
BA_ "SignalType" SG_ 784 EngRunAtv "BLN";
BA_ "SignalLongName" SG_ 784 EngRunAtv "Engine Run Active";
BA_ "VNSigAllNodes" SG_ 784 EngRunAtv 1;
BA_ "GenSigDeltaValue" SG_ 784 StrgColUpDwnPos 1;
BA_ "GenSigSendType" SG_ 784 StrgColUpDwnPos 12;
BA_ "SignalType" SG_ 784 StrgColUpDwnPos "UNM";
BA_ "SignalLongName" SG_ 784 StrgColUpDwnPos "Steering Column Up Down Position";
BA_ "VNSigAllNodes" SG_ 784 StrgColUpDwnPos 1;
BA_ "GenSigSendType" SG_ 784 CPMAPINFO4 10;
BA_ "SignalType" SG_ 784 CPMAPINFO4 "ENM";
BA_ "SignalLongName" SG_ 784 CPMAPINFO4 "Steering Column Internal Fault";
BA_ "VNSigAllNodes" SG_ 784 CPMAPINFO4 1;
BA_ "GenSigDeltaValue" SG_ 784 StrgColInOutPos 1;
BA_ "GenSigSendType" SG_ 784 StrgColInOutPos 12;
BA_ "SignalType" SG_ 784 StrgColInOutPos "UNM";
BA_ "SignalLongName" SG_ 784 StrgColInOutPos "Steering Column In Out Position";
BA_ "VNSigAllNodes" SG_ 784 StrgColInOutPos 1;
BA_ "GenSigSendType" SG_ 784 StrgColCommsFlt 10;
BA_ "SignalType" SG_ 784 StrgColCommsFlt "ENM";
BA_ "SignalLongName" SG_ 784 StrgColCommsFlt "Steering Column Communications Fault";
BA_ "VNSigAllNodes" SG_ 784 StrgColCommsFlt 1;
BA_ "GenSigSendType" SG_ 784 DrDoorOpenSwActV 10;
BA_ "SignalType" SG_ 784 DrDoorOpenSwActV "ENM";
BA_ "SignalLongName" SG_ 784 DrDoorOpenSwActV "Driver Door Open Switch Active Validity";
BA_ "VNSigAllNodes" SG_ 784 DrDoorOpenSwActV 1;
BA_ "GenSigSendType" SG_ 784 DrDoorOpenSwAct 10;
BA_ "SignalType" SG_ 784 DrDoorOpenSwAct "BLN";
BA_ "SignalLongName" SG_ 784 DrDoorOpenSwAct "Driver Door Open Switch Active";
BA_ "VNSigAllNodes" SG_ 784 DrDoorOpenSwAct 1;
BA_ "GenSigSendType" SG_ 784 DrvWndPosStat 10;
BA_ "SignalType" SG_ 784 DrvWndPosStat "ENM";
BA_ "SignalLongName" SG_ 784 DrvWndPosStat "Driver Window Position Status";
BA_ "VNSigAllNodes" SG_ 784 DrvWndPosStat 1;
BA_ "GenSigSendType" SG_ 784 InterLghtStat 10;
BA_ "SignalType" SG_ 784 InterLghtStat "ENM";
BA_ "SignalLongName" SG_ 784 InterLghtStat "Interior Light Status";
BA_ "VNSigAllNodes" SG_ 784 InterLghtStat 1;
BA_ "GenSigSendType" SG_ 784 DrvrHndsOnWhlZn3 10;
BA_ "SignalType" SG_ 784 DrvrHndsOnWhlZn3 "BLN";
BA_ "SignalLongName" SG_ 784 DrvrHndsOnWhlZn3 "Driver Hands On wheel Zone 3";
BA_ "VNSigAllNodes" SG_ 784 DrvrHndsOnWhlZn3 1;
BA_ "GenSigSendType" SG_ 784 DrvrHndsOnWhlZn2 10;
BA_ "SignalType" SG_ 784 DrvrHndsOnWhlZn2 "BLN";
BA_ "SignalLongName" SG_ 784 DrvrHndsOnWhlZn2 "Driver Hands On wheel Zone 2";
BA_ "VNSigAllNodes" SG_ 784 DrvrHndsOnWhlZn2 1;
BA_ "GenSigSendType" SG_ 784 DrvrHndsOnWhlZn1 10;
BA_ "SignalType" SG_ 784 DrvrHndsOnWhlZn1 "BLN";
BA_ "SignalLongName" SG_ 784 DrvrHndsOnWhlZn1 "Driver Hands On wheel Zone 1";
BA_ "VNSigAllNodes" SG_ 784 DrvrHndsOnWhlZn1 1;
BA_ "GenSigSendType" SG_ 784 WSWshSwAtv 10;
BA_ "SignalType" SG_ 784 WSWshSwAtv "BLN";
BA_ "SignalLongName" SG_ 784 WSWshSwAtv "Windshield Washer Switch Active";
BA_ "VNSigAllNodes" SG_ 784 WSWshSwAtv 1;
BA_ "GenSigSendType" SG_ 784 WSWprAct 10;
BA_ "SignalType" SG_ 784 WSWprAct "BLN";
BA_ "SignalLongName" SG_ 784 WSWprAct "Windshield Wiper Active";
BA_ "VNSigAllNodes" SG_ 784 WSWprAct 1;
BA_ "GenSigSendType" SG_ 784 RtLwBmFld 10;
BA_ "SignalType" SG_ 784 RtLwBmFld "BLN";
BA_ "SignalLongName" SG_ 784 RtLwBmFld "Right Low Beam Failed";
BA_ "VNSigAllNodes" SG_ 784 RtLwBmFld 1;
BA_ "GenSigSendType" SG_ 784 OtsdAmbtLtLvlStatV 10;
BA_ "SignalType" SG_ 784 OtsdAmbtLtLvlStatV "ENM";
BA_ "SignalLongName" SG_ 784 OtsdAmbtLtLvlStatV "Outside Ambient Light Level Status Validity";
BA_ "VNSigAllNodes" SG_ 784 OtsdAmbtLtLvlStatV 1;
BA_ "GenSigSendType" SG_ 784 OtsdAmbtLtLvlStat 10;
BA_ "SignalType" SG_ 784 OtsdAmbtLtLvlStat "ENM";
BA_ "SignalLongName" SG_ 784 OtsdAmbtLtLvlStat "Outside Ambient Light Level Status";
BA_ "VNSigAllNodes" SG_ 784 OtsdAmbtLtLvlStat 1;
BA_ "GenSigSendType" SG_ 784 LowBmAct 10;
BA_ "SignalType" SG_ 784 LowBmAct "BLN";
BA_ "SignalLongName" SG_ 784 LowBmAct "Low Beam Active";
BA_ "VNSigAllNodes" SG_ 784 LowBmAct 1;
BA_ "GenSigSendType" SG_ 784 LftLwBmFld 10;
BA_ "SignalType" SG_ 784 LftLwBmFld "BLN";
BA_ "SignalLongName" SG_ 784 LftLwBmFld "Left Low Beam Failed";
BA_ "VNSigAllNodes" SG_ 784 LftLwBmFld 1;
BA_ "GenSigSendType" SG_ 784 HighBmAct 10;
BA_ "SignalType" SG_ 784 HighBmAct "BLN";
BA_ "SignalLongName" SG_ 784 HighBmAct "High Beam Active";
BA_ "VNSigAllNodes" SG_ 784 HighBmAct 1;
BA_ "GenSigSendType" SG_ 784 TrStLgMdAtv 10;
BA_ "SignalType" SG_ 784 TrStLgMdAtv "BLN";
BA_ "SignalLongName" SG_ 784 TrStLgMdAtv "Transport Storage Logistic Mode Active";
BA_ "VNSigAllNodes" SG_ 784 TrStLgMdAtv 1;
BA_ "GenSigSendType" SG_ 784 SysPwrMd 10;
BA_ "SignalType" SG_ 784 SysPwrMd "ENM";
BA_ "SignalLongName" SG_ 784 SysPwrMd "System Power Mode";
BA_ "VNSigAllNodes" SG_ 784 SysPwrMd 1;
BA_ "GenSigSendType" SG_ 784 SysPwrMdV 10;
BA_ "SignalType" SG_ 784 SysPwrMdV "ENM";
BA_ "SignalLongName" SG_ 784 SysPwrMdV "System Power Mode Validity";
BA_ "VNSigAllNodes" SG_ 784 SysPwrMdV 1;
BA_ "VNSigSLHSSharedDiagnostic" SG_ 257 DgnInf 1;
BA_ "SignalType" SG_ 257 DgnInf "UNM";
BA_ "SignalLongName" SG_ 257 DgnInf "Diagnostic Information";
BA_ "VNSigAllNodes" SG_ 257 DgnInf 1;
BA_ "VNSigSLHSSharedDiagnostic" SG_ 592 DgnInf 1;
BA_ "SignalType" SG_ 592 DgnInf "UNM";
BA_ "SignalLongName" SG_ 592 DgnInf "Diagnostic Information";
BA_ "VNSigAllNodes" SG_ 592 DgnInf 1;
BA_ "VNSigSLHSSharedDiagnostic" SG_ 1360 DgnInf_OBJ550 1;
BA_ "SignalType" SG_ 1360 DgnInf_OBJ550 "UNM";
BA_ "SignalLongName" SG_ 1360 DgnInf_OBJ550 "Diagnostic Information OBJ550";
BA_ "VNSigAllNodes" SG_ 1360 DgnInf_OBJ550 1;
BA_ "VNSigSLHSSharedDiagnostic" SG_ 1621 DgnInf 1;
BA_ "SignalType" SG_ 1621 DgnInf "UNM";
BA_ "SignalLongName" SG_ 1621 DgnInf "Diagnostic Information";
BA_ "VNSigAllNodes" SG_ 1621 DgnInf 1;
BA_ "VNSigSLHSSharedDiagnostic" SG_ 581 DgnInf 1;
BA_ "SignalType" SG_ 581 DgnInf "UNM";
BA_ "SignalLongName" SG_ 581 DgnInf "Diagnostic Information";
BA_ "VNSigAllNodes" SG_ 581 DgnInf 1;
BA_ "VNSigSLHSSharedDiagnostic" SG_ 1627 DgnInf 1;
BA_ "SignalType" SG_ 1627 DgnInf "UNM";
BA_ "SignalLongName" SG_ 1627 DgnInf "Diagnostic Information";
BA_ "VNSigAllNodes" SG_ 1627 DgnInf 1;
BA_ "VNSigSLHSSharedDiagnostic" SG_ 1371 DgnInf_FO55B 1;
BA_ "SignalType" SG_ 1371 DgnInf_FO55B "UNM";
BA_ "SignalLongName" SG_ 1371 DgnInf_FO55B "Diagnostic Information FO55B";
BA_ "VNSigAllNodes" SG_ 1371 DgnInf_FO55B 1;
BA_ "VNSigSLHSSharedDiagnostic" SG_ 603 DgnInf 1;
BA_ "SignalType" SG_ 603 DgnInf "UNM";
BA_ "SignalLongName" SG_ 603 DgnInf "Diagnostic Information";
BA_ "VNSigAllNodes" SG_ 603 DgnInf 1;
BA_ "SignalType" SG_ 1915 DTCI_DTCFaultType_77B "ENM";
BA_ "PacketOrder" SG_ 1915 DTCI_DTCFaultType_77B 20;
BA_ "SignalLongName" SG_ 1915 DTCI_DTCFaultType_77B "Diagnostic Trouble Code Information Extended 77B : Diagnostic Trouble Code Fault Type";
BA_ "VNSigAllNodes" SG_ 1915 DTCI_DTCFaultType_77B 1;
BA_ "SignalType" SG_ 1915 DTCI_CodeSupported_77B "BLN";
BA_ "PacketOrder" SG_ 1915 DTCI_CodeSupported_77B 19;
BA_ "SignalLongName" SG_ 1915 DTCI_CodeSupported_77B "Diagnostic Trouble Code Information Extended 77B : Code Supported";
BA_ "VNSigAllNodes" SG_ 1915 DTCI_CodeSupported_77B 1;
BA_ "SignalType" SG_ 1915 DTCI_CurrentStatus_77B "BLN";
BA_ "PacketOrder" SG_ 1915 DTCI_CurrentStatus_77B 18;
BA_ "SignalLongName" SG_ 1915 DTCI_CurrentStatus_77B "Diagnostic Trouble Code Information Extended 77B : Current Status";
BA_ "VNSigAllNodes" SG_ 1915 DTCI_CurrentStatus_77B 1;
BA_ "SignalType" SG_ 1915 DTCI_TstNPsdCdClrdSt_77B "BLN";
BA_ "PacketOrder" SG_ 1915 DTCI_TstNPsdCdClrdSt_77B 17;
BA_ "SignalLongName" SG_ 1915 DTCI_TstNPsdCdClrdSt_77B "Diagnostic Trouble Code Information Extended 77B : Test Not Passed Since Code Cleared Status";
BA_ "VNSigAllNodes" SG_ 1915 DTCI_TstNPsdCdClrdSt_77B 1;
BA_ "SignalType" SG_ 1915 DTCI_TstFldCdClrdStat_77B "BLN";
BA_ "PacketOrder" SG_ 1915 DTCI_TstFldCdClrdStat_77B 16;
BA_ "SignalLongName" SG_ 1915 DTCI_TstFldCdClrdStat_77B "Diagnostic Trouble Code Information Extended 77B : Test Failed Since Code Cleared Status";
BA_ "VNSigAllNodes" SG_ 1915 DTCI_TstFldCdClrdStat_77B 1;
BA_ "SignalType" SG_ 1915 DTCI_HistStat_77B "BLN";
BA_ "PacketOrder" SG_ 1915 DTCI_HistStat_77B 15;
BA_ "SignalLongName" SG_ 1915 DTCI_HistStat_77B "Diagnostic Trouble Code Information Extended 77B : History Status";
BA_ "VNSigAllNodes" SG_ 1915 DTCI_HistStat_77B 1;
BA_ "SignalType" SG_ 1915 DTCI_TstNPsdPwrUpSt_77B "BLN";
BA_ "PacketOrder" SG_ 1915 DTCI_TstNPsdPwrUpSt_77B 14;
BA_ "SignalLongName" SG_ 1915 DTCI_TstNPsdPwrUpSt_77B "Diagnostic Trouble Code Information Extended 77B : Test Not Passed Since Power Up Status";
BA_ "VNSigAllNodes" SG_ 1915 DTCI_TstNPsdPwrUpSt_77B 1;
BA_ "SignalType" SG_ 1915 DTCI_TstFldPwrUpSt_77B "BLN";
BA_ "PacketOrder" SG_ 1915 DTCI_TstFldPwrUpSt_77B 13;
BA_ "SignalLongName" SG_ 1915 DTCI_TstFldPwrUpSt_77B "Diagnostic Trouble Code Information Extended 77B : Test Failed Since Power Up Status";
BA_ "VNSigAllNodes" SG_ 1915 DTCI_TstFldPwrUpSt_77B 1;
BA_ "SignalType" SG_ 1915 DTCI_WrnIndRqdSt_77B "BLN";
BA_ "PacketOrder" SG_ 1915 DTCI_WrnIndRqdSt_77B 12;
BA_ "SignalLongName" SG_ 1915 DTCI_WrnIndRqdSt_77B "Diagnostic Trouble Code Information Extended 77B : Warning Indicator Requested Status";
BA_ "VNSigAllNodes" SG_ 1915 DTCI_WrnIndRqdSt_77B 1;
BA_ "SignalType" SG_ 1915 DTCI_DTCFailType_77B "UNM";
BA_ "PacketOrder" SG_ 1915 DTCI_DTCFailType_77B 11;
BA_ "SignalLongName" SG_ 1915 DTCI_DTCFailType_77B "Diagnostic Trouble Code Information Extended 77B : Diagnostic Trouble Code Failure Type";
BA_ "VNSigAllNodes" SG_ 1915 DTCI_DTCFailType_77B 1;
BA_ "SignalType" SG_ 1915 DTCI_DTCNumber_77B "UNM";
BA_ "PacketOrder" SG_ 1915 DTCI_DTCNumber_77B 10;
BA_ "SignalLongName" SG_ 1915 DTCI_DTCNumber_77B "Diagnostic Trouble Code Information Extended 77B : Diagnostic Trouble Code Number";
BA_ "VNSigAllNodes" SG_ 1915 DTCI_DTCNumber_77B 1;
BA_ "SignalType" SG_ 1915 DTCI_DTCSource_77B "UNM";
BA_ "PacketOrder" SG_ 1915 DTCI_DTCSource_77B 9;
BA_ "SignalLongName" SG_ 1915 DTCI_DTCSource_77B "Diagnostic Trouble Code Information Extended 77B : Diagnostic Trouble Code Source";
BA_ "VNSigAllNodes" SG_ 1915 DTCI_DTCSource_77B 1;
BA_ "SignalType" SG_ 1915 DTCI_DTCTriggered_77B "BLN";
BA_ "PacketOrder" SG_ 1915 DTCI_DTCTriggered_77B 8;
BA_ "SignalLongName" SG_ 1915 DTCI_DTCTriggered_77B "Diagnostic Trouble Code Information Extended 77B : Diagnostic Trouble Code Triggered";
BA_ "VNSigAllNodes" SG_ 1915 DTCI_DTCTriggered_77B 1;
BA_ "SignalType" SG_ 1915 DTCIUnused7_77B "BLN";
BA_ "PacketOrder" SG_ 1915 DTCIUnused7_77B 7;
BA_ "SignalLongName" SG_ 1915 DTCIUnused7_77B "Diagnostic Trouble Code Information Extended 77B : Unused 7";
BA_ "VNSigAllNodes" SG_ 1915 DTCIUnused7_77B 1;
BA_ "SignalType" SG_ 1915 DTCIUnused6_77B "BLN";
BA_ "PacketOrder" SG_ 1915 DTCIUnused6_77B 6;
BA_ "SignalLongName" SG_ 1915 DTCIUnused6_77B "Diagnostic Trouble Code Information Extended 77B : Unused 6";
BA_ "VNSigAllNodes" SG_ 1915 DTCIUnused6_77B 1;
BA_ "SignalType" SG_ 1915 DTCIUnused5_77B "BLN";
BA_ "PacketOrder" SG_ 1915 DTCIUnused5_77B 5;
BA_ "SignalLongName" SG_ 1915 DTCIUnused5_77B "Diagnostic Trouble Code Information Extended 77B : Unused 5";
BA_ "VNSigAllNodes" SG_ 1915 DTCIUnused5_77B 1;
BA_ "SignalType" SG_ 1915 DTCIUnused4_77B "BLN";
BA_ "PacketOrder" SG_ 1915 DTCIUnused4_77B 4;
BA_ "SignalLongName" SG_ 1915 DTCIUnused4_77B "Diagnostic Trouble Code Information Extended 77B : Unused 4";
BA_ "VNSigAllNodes" SG_ 1915 DTCIUnused4_77B 1;
BA_ "SignalType" SG_ 1915 DTCIUnused3_77B "BLN";
BA_ "PacketOrder" SG_ 1915 DTCIUnused3_77B 3;
BA_ "SignalLongName" SG_ 1915 DTCIUnused3_77B "Diagnostic Trouble Code Information Extended 77B : Unused 3";
BA_ "VNSigAllNodes" SG_ 1915 DTCIUnused3_77B 1;
BA_ "SignalType" SG_ 1915 DTCIUnused2_77B "BLN";
BA_ "PacketOrder" SG_ 1915 DTCIUnused2_77B 2;
BA_ "SignalLongName" SG_ 1915 DTCIUnused2_77B "Diagnostic Trouble Code Information Extended 77B : Unused 2";
BA_ "VNSigAllNodes" SG_ 1915 DTCIUnused2_77B 1;
BA_ "SignalType" SG_ 1915 DTCIUnused1_77B "BLN";
BA_ "PacketOrder" SG_ 1915 DTCIUnused1_77B 1;
BA_ "SignalLongName" SG_ 1915 DTCIUnused1_77B "Diagnostic Trouble Code Information Extended 77B : Unused 1";
BA_ "VNSigAllNodes" SG_ 1915 DTCIUnused1_77B 1;
BA_REL_ "GenSigSuprvResp" BU_SG_REL_ CECM_R1_FO SG_ 800 FSRoadSplashDetRng 1;
BA_REL_ "GenSigTimeoutMsg" BU_SG_REL_ CECM_R1_FO SG_ 800 FSRoadSplashDetRng 800;
BA_REL_ "GenSigTimeoutTime" BU_SG_REL_ CECM_R1_FO SG_ 800 FSRoadSplashDetRng 100;
BA_REL_ "GenSigSuprvResp" BU_SG_REL_ CECM_R1_FO SG_ 800 FSSmearedSpotsDetRng 1;
BA_REL_ "GenSigTimeoutMsg" BU_SG_REL_ CECM_R1_FO SG_ 800 FSSmearedSpotsDetRng 800;
BA_REL_ "GenSigTimeoutTime" BU_SG_REL_ CECM_R1_FO SG_ 800 FSSmearedSpotsDetRng 100;
BA_REL_ "GenSigSuprvResp" BU_SG_REL_ CECM_R1_FO SG_ 800 FSPartialBlockageDetRng 1;
BA_REL_ "GenSigTimeoutMsg" BU_SG_REL_ CECM_R1_FO SG_ 800 FSPartialBlockageDetRng 800;
BA_REL_ "GenSigTimeoutTime" BU_SG_REL_ CECM_R1_FO SG_ 800 FSPartialBlockageDetRng 100;
BA_REL_ "GenSigSuprvResp" BU_SG_REL_ CECM_R1_FO SG_ 800 FSLowSunDetRng 1;
BA_REL_ "GenSigTimeoutMsg" BU_SG_REL_ CECM_R1_FO SG_ 800 FSLowSunDetRng 800;
BA_REL_ "GenSigTimeoutTime" BU_SG_REL_ CECM_R1_FO SG_ 800 FSLowSunDetRng 100;
BA_REL_ "GenSigSuprvResp" BU_SG_REL_ CECM_R1_FO SG_ 800 FSBfulblocageDetRng 1;
BA_REL_ "GenSigTimeoutMsg" BU_SG_REL_ CECM_R1_FO SG_ 800 FSBfulblocageDetRng 800;
BA_REL_ "GenSigTimeoutTime" BU_SG_REL_ CECM_R1_FO SG_ 800 FSBfulblocageDetRng 100;
BA_REL_ "GenSigSuprvResp" BU_SG_REL_ CECM_R1_FO SG_ 800 FSFoggySpotsDetRng 1;
BA_REL_ "GenSigTimeoutMsg" BU_SG_REL_ CECM_R1_FO SG_ 800 FSFoggySpotsDetRng 800;
BA_REL_ "GenSigTimeoutTime" BU_SG_REL_ CECM_R1_FO SG_ 800 FSFoggySpotsDetRng 100;
BA_REL_ "GenSigSuprvResp" BU_SG_REL_ CECM_R1_FO SG_ 800 FSBlurredImageDetRng 1;
BA_REL_ "GenSigTimeoutMsg" BU_SG_REL_ CECM_R1_FO SG_ 800 FSBlurredImageDetRng 800;
BA_REL_ "GenSigTimeoutTime" BU_SG_REL_ CECM_R1_FO SG_ 800 FSBlurredImageDetRng 100;
BA_REL_ "GenSigSuprvResp" BU_SG_REL_ CECM_R1_FO SG_ 781 FHTObjType 1;
BA_REL_ "GenSigTimeoutMsg" BU_SG_REL_ CECM_R1_FO SG_ 781 FHTObjType 781;
BA_REL_ "GenSigTimeoutTime" BU_SG_REL_ CECM_R1_FO SG_ 781 FHTObjType 100;
BA_REL_ "GenSigSuprvResp" BU_SG_REL_ CECM_R1_FO SG_ 781 FHTRellogiacc 1;
BA_REL_ "GenSigTimeoutMsg" BU_SG_REL_ CECM_R1_FO SG_ 781 FHTRellogiacc 781;
BA_REL_ "GenSigTimeoutTime" BU_SG_REL_ CECM_R1_FO SG_ 781 FHTRellogiacc 100;
BA_REL_ "GenSigSuprvResp" BU_SG_REL_ CECM_R1_FO SG_ 781 FHTPedObjType 1;
BA_REL_ "GenSigTimeoutMsg" BU_SG_REL_ CECM_R1_FO SG_ 781 FHTPedObjType 781;
BA_REL_ "GenSigTimeoutTime" BU_SG_REL_ CECM_R1_FO SG_ 781 FHTPedObjType 100;
BA_REL_ "GenSigSuprvResp" BU_SG_REL_ CECM_R1_FO SG_ 781 CIPMpedbrknw 1;
BA_REL_ "GenSigTimeoutMsg" BU_SG_REL_ CECM_R1_FO SG_ 781 CIPMpedbrknw 781;
BA_REL_ "GenSigTimeoutTime" BU_SG_REL_ CECM_R1_FO SG_ 781 CIPMpedbrknw 100;
BA_REL_ "GenSigSuprvResp" BU_SG_REL_ CECM_R1_FO SG_ 781 FHTObjTTC 1;
BA_REL_ "GenSigTimeoutMsg" BU_SG_REL_ CECM_R1_FO SG_ 781 FHTObjTTC 781;
BA_REL_ "GenSigTimeoutTime" BU_SG_REL_ CECM_R1_FO SG_ 781 FHTObjTTC 100;
BA_REL_ "GenSigSuprvResp" BU_SG_REL_ CECM_R1_FO SG_ 804 FHTPedTTC 1;
BA_REL_ "GenSigTimeoutMsg" BU_SG_REL_ CECM_R1_FO SG_ 804 FHTPedTTC 804;
BA_REL_ "GenSigTimeoutTime" BU_SG_REL_ CECM_R1_FO SG_ 804 FHTPedTTC 100;
BA_REL_ "GenSigSuprvResp" BU_SG_REL_ CECM_R1_FO SG_ 804 FHTPedVy 1;
BA_REL_ "GenSigTimeoutMsg" BU_SG_REL_ CECM_R1_FO SG_ 804 FHTPedVy 804;
BA_REL_ "GenSigTimeoutTime" BU_SG_REL_ CECM_R1_FO SG_ 804 FHTPedVy 100;
BA_REL_ "GenSigSuprvResp" BU_SG_REL_ CECM_R1_FO SG_ 804 FHTPedVx 1;
BA_REL_ "GenSigTimeoutMsg" BU_SG_REL_ CECM_R1_FO SG_ 804 FHTPedVx 804;
BA_REL_ "GenSigTimeoutTime" BU_SG_REL_ CECM_R1_FO SG_ 804 FHTPedVx 100;
BA_REL_ "GenSigSuprvResp" BU_SG_REL_ CECM_R1_FO SG_ 804 FHTPedLy 1;
BA_REL_ "GenSigTimeoutMsg" BU_SG_REL_ CECM_R1_FO SG_ 804 FHTPedLy 804;
BA_REL_ "GenSigTimeoutTime" BU_SG_REL_ CECM_R1_FO SG_ 804 FHTPedLy 100;
BA_REL_ "GenSigSuprvResp" BU_SG_REL_ CECM_R1_FO SG_ 804 FHTPedLx 1;
BA_REL_ "GenSigTimeoutMsg" BU_SG_REL_ CECM_R1_FO SG_ 804 FHTPedLx 804;
BA_REL_ "GenSigTimeoutTime" BU_SG_REL_ CECM_R1_FO SG_ 804 FHTPedLx 100;
BA_REL_ "GenSigSuprvResp" BU_SG_REL_ CECM_R1_FO SG_ 801 HiTHreatDynProp 1;
BA_REL_ "GenSigTimeoutMsg" BU_SG_REL_ CECM_R1_FO SG_ 801 HiTHreatDynProp 801;
BA_REL_ "GenSigTimeoutTime" BU_SG_REL_ CECM_R1_FO SG_ 801 HiTHreatDynProp 100;
BA_REL_ "GenSigSuprvResp" BU_SG_REL_ CECM_R1_FO SG_ 801 HiTHreaIndseninobjinques 1;
BA_REL_ "GenSigTimeoutMsg" BU_SG_REL_ CECM_R1_FO SG_ 801 HiTHreaIndseninobjinques 801;
BA_REL_ "GenSigTimeoutTime" BU_SG_REL_ CECM_R1_FO SG_ 801 HiTHreaIndseninobjinques 100;
BA_REL_ "GenSigSuprvResp" BU_SG_REL_ CECM_R1_FO SG_ 801 FHTobjVy 1;
BA_REL_ "GenSigTimeoutMsg" BU_SG_REL_ CECM_R1_FO SG_ 801 FHTobjVy 801;
BA_REL_ "GenSigTimeoutTime" BU_SG_REL_ CECM_R1_FO SG_ 801 FHTobjVy 100;
BA_REL_ "GenSigSuprvResp" BU_SG_REL_ CECM_R1_FO SG_ 801 FHTObjVx 1;
BA_REL_ "GenSigTimeoutMsg" BU_SG_REL_ CECM_R1_FO SG_ 801 FHTObjVx 801;
BA_REL_ "GenSigTimeoutTime" BU_SG_REL_ CECM_R1_FO SG_ 801 FHTObjVx 100;
BA_REL_ "GenSigSuprvResp" BU_SG_REL_ CECM_R1_FO SG_ 801 FHTObjLy 1;
BA_REL_ "GenSigTimeoutMsg" BU_SG_REL_ CECM_R1_FO SG_ 801 FHTObjLy 801;
BA_REL_ "GenSigTimeoutTime" BU_SG_REL_ CECM_R1_FO SG_ 801 FHTObjLy 100;
BA_REL_ "GenSigSuprvResp" BU_SG_REL_ CECM_R1_FO SG_ 801 FHTObjLx 1;
BA_REL_ "GenSigTimeoutMsg" BU_SG_REL_ CECM_R1_FO SG_ 801 FHTObjLx 801;
BA_REL_ "GenSigTimeoutTime" BU_SG_REL_ CECM_R1_FO SG_ 801 FHTObjLx 100;
BA_REL_ "GenSigSuprvResp" BU_SG_REL_ CECM_R1_FO SG_ 801 FHTObjID 1;
BA_REL_ "GenSigTimeoutMsg" BU_SG_REL_ CECM_R1_FO SG_ 801 FHTObjID 801;
BA_REL_ "GenSigTimeoutTime" BU_SG_REL_ CECM_R1_FO SG_ 801 FHTObjID 100;
BA_REL_ "GenSigSuprvResp" BU_SG_REL_ CECM_R1_FO SG_ 777 Yawrt 1;
BA_REL_ "GenSigTimeoutMsg" BU_SG_REL_ CECM_R1_FO SG_ 777 Yawrt 777;
BA_REL_ "GenSigTimeoutTime" BU_SG_REL_ CECM_R1_FO SG_ 777 Yawrt 100;
BA_REL_ "GenSigSuprvResp" BU_SG_REL_ CECM_R1_FO SG_ 777 VehVel 1;
BA_REL_ "GenSigTimeoutMsg" BU_SG_REL_ CECM_R1_FO SG_ 777 VehVel 777;
BA_REL_ "GenSigTimeoutTime" BU_SG_REL_ CECM_R1_FO SG_ 777 VehVel 100;
BA_REL_ "GenSigSuprvResp" BU_SG_REL_ CECM_R1_FO SG_ 777 RHTObjID 1;
BA_REL_ "GenSigTimeoutMsg" BU_SG_REL_ CECM_R1_FO SG_ 777 RHTObjID 777;
BA_REL_ "GenSigTimeoutTime" BU_SG_REL_ CECM_R1_FO SG_ 777 RHTObjID 100;
BA_REL_ "GenSigSuprvResp" BU_SG_REL_ CECM_R1_FO SG_ 777 RHTObjtmtoclsn 1;
BA_REL_ "GenSigTimeoutMsg" BU_SG_REL_ CECM_R1_FO SG_ 777 RHTObjtmtoclsn 777;
BA_REL_ "GenSigTimeoutTime" BU_SG_REL_ CECM_R1_FO SG_ 777 RHTObjtmtoclsn 100;
BA_REL_ "GenSigSuprvResp" BU_SG_REL_ CECM_R1_FO SG_ 777 RHTObjPstn 1;
BA_REL_ "GenSigTimeoutMsg" BU_SG_REL_ CECM_R1_FO SG_ 777 RHTObjPstn 777;
BA_REL_ "GenSigTimeoutTime" BU_SG_REL_ CECM_R1_FO SG_ 777 RHTObjPstn 100;
BA_REL_ "GenSigTimeoutMsg" BU_SG_REL_ CIPM_FO SG_ 161 SensorModeCmdFCamera 161;
BA_REL_ "GenSigTimeoutTime" BU_SG_REL_ CIPM_FO SG_ 161 SensorModeCmdFCamera 250;
BA_REL_ "GenSigTimeoutMsg" BU_SG_REL_ RSRR_FO SG_ 161 SensorModeCmdSRR 161;
BA_REL_ "GenSigTimeoutTime" BU_SG_REL_ RSRR_FO SG_ 161 SensorModeCmdSRR 250;
BA_REL_ "GenSigTimeoutMsg" BU_SG_REL_ RSRR_FO SG_ 161 SensorModeCmdSRR 161;
BA_REL_ "GenSigTimeoutTime" BU_SG_REL_ RSRR_FO SG_ 161 SensorModeCmdSRR 250;
BA_REL_ "GenSigTimeoutMsg" BU_SG_REL_ LRR_FO SG_ 161 SensorModeCmdLRR 161;
BA_REL_ "GenSigTimeoutTime" BU_SG_REL_ LRR_FO SG_ 161 SensorModeCmdLRR 250;
BA_REL_ "GenSigTimeoutMsg" BU_SG_REL_ CIPM_FO SG_ 161 FTimeSyncMstrClock 161;
BA_REL_ "GenSigTimeoutTime" BU_SG_REL_ CIPM_FO SG_ 161 FTimeSyncMstrClock 250;
BA_REL_ "GenSigTimeoutMsg" BU_SG_REL_ RSRR_FO SG_ 161 FTimeSyncMstrClock 161;
BA_REL_ "GenSigTimeoutTime" BU_SG_REL_ RSRR_FO SG_ 161 FTimeSyncMstrClock 250;
BA_REL_ "GenSigTimeoutMsg" BU_SG_REL_ RSRR_FO SG_ 161 FTimeSyncMstrClock 161;
BA_REL_ "GenSigTimeoutTime" BU_SG_REL_ RSRR_FO SG_ 161 FTimeSyncMstrClock 250;
BA_REL_ "GenSigTimeoutMsg" BU_SG_REL_ LRR_FO SG_ 161 FTimeSyncMstrClock 161;
BA_REL_ "GenSigTimeoutTime" BU_SG_REL_ LRR_FO SG_ 161 FTimeSyncMstrClock 250;
BA_REL_ "GenSigTimeoutMsg" BU_SG_REL_ LRR_FO SG_ 161 FTimeSyncMstrClock 161;
BA_REL_ "GenSigTimeoutTime" BU_SG_REL_ LRR_FO SG_ 161 FTimeSyncMstrClock 250;
BA_REL_ "GenSigTimeoutMsg" BU_SG_REL_ CIPM_FO SG_ 161 FTimeSyncMstrChksm 161;
BA_REL_ "GenSigTimeoutTime" BU_SG_REL_ CIPM_FO SG_ 161 FTimeSyncMstrChksm 250;
BA_REL_ "GenSigTimeoutMsg" BU_SG_REL_ RSRR_FO SG_ 161 FTimeSyncMstrChksm 161;
BA_REL_ "GenSigTimeoutTime" BU_SG_REL_ RSRR_FO SG_ 161 FTimeSyncMstrChksm 250;
BA_REL_ "GenSigTimeoutMsg" BU_SG_REL_ RSRR_FO SG_ 161 FTimeSyncMstrChksm 161;
BA_REL_ "GenSigTimeoutTime" BU_SG_REL_ RSRR_FO SG_ 161 FTimeSyncMstrChksm 250;
BA_REL_ "GenSigTimeoutMsg" BU_SG_REL_ LRR_FO SG_ 161 FTimeSyncMstrChksm 161;
BA_REL_ "GenSigTimeoutTime" BU_SG_REL_ LRR_FO SG_ 161 FTimeSyncMstrChksm 250;
BA_REL_ "GenSigTimeoutMsg" BU_SG_REL_ LRR_FO SG_ 161 FTimeSyncMstrChksm 161;
BA_REL_ "GenSigTimeoutTime" BU_SG_REL_ LRR_FO SG_ 161 FTimeSyncMstrChksm 250;
BA_REL_ "GenSigTimeoutMsg" BU_SG_REL_ CIPM_FO SG_ 776 Vpath_Data2ModeInfo 776;
BA_REL_ "GenSigTimeoutTime" BU_SG_REL_ CIPM_FO SG_ 776 Vpath_Data2ModeInfo 50;
BA_REL_ "GenSigTimeoutTime" BU_SG_REL_ RSRR_FO SG_ 776 Vpath_Data2ModeInfo 250;
BA_REL_ "GenSigTimeoutTime" BU_SG_REL_ RSRR_FO SG_ 776 Vpath_Data2ModeInfo 250;
BA_REL_ "GenSigTimeoutMsg" BU_SG_REL_ LRR_FO SG_ 776 Vpath_Data2ModeInfo 776;
BA_REL_ "GenSigTimeoutTime" BU_SG_REL_ LRR_FO SG_ 776 Vpath_Data2ModeInfo 120;
BA_REL_ "GenSigTimeoutMsg" BU_SG_REL_ CIPM_FO SG_ 776 Vpath2_Checksum 776;
BA_REL_ "GenSigTimeoutTime" BU_SG_REL_ CIPM_FO SG_ 776 Vpath2_Checksum 50;
BA_REL_ "GenSigTimeoutTime" BU_SG_REL_ RSRR_FO SG_ 776 Vpath2_Checksum 250;
BA_REL_ "GenSigTimeoutMsg" BU_SG_REL_ LRR_FO SG_ 776 Vpath2_Checksum 776;
BA_REL_ "GenSigTimeoutTime" BU_SG_REL_ LRR_FO SG_ 776 Vpath2_Checksum 120;
BA_REL_ "GenSigTimeoutMsg" BU_SG_REL_ CIPM_FO SG_ 776 Vpath_Data2RollCnt 776;
BA_REL_ "GenSigTimeoutTime" BU_SG_REL_ CIPM_FO SG_ 776 Vpath_Data2RollCnt 50;
BA_REL_ "GenSigTimeoutTime" BU_SG_REL_ RSRR_FO SG_ 776 Vpath_Data2RollCnt 250;
BA_REL_ "GenSigTimeoutTime" BU_SG_REL_ RSRR_FO SG_ 776 Vpath_Data2RollCnt 250;
BA_REL_ "GenSigTimeoutMsg" BU_SG_REL_ LRR_FO SG_ 776 Vpath_Data2RollCnt 776;
BA_REL_ "GenSigTimeoutTime" BU_SG_REL_ LRR_FO SG_ 776 Vpath_Data2RollCnt 120;
BA_REL_ "GenSigTimeoutMsg" BU_SG_REL_ LRR_FO SG_ 776 Vpath_Data2RollCnt 776;
BA_REL_ "GenSigTimeoutTime" BU_SG_REL_ LRR_FO SG_ 776 Vpath_Data2RollCnt 120;
BA_REL_ "GenSigTimeoutMsg" BU_SG_REL_ CIPM_FO SG_ 776 Vpath_Data2TravlDirctn 776;
BA_REL_ "GenSigTimeoutTime" BU_SG_REL_ CIPM_FO SG_ 776 Vpath_Data2TravlDirctn 50;
BA_REL_ "GenSigTimeoutTime" BU_SG_REL_ RSRR_FO SG_ 776 Vpath_Data2TravlDirctn 250;
BA_REL_ "GenSigTimeoutTime" BU_SG_REL_ RSRR_FO SG_ 776 Vpath_Data2TravlDirctn 250;
BA_REL_ "GenSigTimeoutMsg" BU_SG_REL_ LRR_FO SG_ 776 Vpath_Data2TravlDirctn 776;
BA_REL_ "GenSigTimeoutTime" BU_SG_REL_ LRR_FO SG_ 776 Vpath_Data2TravlDirctn 120;
BA_REL_ "GenSigTimeoutMsg" BU_SG_REL_ LRR_FO SG_ 776 Vpath_Data2TravlDirctn 776;
BA_REL_ "GenSigTimeoutTime" BU_SG_REL_ LRR_FO SG_ 776 Vpath_Data2TravlDirctn 120;
BA_REL_ "GenSigTimeoutMsg" BU_SG_REL_ CIPM_FO SG_ 776 Vpath_Data2LongVel 776;
BA_REL_ "GenSigTimeoutTime" BU_SG_REL_ CIPM_FO SG_ 776 Vpath_Data2LongVel 50;
BA_REL_ "GenSigTimeoutTime" BU_SG_REL_ RSRR_FO SG_ 776 Vpath_Data2LongVel 250;
BA_REL_ "GenSigTimeoutTime" BU_SG_REL_ RSRR_FO SG_ 776 Vpath_Data2LongVel 250;
BA_REL_ "GenSigTimeoutMsg" BU_SG_REL_ LRR_FO SG_ 776 Vpath_Data2LongVel 776;
BA_REL_ "GenSigTimeoutTime" BU_SG_REL_ LRR_FO SG_ 776 Vpath_Data2LongVel 120;
BA_REL_ "GenSigTimeoutMsg" BU_SG_REL_ LRR_FO SG_ 776 Vpath_Data2LongVel 776;
BA_REL_ "GenSigTimeoutTime" BU_SG_REL_ LRR_FO SG_ 776 Vpath_Data2LongVel 120;
BA_REL_ "GenSigTimeoutMsg" BU_SG_REL_ CIPM_FO SG_ 776 Vpath_Data2YawRate 776;
BA_REL_ "GenSigTimeoutTime" BU_SG_REL_ CIPM_FO SG_ 776 Vpath_Data2YawRate 50;
BA_REL_ "GenSigTimeoutTime" BU_SG_REL_ RSRR_FO SG_ 776 Vpath_Data2YawRate 250;
BA_REL_ "GenSigTimeoutTime" BU_SG_REL_ RSRR_FO SG_ 776 Vpath_Data2YawRate 250;
BA_REL_ "GenSigTimeoutMsg" BU_SG_REL_ LRR_FO SG_ 776 Vpath_Data2YawRate 776;
BA_REL_ "GenSigTimeoutTime" BU_SG_REL_ LRR_FO SG_ 776 Vpath_Data2YawRate 120;
BA_REL_ "GenSigTimeoutMsg" BU_SG_REL_ LRR_FO SG_ 776 Vpath_Data2YawRate 776;
BA_REL_ "GenSigTimeoutTime" BU_SG_REL_ LRR_FO SG_ 776 Vpath_Data2YawRate 120;
BA_REL_ "GenSigTimeoutMsg" BU_SG_REL_ CIPM_FO SG_ 776 Vpath_Data2LatVel 776;
BA_REL_ "GenSigTimeoutTime" BU_SG_REL_ CIPM_FO SG_ 776 Vpath_Data2LatVel 50;
BA_REL_ "GenSigTimeoutTime" BU_SG_REL_ RSRR_FO SG_ 776 Vpath_Data2LatVel 250;
BA_REL_ "GenSigTimeoutTime" BU_SG_REL_ RSRR_FO SG_ 776 Vpath_Data2LatVel 250;
BA_REL_ "GenSigTimeoutMsg" BU_SG_REL_ LRR_FO SG_ 776 Vpath_Data2LatVel 776;
BA_REL_ "GenSigTimeoutTime" BU_SG_REL_ LRR_FO SG_ 776 Vpath_Data2LatVel 120;
BA_REL_ "GenSigTimeoutMsg" BU_SG_REL_ LRR_FO SG_ 776 Vpath_Data2LatVel 776;
BA_REL_ "GenSigTimeoutTime" BU_SG_REL_ LRR_FO SG_ 776 Vpath_Data2LatVel 120;
BA_REL_ "GenSigTimeoutMsg" BU_SG_REL_ CIPM_FO SG_ 774 Vpath_RollingCount 774;
BA_REL_ "GenSigTimeoutTime" BU_SG_REL_ CIPM_FO SG_ 774 Vpath_RollingCount 50;
BA_REL_ "GenSigTimeoutTime" BU_SG_REL_ RSRR_FO SG_ 774 Vpath_RollingCount 250;
BA_REL_ "GenSigTimeoutTime" BU_SG_REL_ RSRR_FO SG_ 774 Vpath_RollingCount 250;
BA_REL_ "GenSigTimeoutMsg" BU_SG_REL_ LRR_FO SG_ 774 Vpath_RollingCount 774;
BA_REL_ "GenSigTimeoutTime" BU_SG_REL_ LRR_FO SG_ 774 Vpath_RollingCount 120;
BA_REL_ "GenSigTimeoutMsg" BU_SG_REL_ LRR_FO SG_ 774 Vpath_RollingCount 774;
BA_REL_ "GenSigTimeoutTime" BU_SG_REL_ LRR_FO SG_ 774 Vpath_RollingCount 120;
BA_REL_ "GenSigTimeoutMsg" BU_SG_REL_ CIPM_FO SG_ 774 Vpath_Checksum 774;
BA_REL_ "GenSigTimeoutTime" BU_SG_REL_ CIPM_FO SG_ 774 Vpath_Checksum 50;
BA_REL_ "GenSigTimeoutMsg" BU_SG_REL_ LRR_FO SG_ 774 Vpath_Checksum 774;
BA_REL_ "GenSigTimeoutTime" BU_SG_REL_ LRR_FO SG_ 774 Vpath_Checksum 120;
BA_REL_ "GenSigTimeoutMsg" BU_SG_REL_ LRR_FO SG_ 774 Vpath_Checksum 774;
BA_REL_ "GenSigTimeoutTime" BU_SG_REL_ LRR_FO SG_ 774 Vpath_Checksum 120;
BA_REL_ "GenSigTimeoutMsg" BU_SG_REL_ CIPM_FO SG_ 774 Vpath_TrnCtrLngOfst 774;
BA_REL_ "GenSigTimeoutTime" BU_SG_REL_ CIPM_FO SG_ 774 Vpath_TrnCtrLngOfst 50;
BA_REL_ "GenSigTimeoutTime" BU_SG_REL_ RSRR_FO SG_ 774 Vpath_TrnCtrLngOfst 250;
BA_REL_ "GenSigTimeoutMsg" BU_SG_REL_ LRR_FO SG_ 774 Vpath_TrnCtrLngOfst 774;
BA_REL_ "GenSigTimeoutTime" BU_SG_REL_ LRR_FO SG_ 774 Vpath_TrnCtrLngOfst 120;
BA_REL_ "GenSigTimeoutMsg" BU_SG_REL_ CIPM_FO SG_ 774 Vpath_TrnCtrLatOfst 774;
BA_REL_ "GenSigTimeoutTime" BU_SG_REL_ CIPM_FO SG_ 774 Vpath_TrnCtrLatOfst 50;
BA_REL_ "GenSigTimeoutTime" BU_SG_REL_ RSRR_FO SG_ 774 Vpath_TrnCtrLatOfst 250;
BA_REL_ "GenSigTimeoutMsg" BU_SG_REL_ LRR_FO SG_ 774 Vpath_TrnCtrLatOfst 774;
BA_REL_ "GenSigTimeoutTime" BU_SG_REL_ LRR_FO SG_ 774 Vpath_TrnCtrLatOfst 120;
BA_REL_ "GenSigTimeoutMsg" BU_SG_REL_ CIPM_FO SG_ 774 Vpath_Curvature 774;
BA_REL_ "GenSigTimeoutTime" BU_SG_REL_ CIPM_FO SG_ 774 Vpath_Curvature 50;
BA_REL_ "GenSigTimeoutMsg" BU_SG_REL_ LRR_FO SG_ 774 Vpath_Curvature 774;
BA_REL_ "GenSigTimeoutTime" BU_SG_REL_ LRR_FO SG_ 774 Vpath_Curvature 120;
BA_REL_ "GenSigTimeoutMsg" BU_SG_REL_ LRR_FO SG_ 774 Vpath_Curvature 774;
BA_REL_ "GenSigTimeoutTime" BU_SG_REL_ LRR_FO SG_ 774 Vpath_Curvature 120;
BA_REL_ "GenSigTimeoutMsg" BU_SG_REL_ CIPM_FO SG_ 768 SmgrMotLongSpeed 768;
BA_REL_ "GenSigTimeoutTime" BU_SG_REL_ CIPM_FO SG_ 768 SmgrMotLongSpeed 125;
BA_REL_ "GenSigRxStartValue" BU_SG_REL_ CMMb_FO SG_ 264 InrtlSnsrMstrTrgrSync "0";
BA_REL_ "GenSigSuprvResp" BU_SG_REL_ CMMb_FO SG_ 264 InrtlSnsrMstrTrgrSync 1;
BA_REL_ "GenSigTimeoutMsg" BU_SG_REL_ CMMb_FO SG_ 264 InrtlSnsrMstrTrgrSync 264;
BA_REL_ "GenSigTimeoutTime" BU_SG_REL_ CMMb_FO SG_ 264 InrtlSnsrMstrTrgrSync 30;
BA_REL_ "GenSigRxStartValue" BU_SG_REL_ CMMa_FO SG_ 264 InrtlSnsrMstrTrgrSync "0";
BA_REL_ "GenSigSuprvResp" BU_SG_REL_ CMMa_FO SG_ 264 InrtlSnsrMstrTrgrSync 1;
BA_REL_ "GenSigTimeoutMsg" BU_SG_REL_ CMMa_FO SG_ 264 InrtlSnsrMstrTrgrSync 264;
BA_REL_ "GenSigTimeoutTime" BU_SG_REL_ CMMa_FO SG_ 264 InrtlSnsrMstrTrgrSync 30;
BA_REL_ "GenSigVBitResp" BU_SG_REL_ EOCM2cp_K2_FO SG_ 848 LaneSenseSystemOK 1;
BA_REL_ "GenSigVBitResp" BU_SG_REL_ EOCM2cp_K1_FO SG_ 848 LaneSenseSystemOK 1;
BA_REL_ "GenSigVBitResp" BU_SG_REL_ EOCM2cp_IMX6_FO SG_ 848 LaneSenseSystemOK 1;
BA_REL_ "GenSigVBitResp" BU_SG_REL_ EOCM2cp_K2_FO SG_ 848 LaneSenseTimeStamp 1;
BA_REL_ "GenSigVBitResp" BU_SG_REL_ EOCM2cp_K1_FO SG_ 848 LaneSenseTimeStamp 1;
BA_REL_ "GenSigVBitResp" BU_SG_REL_ EOCM2cp_IMX6_FO SG_ 848 LaneSenseTimeStamp 1;
BA_REL_ "GenSigVBitResp" BU_SG_REL_ EOCM2cp_K2_FO SG_ 848 LnSnsTngtOfHdngLnRt 1;
BA_REL_ "GenSigVBitResp" BU_SG_REL_ EOCM2cp_K1_FO SG_ 848 LnSnsTngtOfHdngLnRt 1;
BA_REL_ "GenSigVBitResp" BU_SG_REL_ EOCM2cp_IMX6_FO SG_ 848 LnSnsTngtOfHdngLnRt 1;
BA_REL_ "GenSigVBitResp" BU_SG_REL_ EOCM2cp_K2_FO SG_ 849 LnSnsCrvtGrdntRt 1;
BA_REL_ "GenSigVBitResp" BU_SG_REL_ EOCM2cp_K1_FO SG_ 849 LnSnsCrvtGrdntRt 1;
BA_REL_ "GenSigVBitResp" BU_SG_REL_ EOCM2cp_IMX6_FO SG_ 849 LnSnsCrvtGrdntRt 1;
BA_REL_ "GenSigVBitResp" BU_SG_REL_ EOCM2cp_K2_FO SG_ 849 LnSnsLnCrvtrRght 1;
BA_REL_ "GenSigVBitResp" BU_SG_REL_ EOCM2cp_K1_FO SG_ 849 LnSnsLnCrvtrRght 1;
BA_REL_ "GenSigVBitResp" BU_SG_REL_ EOCM2cp_IMX6_FO SG_ 849 LnSnsLnCrvtrRght 1;
BA_REL_ "GenSigVBitResp" BU_SG_REL_ EOCM2cp_K2_FO SG_ 850 LnSnsLnCrvtrLft 1;
BA_REL_ "GenSigVBitResp" BU_SG_REL_ EOCM2cp_K1_FO SG_ 850 LnSnsLnCrvtrLft 1;
BA_REL_ "GenSigVBitResp" BU_SG_REL_ EOCM2cp_IMX6_FO SG_ 850 LnSnsLnCrvtrLft 1;
BA_REL_ "GenSigVBitResp" BU_SG_REL_ EOCM2cp_K2_FO SG_ 850 LnSnsTngtOfHdngLnLft 1;
BA_REL_ "GenSigVBitResp" BU_SG_REL_ EOCM2cp_K1_FO SG_ 850 LnSnsTngtOfHdngLnLft 1;
BA_REL_ "GenSigVBitResp" BU_SG_REL_ EOCM2cp_IMX6_FO SG_ 850 LnSnsTngtOfHdngLnLft 1;
BA_REL_ "GenSigVBitResp" BU_SG_REL_ EOCM2cp_K2_FO SG_ 851 LnSnsCrvtGrdntLft 1;
BA_REL_ "GenSigVBitResp" BU_SG_REL_ EOCM2cp_K1_FO SG_ 851 LnSnsCrvtGrdntLft 1;
BA_REL_ "GenSigVBitResp" BU_SG_REL_ EOCM2cp_IMX6_FO SG_ 851 LnSnsCrvtGrdntLft 1;
BA_REL_ "GenSigVBitResp" BU_SG_REL_ EOCM2cp_K2_FO SG_ 852 LnMrkg3LnSnsLnCrvt 1;
BA_REL_ "GenSigVBitResp" BU_SG_REL_ EOCM2cp_K1_FO SG_ 852 LnMrkg3LnSnsLnCrvt 1;
BA_REL_ "GenSigVBitResp" BU_SG_REL_ EOCM2cp_IMX6_FO SG_ 852 LnMrkg3LnSnsLnCrvt 1;
BA_REL_ "GenSigVBitResp" BU_SG_REL_ EOCM2cp_K2_FO SG_ 852 LnMrkg3LnSnsLnCrvtGrad 1;
BA_REL_ "GenSigVBitResp" BU_SG_REL_ EOCM2cp_K1_FO SG_ 852 LnMrkg3LnSnsLnCrvtGrad 1;
BA_REL_ "GenSigVBitResp" BU_SG_REL_ EOCM2cp_IMX6_FO SG_ 852 LnMrkg3LnSnsLnCrvtGrad 1;
BA_REL_ "GenSigVBitResp" BU_SG_REL_ EOCM2cp_K2_FO SG_ 852 LnMrkg3LnSnsLnDst 1;
BA_REL_ "GenSigVBitResp" BU_SG_REL_ EOCM2cp_K1_FO SG_ 852 LnMrkg3LnSnsLnDst 1;
BA_REL_ "GenSigVBitResp" BU_SG_REL_ EOCM2cp_IMX6_FO SG_ 852 LnMrkg3LnSnsLnDst 1;
BA_REL_ "GenSigVBitResp" BU_SG_REL_ EOCM2cp_K2_FO SG_ 852 LnMrkg3LnSnsLnHdngTngt 1;
BA_REL_ "GenSigVBitResp" BU_SG_REL_ EOCM2cp_K1_FO SG_ 852 LnMrkg3LnSnsLnHdngTngt 1;
BA_REL_ "GenSigVBitResp" BU_SG_REL_ EOCM2cp_IMX6_FO SG_ 852 LnMrkg3LnSnsLnHdngTngt 1;
BA_REL_ "GenSigVBitResp" BU_SG_REL_ EOCM2cp_K2_FO SG_ 853 LnMrkg4LnSnsLnCrvt 1;
BA_REL_ "GenSigVBitResp" BU_SG_REL_ EOCM2cp_K1_FO SG_ 853 LnMrkg4LnSnsLnCrvt 1;
BA_REL_ "GenSigVBitResp" BU_SG_REL_ EOCM2cp_IMX6_FO SG_ 853 LnMrkg4LnSnsLnCrvt 1;
BA_REL_ "GenSigVBitResp" BU_SG_REL_ EOCM2cp_K2_FO SG_ 853 LnMrkg4LnSnsLnCrvtGrad 1;
BA_REL_ "GenSigVBitResp" BU_SG_REL_ EOCM2cp_K1_FO SG_ 853 LnMrkg4LnSnsLnCrvtGrad 1;
BA_REL_ "GenSigVBitResp" BU_SG_REL_ EOCM2cp_IMX6_FO SG_ 853 LnMrkg4LnSnsLnCrvtGrad 1;
BA_REL_ "GenSigVBitResp" BU_SG_REL_ EOCM2cp_K2_FO SG_ 853 LnMrkg4LnSnsLnDst 1;
BA_REL_ "GenSigVBitResp" BU_SG_REL_ EOCM2cp_K1_FO SG_ 853 LnMrkg4LnSnsLnDst 1;
BA_REL_ "GenSigVBitResp" BU_SG_REL_ EOCM2cp_IMX6_FO SG_ 853 LnMrkg4LnSnsLnDst 1;
BA_REL_ "GenSigVBitResp" BU_SG_REL_ EOCM2cp_K2_FO SG_ 853 LnMrkg4LnSnsLnHdngTngt 1;
BA_REL_ "GenSigVBitResp" BU_SG_REL_ EOCM2cp_K1_FO SG_ 853 LnMrkg4LnSnsLnHdngTngt 1;
BA_REL_ "GenSigVBitResp" BU_SG_REL_ EOCM2cp_IMX6_FO SG_ 853 LnMrkg4LnSnsLnHdngTngt 1;
BA_REL_ "GenSigRxStartValue" BU_SG_REL_ CMMb_FO SG_ 304 MstrTrigSyncInrtl11 "0";
BA_REL_ "GenSigSuprvResp" BU_SG_REL_ CMMb_FO SG_ 304 MstrTrigSyncInrtl11 1;
BA_REL_ "GenSigTimeoutMsg" BU_SG_REL_ CMMb_FO SG_ 304 MstrTrigSyncInrtl11 304;
BA_REL_ "GenSigTimeoutTime" BU_SG_REL_ CMMb_FO SG_ 304 MstrTrigSyncInrtl11 30;
BA_REL_ "GenSigRxStartValue" BU_SG_REL_ CMMa_FO SG_ 304 MstrTrigSyncInrtl11 "0";
BA_REL_ "GenSigSuprvResp" BU_SG_REL_ CMMa_FO SG_ 304 MstrTrigSyncInrtl11 1;
BA_REL_ "GenSigTimeoutMsg" BU_SG_REL_ CMMa_FO SG_ 304 MstrTrigSyncInrtl11 304;
BA_REL_ "GenSigTimeoutTime" BU_SG_REL_ CMMa_FO SG_ 304 MstrTrigSyncInrtl11 30;
BA_REL_ "GenSigVBitResp" BU_SG_REL_ CMMb_FO SG_ 304 InrtlSnsr1LatAcc 1;
BA_REL_ "GenSigRxStartValue" BU_SG_REL_ CMMb_FO SG_ 304 InrtlSnsr1LatAcc "0";
BA_REL_ "GenSigSuprvResp" BU_SG_REL_ CMMb_FO SG_ 304 InrtlSnsr1LatAcc 1;
BA_REL_ "GenSigTimeoutMsg" BU_SG_REL_ CMMb_FO SG_ 304 InrtlSnsr1LatAcc 304;
BA_REL_ "GenSigTimeoutTime" BU_SG_REL_ CMMb_FO SG_ 304 InrtlSnsr1LatAcc 30;
BA_REL_ "GenSigVBitResp" BU_SG_REL_ CMMa_FO SG_ 304 InrtlSnsr1LatAcc 1;
BA_REL_ "GenSigRxStartValue" BU_SG_REL_ CMMa_FO SG_ 304 InrtlSnsr1LatAcc "0";
BA_REL_ "GenSigSuprvResp" BU_SG_REL_ CMMa_FO SG_ 304 InrtlSnsr1LatAcc 1;
BA_REL_ "GenSigTimeoutMsg" BU_SG_REL_ CMMa_FO SG_ 304 InrtlSnsr1LatAcc 304;
BA_REL_ "GenSigTimeoutTime" BU_SG_REL_ CMMa_FO SG_ 304 InrtlSnsr1LatAcc 30;
BA_REL_ "GenSigVBitResp" BU_SG_REL_ EOCM2cp_K2_FO SG_ 304 InrtlSnsr1LatAcc 1;
BA_REL_ "GenSigRxStartValue" BU_SG_REL_ CMMb_FO SG_ 304 InrtlSnsr1LatAccV "Valid";
BA_REL_ "GenSigRxStartValue" BU_SG_REL_ CMMa_FO SG_ 304 InrtlSnsr1LatAccV "Valid";
BA_REL_ "GenSigVBitResp" BU_SG_REL_ CMMb_FO SG_ 304 InrtlSnsr1LonAcc 1;
BA_REL_ "GenSigRxStartValue" BU_SG_REL_ CMMb_FO SG_ 304 InrtlSnsr1LonAcc "0";
BA_REL_ "GenSigSuprvResp" BU_SG_REL_ CMMb_FO SG_ 304 InrtlSnsr1LonAcc 1;
BA_REL_ "GenSigTimeoutMsg" BU_SG_REL_ CMMb_FO SG_ 304 InrtlSnsr1LonAcc 304;
BA_REL_ "GenSigTimeoutTime" BU_SG_REL_ CMMb_FO SG_ 304 InrtlSnsr1LonAcc 30;
BA_REL_ "GenSigVBitResp" BU_SG_REL_ CMMa_FO SG_ 304 InrtlSnsr1LonAcc 1;
BA_REL_ "GenSigRxStartValue" BU_SG_REL_ CMMa_FO SG_ 304 InrtlSnsr1LonAcc "0";
BA_REL_ "GenSigSuprvResp" BU_SG_REL_ CMMa_FO SG_ 304 InrtlSnsr1LonAcc 1;
BA_REL_ "GenSigTimeoutMsg" BU_SG_REL_ CMMa_FO SG_ 304 InrtlSnsr1LonAcc 304;
BA_REL_ "GenSigTimeoutTime" BU_SG_REL_ CMMa_FO SG_ 304 InrtlSnsr1LonAcc 30;
BA_REL_ "GenSigVBitResp" BU_SG_REL_ EOCM2cp_K2_FO SG_ 304 InrtlSnsr1LonAcc 1;
BA_REL_ "GenSigRxStartValue" BU_SG_REL_ CMMb_FO SG_ 304 InrtlSnsr1LonAccV "Valid";
BA_REL_ "GenSigRxStartValue" BU_SG_REL_ CMMa_FO SG_ 304 InrtlSnsr1LonAccV "Valid";
BA_REL_ "GenSigVBitResp" BU_SG_REL_ CMMb_FO SG_ 304 InrtlSnsr1VertAcc 1;
BA_REL_ "GenSigRxStartValue" BU_SG_REL_ CMMb_FO SG_ 304 InrtlSnsr1VertAcc "0";
BA_REL_ "GenSigSuprvResp" BU_SG_REL_ CMMb_FO SG_ 304 InrtlSnsr1VertAcc 1;
BA_REL_ "GenSigTimeoutMsg" BU_SG_REL_ CMMb_FO SG_ 304 InrtlSnsr1VertAcc 304;
BA_REL_ "GenSigTimeoutTime" BU_SG_REL_ CMMb_FO SG_ 304 InrtlSnsr1VertAcc 30;
BA_REL_ "GenSigVBitResp" BU_SG_REL_ CMMa_FO SG_ 304 InrtlSnsr1VertAcc 1;
BA_REL_ "GenSigRxStartValue" BU_SG_REL_ CMMa_FO SG_ 304 InrtlSnsr1VertAcc "0";
BA_REL_ "GenSigSuprvResp" BU_SG_REL_ CMMa_FO SG_ 304 InrtlSnsr1VertAcc 1;
BA_REL_ "GenSigTimeoutMsg" BU_SG_REL_ CMMa_FO SG_ 304 InrtlSnsr1VertAcc 304;
BA_REL_ "GenSigTimeoutTime" BU_SG_REL_ CMMa_FO SG_ 304 InrtlSnsr1VertAcc 30;
BA_REL_ "GenSigVBitResp" BU_SG_REL_ EOCM2cp_K2_FO SG_ 304 InrtlSnsr1VertAcc 1;
BA_REL_ "GenSigRxStartValue" BU_SG_REL_ CMMb_FO SG_ 304 InrtlSnsr1VertAccV "Valid";
BA_REL_ "GenSigRxStartValue" BU_SG_REL_ CMMa_FO SG_ 304 InrtlSnsr1VertAccV "Valid";
BA_REL_ "GenSigRxStartValue" BU_SG_REL_ CMMb_FO SG_ 304 IntlSnsr1AcelFm1Chksm "0";
BA_REL_ "GenSigRxStartValue" BU_SG_REL_ CMMa_FO SG_ 304 IntlSnsr1AcelFm1Chksm "0";
BA_REL_ "GenSigRxStartValue" BU_SG_REL_ CMMb_FO SG_ 306 MstrTrigSyncInrtl12 "0";
BA_REL_ "GenSigSuprvResp" BU_SG_REL_ CMMb_FO SG_ 306 MstrTrigSyncInrtl12 1;
BA_REL_ "GenSigTimeoutMsg" BU_SG_REL_ CMMb_FO SG_ 306 MstrTrigSyncInrtl12 306;
BA_REL_ "GenSigTimeoutTime" BU_SG_REL_ CMMb_FO SG_ 306 MstrTrigSyncInrtl12 30;
BA_REL_ "GenSigRxStartValue" BU_SG_REL_ CMMa_FO SG_ 306 MstrTrigSyncInrtl12 "0";
BA_REL_ "GenSigSuprvResp" BU_SG_REL_ CMMa_FO SG_ 306 MstrTrigSyncInrtl12 1;
BA_REL_ "GenSigTimeoutMsg" BU_SG_REL_ CMMa_FO SG_ 306 MstrTrigSyncInrtl12 306;
BA_REL_ "GenSigTimeoutTime" BU_SG_REL_ CMMa_FO SG_ 306 MstrTrigSyncInrtl12 30;
BA_REL_ "GenSigRxStartValue" BU_SG_REL_ CMMb_FO SG_ 306 InrtlSnsr1AccelFrm2Chksm "0";
BA_REL_ "GenSigRxStartValue" BU_SG_REL_ CMMa_FO SG_ 306 InrtlSnsr1AccelFrm2Chksm "0";
BA_REL_ "GenSigVBitResp" BU_SG_REL_ CMMb_FO SG_ 306 InrtlSnsr1PtchAcc 1;
BA_REL_ "GenSigRxStartValue" BU_SG_REL_ CMMb_FO SG_ 306 InrtlSnsr1PtchAcc "0";
BA_REL_ "GenSigSuprvResp" BU_SG_REL_ CMMb_FO SG_ 306 InrtlSnsr1PtchAcc 1;
BA_REL_ "GenSigTimeoutMsg" BU_SG_REL_ CMMb_FO SG_ 306 InrtlSnsr1PtchAcc 306;
BA_REL_ "GenSigTimeoutTime" BU_SG_REL_ CMMb_FO SG_ 306 InrtlSnsr1PtchAcc 30;
BA_REL_ "GenSigVBitResp" BU_SG_REL_ CMMa_FO SG_ 306 InrtlSnsr1PtchAcc 1;
BA_REL_ "GenSigRxStartValue" BU_SG_REL_ CMMa_FO SG_ 306 InrtlSnsr1PtchAcc "0";
BA_REL_ "GenSigSuprvResp" BU_SG_REL_ CMMa_FO SG_ 306 InrtlSnsr1PtchAcc 1;
BA_REL_ "GenSigTimeoutMsg" BU_SG_REL_ CMMa_FO SG_ 306 InrtlSnsr1PtchAcc 306;
BA_REL_ "GenSigTimeoutTime" BU_SG_REL_ CMMa_FO SG_ 306 InrtlSnsr1PtchAcc 30;
BA_REL_ "GenSigVBitResp" BU_SG_REL_ EOCM2cp_K2_FO SG_ 306 InrtlSnsr1PtchAcc 1;
BA_REL_ "GenSigRxStartValue" BU_SG_REL_ CMMb_FO SG_ 306 InrtlSnsr1PtchAccV "Valid";
BA_REL_ "GenSigRxStartValue" BU_SG_REL_ CMMa_FO SG_ 306 InrtlSnsr1PtchAccV "Valid";
BA_REL_ "GenSigVBitResp" BU_SG_REL_ CMMb_FO SG_ 306 InrtlSnsr1RollAcc 1;
BA_REL_ "GenSigRxStartValue" BU_SG_REL_ CMMb_FO SG_ 306 InrtlSnsr1RollAcc "0";
BA_REL_ "GenSigSuprvResp" BU_SG_REL_ CMMb_FO SG_ 306 InrtlSnsr1RollAcc 1;
BA_REL_ "GenSigTimeoutMsg" BU_SG_REL_ CMMb_FO SG_ 306 InrtlSnsr1RollAcc 306;
BA_REL_ "GenSigTimeoutTime" BU_SG_REL_ CMMb_FO SG_ 306 InrtlSnsr1RollAcc 30;
BA_REL_ "GenSigVBitResp" BU_SG_REL_ CMMa_FO SG_ 306 InrtlSnsr1RollAcc 1;
BA_REL_ "GenSigRxStartValue" BU_SG_REL_ CMMa_FO SG_ 306 InrtlSnsr1RollAcc "0";
BA_REL_ "GenSigSuprvResp" BU_SG_REL_ CMMa_FO SG_ 306 InrtlSnsr1RollAcc 1;
BA_REL_ "GenSigTimeoutMsg" BU_SG_REL_ CMMa_FO SG_ 306 InrtlSnsr1RollAcc 306;
BA_REL_ "GenSigTimeoutTime" BU_SG_REL_ CMMa_FO SG_ 306 InrtlSnsr1RollAcc 30;
BA_REL_ "GenSigVBitResp" BU_SG_REL_ EOCM2cp_K2_FO SG_ 306 InrtlSnsr1RollAcc 1;
BA_REL_ "GenSigRxStartValue" BU_SG_REL_ CMMb_FO SG_ 306 InrtlSnsr1RollAccV "Valid";
BA_REL_ "GenSigRxStartValue" BU_SG_REL_ CMMa_FO SG_ 306 InrtlSnsr1RollAccV "Valid";
BA_REL_ "GenSigVBitResp" BU_SG_REL_ CMMb_FO SG_ 306 InrtlSnsr1YawAcc 1;
BA_REL_ "GenSigRxStartValue" BU_SG_REL_ CMMb_FO SG_ 306 InrtlSnsr1YawAcc "0";
BA_REL_ "GenSigSuprvResp" BU_SG_REL_ CMMb_FO SG_ 306 InrtlSnsr1YawAcc 1;
BA_REL_ "GenSigTimeoutMsg" BU_SG_REL_ CMMb_FO SG_ 306 InrtlSnsr1YawAcc 306;
BA_REL_ "GenSigTimeoutTime" BU_SG_REL_ CMMb_FO SG_ 306 InrtlSnsr1YawAcc 30;
BA_REL_ "GenSigVBitResp" BU_SG_REL_ CMMa_FO SG_ 306 InrtlSnsr1YawAcc 1;
BA_REL_ "GenSigRxStartValue" BU_SG_REL_ CMMa_FO SG_ 306 InrtlSnsr1YawAcc "0";
BA_REL_ "GenSigSuprvResp" BU_SG_REL_ CMMa_FO SG_ 306 InrtlSnsr1YawAcc 1;
BA_REL_ "GenSigTimeoutMsg" BU_SG_REL_ CMMa_FO SG_ 306 InrtlSnsr1YawAcc 306;
BA_REL_ "GenSigTimeoutTime" BU_SG_REL_ CMMa_FO SG_ 306 InrtlSnsr1YawAcc 30;
BA_REL_ "GenSigVBitResp" BU_SG_REL_ EOCM2cp_K2_FO SG_ 306 InrtlSnsr1YawAcc 1;
BA_REL_ "GenSigRxStartValue" BU_SG_REL_ CMMb_FO SG_ 306 InrtlSnsr1YawAccV "Valid";
BA_REL_ "GenSigRxStartValue" BU_SG_REL_ CMMa_FO SG_ 306 InrtlSnsr1YawAccV "Valid";
BA_REL_ "GenSigRxStartValue" BU_SG_REL_ CMMb_FO SG_ 308 MstrTrgrSyncInrtl1Rte "0";
BA_REL_ "GenSigSuprvResp" BU_SG_REL_ CMMb_FO SG_ 308 MstrTrgrSyncInrtl1Rte 1;
BA_REL_ "GenSigTimeoutMsg" BU_SG_REL_ CMMb_FO SG_ 308 MstrTrgrSyncInrtl1Rte 308;
BA_REL_ "GenSigTimeoutTime" BU_SG_REL_ CMMb_FO SG_ 308 MstrTrgrSyncInrtl1Rte 30;
BA_REL_ "GenSigRxStartValue" BU_SG_REL_ CMMa_FO SG_ 308 MstrTrgrSyncInrtl1Rte "0";
BA_REL_ "GenSigSuprvResp" BU_SG_REL_ CMMa_FO SG_ 308 MstrTrgrSyncInrtl1Rte 1;
BA_REL_ "GenSigTimeoutMsg" BU_SG_REL_ CMMa_FO SG_ 308 MstrTrgrSyncInrtl1Rte 308;
BA_REL_ "GenSigTimeoutTime" BU_SG_REL_ CMMa_FO SG_ 308 MstrTrgrSyncInrtl1Rte 30;
BA_REL_ "GenSigVBitResp" BU_SG_REL_ CMMb_FO SG_ 308 Inertial1PitchRte 1;
BA_REL_ "GenSigRxStartValue" BU_SG_REL_ CMMb_FO SG_ 308 Inertial1PitchRte "0";
BA_REL_ "GenSigSuprvResp" BU_SG_REL_ CMMb_FO SG_ 308 Inertial1PitchRte 1;
BA_REL_ "GenSigTimeoutMsg" BU_SG_REL_ CMMb_FO SG_ 308 Inertial1PitchRte 308;
BA_REL_ "GenSigTimeoutTime" BU_SG_REL_ CMMb_FO SG_ 308 Inertial1PitchRte 30;
BA_REL_ "GenSigVBitResp" BU_SG_REL_ CMMa_FO SG_ 308 Inertial1PitchRte 1;
BA_REL_ "GenSigRxStartValue" BU_SG_REL_ CMMa_FO SG_ 308 Inertial1PitchRte "0";
BA_REL_ "GenSigSuprvResp" BU_SG_REL_ CMMa_FO SG_ 308 Inertial1PitchRte 1;
BA_REL_ "GenSigTimeoutMsg" BU_SG_REL_ CMMa_FO SG_ 308 Inertial1PitchRte 308;
BA_REL_ "GenSigTimeoutTime" BU_SG_REL_ CMMa_FO SG_ 308 Inertial1PitchRte 30;
BA_REL_ "GenSigVBitResp" BU_SG_REL_ EOCM2cp_K2_FO SG_ 308 Inertial1PitchRte 1;
BA_REL_ "GenSigRxStartValue" BU_SG_REL_ CMMb_FO SG_ 308 Inertial1PitchRteV "Valid";
BA_REL_ "GenSigRxStartValue" BU_SG_REL_ CMMa_FO SG_ 308 Inertial1PitchRteV "Valid";
BA_REL_ "GenSigVBitResp" BU_SG_REL_ CMMb_FO SG_ 308 Inertial1RollRte 1;
BA_REL_ "GenSigRxStartValue" BU_SG_REL_ CMMb_FO SG_ 308 Inertial1RollRte "0";
BA_REL_ "GenSigSuprvResp" BU_SG_REL_ CMMb_FO SG_ 308 Inertial1RollRte 1;
BA_REL_ "GenSigTimeoutMsg" BU_SG_REL_ CMMb_FO SG_ 308 Inertial1RollRte 308;
BA_REL_ "GenSigTimeoutTime" BU_SG_REL_ CMMb_FO SG_ 308 Inertial1RollRte 30;
BA_REL_ "GenSigVBitResp" BU_SG_REL_ CMMa_FO SG_ 308 Inertial1RollRte 1;
BA_REL_ "GenSigRxStartValue" BU_SG_REL_ CMMa_FO SG_ 308 Inertial1RollRte "0";
BA_REL_ "GenSigSuprvResp" BU_SG_REL_ CMMa_FO SG_ 308 Inertial1RollRte 1;
BA_REL_ "GenSigTimeoutMsg" BU_SG_REL_ CMMa_FO SG_ 308 Inertial1RollRte 308;
BA_REL_ "GenSigTimeoutTime" BU_SG_REL_ CMMa_FO SG_ 308 Inertial1RollRte 30;
BA_REL_ "GenSigVBitResp" BU_SG_REL_ EOCM2cp_K2_FO SG_ 308 Inertial1RollRte 1;
BA_REL_ "GenSigRxStartValue" BU_SG_REL_ CMMb_FO SG_ 308 Inertial1RollRteV "Valid";
BA_REL_ "GenSigRxStartValue" BU_SG_REL_ CMMa_FO SG_ 308 Inertial1RollRteV "Valid";
BA_REL_ "GenSigRxStartValue" BU_SG_REL_ CMMb_FO SG_ 308 Inertial1RteChksum "0";
BA_REL_ "GenSigRxStartValue" BU_SG_REL_ CMMa_FO SG_ 308 Inertial1RteChksum "0";
BA_REL_ "GenSigVBitResp" BU_SG_REL_ CMMb_FO SG_ 308 Inertial1YawRte 1;
BA_REL_ "GenSigRxStartValue" BU_SG_REL_ CMMb_FO SG_ 308 Inertial1YawRte "0";
BA_REL_ "GenSigSuprvResp" BU_SG_REL_ CMMb_FO SG_ 308 Inertial1YawRte 1;
BA_REL_ "GenSigTimeoutMsg" BU_SG_REL_ CMMb_FO SG_ 308 Inertial1YawRte 308;
BA_REL_ "GenSigTimeoutTime" BU_SG_REL_ CMMb_FO SG_ 308 Inertial1YawRte 30;
BA_REL_ "GenSigVBitResp" BU_SG_REL_ CMMa_FO SG_ 308 Inertial1YawRte 1;
BA_REL_ "GenSigRxStartValue" BU_SG_REL_ CMMa_FO SG_ 308 Inertial1YawRte "0";
BA_REL_ "GenSigSuprvResp" BU_SG_REL_ CMMa_FO SG_ 308 Inertial1YawRte 1;
BA_REL_ "GenSigTimeoutMsg" BU_SG_REL_ CMMa_FO SG_ 308 Inertial1YawRte 308;
BA_REL_ "GenSigTimeoutTime" BU_SG_REL_ CMMa_FO SG_ 308 Inertial1YawRte 30;
BA_REL_ "GenSigVBitResp" BU_SG_REL_ EOCM2cp_K2_FO SG_ 308 Inertial1YawRte 1;
BA_REL_ "GenSigRxStartValue" BU_SG_REL_ CMMb_FO SG_ 308 Inertial1YawRteV "Valid";
BA_REL_ "GenSigRxStartValue" BU_SG_REL_ CMMa_FO SG_ 308 Inertial1YawRteV "Valid";
BA_REL_ "GenSigRxStartValue" BU_SG_REL_ CMMb_FO SG_ 310 MstrTrigSyncInrtl21 "0";
BA_REL_ "GenSigSuprvResp" BU_SG_REL_ CMMb_FO SG_ 310 MstrTrigSyncInrtl21 1;
BA_REL_ "GenSigTimeoutMsg" BU_SG_REL_ CMMb_FO SG_ 310 MstrTrigSyncInrtl21 310;
BA_REL_ "GenSigTimeoutTime" BU_SG_REL_ CMMb_FO SG_ 310 MstrTrigSyncInrtl21 30;
BA_REL_ "GenSigRxStartValue" BU_SG_REL_ CMMa_FO SG_ 310 MstrTrigSyncInrtl21 "0";
BA_REL_ "GenSigSuprvResp" BU_SG_REL_ CMMa_FO SG_ 310 MstrTrigSyncInrtl21 1;
BA_REL_ "GenSigTimeoutMsg" BU_SG_REL_ CMMa_FO SG_ 310 MstrTrigSyncInrtl21 310;
BA_REL_ "GenSigTimeoutTime" BU_SG_REL_ CMMa_FO SG_ 310 MstrTrigSyncInrtl21 30;
BA_REL_ "GenSigVBitResp" BU_SG_REL_ CMMb_FO SG_ 310 Inertial2LatAcc 1;
BA_REL_ "GenSigRxStartValue" BU_SG_REL_ CMMb_FO SG_ 310 Inertial2LatAcc "0";
BA_REL_ "GenSigSuprvResp" BU_SG_REL_ CMMb_FO SG_ 310 Inertial2LatAcc 1;
BA_REL_ "GenSigTimeoutMsg" BU_SG_REL_ CMMb_FO SG_ 310 Inertial2LatAcc 310;
BA_REL_ "GenSigTimeoutTime" BU_SG_REL_ CMMb_FO SG_ 310 Inertial2LatAcc 30;
BA_REL_ "GenSigVBitResp" BU_SG_REL_ CMMa_FO SG_ 310 Inertial2LatAcc 1;
BA_REL_ "GenSigRxStartValue" BU_SG_REL_ CMMa_FO SG_ 310 Inertial2LatAcc "0";
BA_REL_ "GenSigSuprvResp" BU_SG_REL_ CMMa_FO SG_ 310 Inertial2LatAcc 1;
BA_REL_ "GenSigTimeoutMsg" BU_SG_REL_ CMMa_FO SG_ 310 Inertial2LatAcc 310;
BA_REL_ "GenSigTimeoutTime" BU_SG_REL_ CMMa_FO SG_ 310 Inertial2LatAcc 30;
BA_REL_ "GenSigVBitResp" BU_SG_REL_ EOCM2cp_K2_FO SG_ 310 Inertial2LatAcc 1;
BA_REL_ "GenSigRxStartValue" BU_SG_REL_ CMMb_FO SG_ 310 Inertial2LatAccV "Valid";
BA_REL_ "GenSigRxStartValue" BU_SG_REL_ CMMa_FO SG_ 310 Inertial2LatAccV "Valid";
BA_REL_ "GenSigVBitResp" BU_SG_REL_ CMMb_FO SG_ 310 Inertial2LonAcc 1;
BA_REL_ "GenSigRxStartValue" BU_SG_REL_ CMMb_FO SG_ 310 Inertial2LonAcc "0";
BA_REL_ "GenSigSuprvResp" BU_SG_REL_ CMMb_FO SG_ 310 Inertial2LonAcc 1;
BA_REL_ "GenSigTimeoutMsg" BU_SG_REL_ CMMb_FO SG_ 310 Inertial2LonAcc 310;
BA_REL_ "GenSigTimeoutTime" BU_SG_REL_ CMMb_FO SG_ 310 Inertial2LonAcc 30;
BA_REL_ "GenSigVBitResp" BU_SG_REL_ CMMa_FO SG_ 310 Inertial2LonAcc 1;
BA_REL_ "GenSigRxStartValue" BU_SG_REL_ CMMa_FO SG_ 310 Inertial2LonAcc "0";
BA_REL_ "GenSigSuprvResp" BU_SG_REL_ CMMa_FO SG_ 310 Inertial2LonAcc 1;
BA_REL_ "GenSigTimeoutMsg" BU_SG_REL_ CMMa_FO SG_ 310 Inertial2LonAcc 310;
BA_REL_ "GenSigTimeoutTime" BU_SG_REL_ CMMa_FO SG_ 310 Inertial2LonAcc 30;
BA_REL_ "GenSigVBitResp" BU_SG_REL_ EOCM2cp_K2_FO SG_ 310 Inertial2LonAcc 1;
BA_REL_ "GenSigRxStartValue" BU_SG_REL_ CMMb_FO SG_ 310 Inertial2LonAccV "Valid";
BA_REL_ "GenSigRxStartValue" BU_SG_REL_ CMMa_FO SG_ 310 Inertial2LonAccV "Valid";
BA_REL_ "GenSigVBitResp" BU_SG_REL_ CMMb_FO SG_ 310 Inertial2VertAcc 1;
BA_REL_ "GenSigRxStartValue" BU_SG_REL_ CMMb_FO SG_ 310 Inertial2VertAcc "0";
BA_REL_ "GenSigSuprvResp" BU_SG_REL_ CMMb_FO SG_ 310 Inertial2VertAcc 1;
BA_REL_ "GenSigTimeoutMsg" BU_SG_REL_ CMMb_FO SG_ 310 Inertial2VertAcc 310;
BA_REL_ "GenSigTimeoutTime" BU_SG_REL_ CMMb_FO SG_ 310 Inertial2VertAcc 30;
BA_REL_ "GenSigVBitResp" BU_SG_REL_ CMMa_FO SG_ 310 Inertial2VertAcc 1;
BA_REL_ "GenSigRxStartValue" BU_SG_REL_ CMMa_FO SG_ 310 Inertial2VertAcc "0";
BA_REL_ "GenSigSuprvResp" BU_SG_REL_ CMMa_FO SG_ 310 Inertial2VertAcc 1;
BA_REL_ "GenSigTimeoutMsg" BU_SG_REL_ CMMa_FO SG_ 310 Inertial2VertAcc 310;
BA_REL_ "GenSigTimeoutTime" BU_SG_REL_ CMMa_FO SG_ 310 Inertial2VertAcc 30;
BA_REL_ "GenSigVBitResp" BU_SG_REL_ EOCM2cp_K2_FO SG_ 310 Inertial2VertAcc 1;
BA_REL_ "GenSigRxStartValue" BU_SG_REL_ CMMb_FO SG_ 310 Inertial2VertAccV "Valid";
BA_REL_ "GenSigRxStartValue" BU_SG_REL_ CMMa_FO SG_ 310 Inertial2VertAccV "Valid";
BA_REL_ "GenSigRxStartValue" BU_SG_REL_ CMMb_FO SG_ 310 IntlSnsr2AcelFm1Chksm "0";
BA_REL_ "GenSigRxStartValue" BU_SG_REL_ CMMa_FO SG_ 310 IntlSnsr2AcelFm1Chksm "0";
BA_REL_ "GenSigRxStartValue" BU_SG_REL_ CMMb_FO SG_ 312 MstrTrigSyncInrtl22 "0";
BA_REL_ "GenSigSuprvResp" BU_SG_REL_ CMMb_FO SG_ 312 MstrTrigSyncInrtl22 1;
BA_REL_ "GenSigTimeoutMsg" BU_SG_REL_ CMMb_FO SG_ 312 MstrTrigSyncInrtl22 312;
BA_REL_ "GenSigTimeoutTime" BU_SG_REL_ CMMb_FO SG_ 312 MstrTrigSyncInrtl22 30;
BA_REL_ "GenSigRxStartValue" BU_SG_REL_ CMMa_FO SG_ 312 MstrTrigSyncInrtl22 "0";
BA_REL_ "GenSigSuprvResp" BU_SG_REL_ CMMa_FO SG_ 312 MstrTrigSyncInrtl22 1;
BA_REL_ "GenSigTimeoutMsg" BU_SG_REL_ CMMa_FO SG_ 312 MstrTrigSyncInrtl22 312;
BA_REL_ "GenSigTimeoutTime" BU_SG_REL_ CMMa_FO SG_ 312 MstrTrigSyncInrtl22 30;
BA_REL_ "GenSigRxStartValue" BU_SG_REL_ CMMb_FO SG_ 312 InrtlSns2AccFrm2Chksm "0";
BA_REL_ "GenSigRxStartValue" BU_SG_REL_ CMMa_FO SG_ 312 InrtlSns2AccFrm2Chksm "0";
BA_REL_ "GenSigVBitResp" BU_SG_REL_ CMMb_FO SG_ 312 InrtlSnsr2PtchAcc 1;
BA_REL_ "GenSigRxStartValue" BU_SG_REL_ CMMb_FO SG_ 312 InrtlSnsr2PtchAcc "0";
BA_REL_ "GenSigSuprvResp" BU_SG_REL_ CMMb_FO SG_ 312 InrtlSnsr2PtchAcc 1;
BA_REL_ "GenSigTimeoutMsg" BU_SG_REL_ CMMb_FO SG_ 312 InrtlSnsr2PtchAcc 312;
BA_REL_ "GenSigTimeoutTime" BU_SG_REL_ CMMb_FO SG_ 312 InrtlSnsr2PtchAcc 30;
BA_REL_ "GenSigVBitResp" BU_SG_REL_ CMMa_FO SG_ 312 InrtlSnsr2PtchAcc 1;
BA_REL_ "GenSigRxStartValue" BU_SG_REL_ CMMa_FO SG_ 312 InrtlSnsr2PtchAcc "0";
BA_REL_ "GenSigSuprvResp" BU_SG_REL_ CMMa_FO SG_ 312 InrtlSnsr2PtchAcc 1;
BA_REL_ "GenSigTimeoutMsg" BU_SG_REL_ CMMa_FO SG_ 312 InrtlSnsr2PtchAcc 312;
BA_REL_ "GenSigTimeoutTime" BU_SG_REL_ CMMa_FO SG_ 312 InrtlSnsr2PtchAcc 30;
BA_REL_ "GenSigVBitResp" BU_SG_REL_ EOCM2cp_K2_FO SG_ 312 InrtlSnsr2PtchAcc 1;
BA_REL_ "GenSigRxStartValue" BU_SG_REL_ CMMb_FO SG_ 312 InrtlSnsr2PtchAccV "Valid";
BA_REL_ "GenSigRxStartValue" BU_SG_REL_ CMMa_FO SG_ 312 InrtlSnsr2PtchAccV "Valid";
BA_REL_ "GenSigVBitResp" BU_SG_REL_ CMMb_FO SG_ 312 InrtlSnsr2RollAcc 1;
BA_REL_ "GenSigRxStartValue" BU_SG_REL_ CMMb_FO SG_ 312 InrtlSnsr2RollAcc "0";
BA_REL_ "GenSigSuprvResp" BU_SG_REL_ CMMb_FO SG_ 312 InrtlSnsr2RollAcc 1;
BA_REL_ "GenSigTimeoutMsg" BU_SG_REL_ CMMb_FO SG_ 312 InrtlSnsr2RollAcc 312;
BA_REL_ "GenSigTimeoutTime" BU_SG_REL_ CMMb_FO SG_ 312 InrtlSnsr2RollAcc 30;
BA_REL_ "GenSigVBitResp" BU_SG_REL_ CMMa_FO SG_ 312 InrtlSnsr2RollAcc 1;
BA_REL_ "GenSigRxStartValue" BU_SG_REL_ CMMa_FO SG_ 312 InrtlSnsr2RollAcc "0";
BA_REL_ "GenSigSuprvResp" BU_SG_REL_ CMMa_FO SG_ 312 InrtlSnsr2RollAcc 1;
BA_REL_ "GenSigTimeoutMsg" BU_SG_REL_ CMMa_FO SG_ 312 InrtlSnsr2RollAcc 312;
BA_REL_ "GenSigTimeoutTime" BU_SG_REL_ CMMa_FO SG_ 312 InrtlSnsr2RollAcc 30;
BA_REL_ "GenSigVBitResp" BU_SG_REL_ EOCM2cp_K2_FO SG_ 312 InrtlSnsr2RollAcc 1;
BA_REL_ "GenSigRxStartValue" BU_SG_REL_ CMMb_FO SG_ 312 InrtlSnsr2RollAccV "Valid";
BA_REL_ "GenSigRxStartValue" BU_SG_REL_ CMMa_FO SG_ 312 InrtlSnsr2RollAccV "Valid";
BA_REL_ "GenSigVBitResp" BU_SG_REL_ CMMb_FO SG_ 312 InrtlSnsr2YawAcc 1;
BA_REL_ "GenSigRxStartValue" BU_SG_REL_ CMMb_FO SG_ 312 InrtlSnsr2YawAcc "0";
BA_REL_ "GenSigSuprvResp" BU_SG_REL_ CMMb_FO SG_ 312 InrtlSnsr2YawAcc 1;
BA_REL_ "GenSigTimeoutMsg" BU_SG_REL_ CMMb_FO SG_ 312 InrtlSnsr2YawAcc 312;
BA_REL_ "GenSigTimeoutTime" BU_SG_REL_ CMMb_FO SG_ 312 InrtlSnsr2YawAcc 30;
BA_REL_ "GenSigVBitResp" BU_SG_REL_ CMMa_FO SG_ 312 InrtlSnsr2YawAcc 1;
BA_REL_ "GenSigRxStartValue" BU_SG_REL_ CMMa_FO SG_ 312 InrtlSnsr2YawAcc "0";
BA_REL_ "GenSigSuprvResp" BU_SG_REL_ CMMa_FO SG_ 312 InrtlSnsr2YawAcc 1;
BA_REL_ "GenSigTimeoutMsg" BU_SG_REL_ CMMa_FO SG_ 312 InrtlSnsr2YawAcc 312;
BA_REL_ "GenSigTimeoutTime" BU_SG_REL_ CMMa_FO SG_ 312 InrtlSnsr2YawAcc 30;
BA_REL_ "GenSigVBitResp" BU_SG_REL_ EOCM2cp_K2_FO SG_ 312 InrtlSnsr2YawAcc 1;
BA_REL_ "GenSigRxStartValue" BU_SG_REL_ CMMb_FO SG_ 312 InrtlSnsr2YawAccV "Valid";
BA_REL_ "GenSigRxStartValue" BU_SG_REL_ CMMa_FO SG_ 312 InrtlSnsr2YawAccV "Valid";
BA_REL_ "GenSigRxStartValue" BU_SG_REL_ CMMb_FO SG_ 320 MstrTgrSyncInrtl2Rte "0";
BA_REL_ "GenSigSuprvResp" BU_SG_REL_ CMMb_FO SG_ 320 MstrTgrSyncInrtl2Rte 1;
BA_REL_ "GenSigTimeoutMsg" BU_SG_REL_ CMMb_FO SG_ 320 MstrTgrSyncInrtl2Rte 320;
BA_REL_ "GenSigTimeoutTime" BU_SG_REL_ CMMb_FO SG_ 320 MstrTgrSyncInrtl2Rte 30;
BA_REL_ "GenSigRxStartValue" BU_SG_REL_ CMMa_FO SG_ 320 MstrTgrSyncInrtl2Rte "0";
BA_REL_ "GenSigSuprvResp" BU_SG_REL_ CMMa_FO SG_ 320 MstrTgrSyncInrtl2Rte 1;
BA_REL_ "GenSigTimeoutMsg" BU_SG_REL_ CMMa_FO SG_ 320 MstrTgrSyncInrtl2Rte 320;
BA_REL_ "GenSigTimeoutTime" BU_SG_REL_ CMMa_FO SG_ 320 MstrTgrSyncInrtl2Rte 30;
BA_REL_ "GenSigVBitResp" BU_SG_REL_ CMMb_FO SG_ 320 Inertial2PitchRte 1;
BA_REL_ "GenSigRxStartValue" BU_SG_REL_ CMMb_FO SG_ 320 Inertial2PitchRte "0";
BA_REL_ "GenSigSuprvResp" BU_SG_REL_ CMMb_FO SG_ 320 Inertial2PitchRte 1;
BA_REL_ "GenSigTimeoutMsg" BU_SG_REL_ CMMb_FO SG_ 320 Inertial2PitchRte 320;
BA_REL_ "GenSigTimeoutTime" BU_SG_REL_ CMMb_FO SG_ 320 Inertial2PitchRte 30;
BA_REL_ "GenSigVBitResp" BU_SG_REL_ CMMa_FO SG_ 320 Inertial2PitchRte 1;
BA_REL_ "GenSigRxStartValue" BU_SG_REL_ CMMa_FO SG_ 320 Inertial2PitchRte "0";
BA_REL_ "GenSigSuprvResp" BU_SG_REL_ CMMa_FO SG_ 320 Inertial2PitchRte 1;
BA_REL_ "GenSigTimeoutMsg" BU_SG_REL_ CMMa_FO SG_ 320 Inertial2PitchRte 320;
BA_REL_ "GenSigTimeoutTime" BU_SG_REL_ CMMa_FO SG_ 320 Inertial2PitchRte 30;
BA_REL_ "GenSigVBitResp" BU_SG_REL_ EOCM2cp_K2_FO SG_ 320 Inertial2PitchRte 1;
BA_REL_ "GenSigRxStartValue" BU_SG_REL_ CMMb_FO SG_ 320 Inertial2PitchRteV "Valid";
BA_REL_ "GenSigRxStartValue" BU_SG_REL_ CMMa_FO SG_ 320 Inertial2PitchRteV "Valid";
BA_REL_ "GenSigVBitResp" BU_SG_REL_ CMMb_FO SG_ 320 Inertial2RollRte 1;
BA_REL_ "GenSigRxStartValue" BU_SG_REL_ CMMb_FO SG_ 320 Inertial2RollRte "0";
BA_REL_ "GenSigSuprvResp" BU_SG_REL_ CMMb_FO SG_ 320 Inertial2RollRte 1;
BA_REL_ "GenSigTimeoutMsg" BU_SG_REL_ CMMb_FO SG_ 320 Inertial2RollRte 320;
BA_REL_ "GenSigTimeoutTime" BU_SG_REL_ CMMb_FO SG_ 320 Inertial2RollRte 30;
BA_REL_ "GenSigVBitResp" BU_SG_REL_ CMMa_FO SG_ 320 Inertial2RollRte 1;
BA_REL_ "GenSigRxStartValue" BU_SG_REL_ CMMa_FO SG_ 320 Inertial2RollRte "0";
BA_REL_ "GenSigSuprvResp" BU_SG_REL_ CMMa_FO SG_ 320 Inertial2RollRte 1;
BA_REL_ "GenSigTimeoutMsg" BU_SG_REL_ CMMa_FO SG_ 320 Inertial2RollRte 320;
BA_REL_ "GenSigTimeoutTime" BU_SG_REL_ CMMa_FO SG_ 320 Inertial2RollRte 30;
BA_REL_ "GenSigVBitResp" BU_SG_REL_ EOCM2cp_K2_FO SG_ 320 Inertial2RollRte 1;
BA_REL_ "GenSigRxStartValue" BU_SG_REL_ CMMb_FO SG_ 320 Inertial2RollRteV "Valid";
BA_REL_ "GenSigRxStartValue" BU_SG_REL_ CMMa_FO SG_ 320 Inertial2RollRteV "Valid";
BA_REL_ "GenSigRxStartValue" BU_SG_REL_ CMMb_FO SG_ 320 Inertial2RteChksum "0";
BA_REL_ "GenSigRxStartValue" BU_SG_REL_ CMMa_FO SG_ 320 Inertial2RteChksum "0";
BA_REL_ "GenSigVBitResp" BU_SG_REL_ CMMb_FO SG_ 320 Inertial2YawRte 1;
BA_REL_ "GenSigRxStartValue" BU_SG_REL_ CMMb_FO SG_ 320 Inertial2YawRte "0";
BA_REL_ "GenSigSuprvResp" BU_SG_REL_ CMMb_FO SG_ 320 Inertial2YawRte 1;
BA_REL_ "GenSigTimeoutMsg" BU_SG_REL_ CMMb_FO SG_ 320 Inertial2YawRte 320;
BA_REL_ "GenSigTimeoutTime" BU_SG_REL_ CMMb_FO SG_ 320 Inertial2YawRte 30;
BA_REL_ "GenSigVBitResp" BU_SG_REL_ CMMa_FO SG_ 320 Inertial2YawRte 1;
BA_REL_ "GenSigRxStartValue" BU_SG_REL_ CMMa_FO SG_ 320 Inertial2YawRte "0";
BA_REL_ "GenSigSuprvResp" BU_SG_REL_ CMMa_FO SG_ 320 Inertial2YawRte 1;
BA_REL_ "GenSigTimeoutMsg" BU_SG_REL_ CMMa_FO SG_ 320 Inertial2YawRte 320;
BA_REL_ "GenSigTimeoutTime" BU_SG_REL_ CMMa_FO SG_ 320 Inertial2YawRte 30;
BA_REL_ "GenSigVBitResp" BU_SG_REL_ EOCM2cp_K2_FO SG_ 320 Inertial2YawRte 1;
BA_REL_ "GenSigRxStartValue" BU_SG_REL_ CMMb_FO SG_ 320 Inertial2YawRteV "Valid";
BA_REL_ "GenSigRxStartValue" BU_SG_REL_ CMMa_FO SG_ 320 Inertial2YawRteV "Valid";
BA_REL_ "GenSigTimeoutMsg" BU_SG_REL_ RSRR_FO SG_ 784 EngRunAtv 784;
BA_REL_ "GenSigTimeoutTime" BU_SG_REL_ RSRR_FO SG_ 784 EngRunAtv 250;
BA_REL_ "GenSigTimeoutMsg" BU_SG_REL_ LRR_FO SG_ 784 EngRunAtv 784;
BA_REL_ "GenSigTimeoutTime" BU_SG_REL_ LRR_FO SG_ 784 EngRunAtv 250;
BA_REL_ "GenSigTimeoutMsg" BU_SG_REL_ CIPM_FO SG_ 784 EngRunAtv 784;
BA_REL_ "GenSigTimeoutTime" BU_SG_REL_ CIPM_FO SG_ 784 EngRunAtv 250;
BA_REL_ "GenSigTimeoutMsg" BU_SG_REL_ LRR_FO SG_ 784 SysPwrMd 784;
BA_REL_ "GenSigTimeoutTime" BU_SG_REL_ LRR_FO SG_ 784 SysPwrMd 250;
BA_REL_ "GenSigSuprvResp" BU_SG_REL_ CIPM_FO SG_ 784 SysPwrMd 1;
BA_REL_ "GenSigTimeoutMsg" BU_SG_REL_ CIPM_FO SG_ 784 SysPwrMd 784;
BA_REL_ "GenSigTimeoutTime" BU_SG_REL_ CIPM_FO SG_ 784 SysPwrMd 250;
VAL_ 781 FHTObjType 11 "ChildCloseToDngrZone " 10 "PedMovngOutOfDngrZone" 9 "PedMovngIntoDngrZone" 8 "PedStngOutsideDngrZn " 7 "No_object_present " 6 "Fixed_roadside_object" 0 "ObjTypeUnknown" 1 "4_Whl_Vhcl_car_sm_trk" 2 "Large_vehicle_semi " 3 "Motocycle__bicycle " 4 "Pedestrian " 5 "Fixed_overhead_object  " ;
VAL_ 781 FHTPedObjType 11 "ChildCloseToDngrZone " 10 "PedMovngOutOfDngrZone" 9 "PedMovngIntoDngrZone" 8 "PedStngOutsideDngrZn " 7 "No_object_present " 6 "Fixed_roadside_object" 0 "ObjTypeUnknown" 1 "4_Whl_Vhcl_car_sm_trk" 2 "Large_vehicle_semi " 3 "Motocycle__bicycle " 4 "Pedestrian " 5 "Fixed_overhead_object  " ;
VAL_ 781 CIPMpedbrknw 10 "Active" 5 "Inactive" ;
VAL_ 801 HiTHreatDynProp 4 "Opposite_direction " 3 "Same_direction_as_host " 2 "Has_moved_but_stopped" 1 "Has_never_moved" 0 "DynPropUnknown" ;
VAL_ 1916 DTCI_DTCFaultType_77C 3 "Type C" 2 "Type B" 1 "Type A" 0 "Not Supported" ;
VAL_ 1916 DTCI_CodeSupported_77C 1 "true" 0 "false" ;
VAL_ 1916 DTCI_CurrentStatus_77C 1 "true" 0 "false" ;
VAL_ 1916 DTCI_TstNPsdCdClrdSt_77C 1 "true" 0 "false" ;
VAL_ 1916 DTCI_TstFldCdClrdStat_77C 1 "true" 0 "false" ;
VAL_ 1916 DTCI_HistStat_77C 1 "true" 0 "false" ;
VAL_ 1916 DTCI_TstNPsdPwrUpSt_77C 1 "true" 0 "false" ;
VAL_ 1916 DTCI_TstFldPwrUpSt_77C 1 "true" 0 "false" ;
VAL_ 1916 DTCI_WrnIndRqdSt_77C 1 "true" 0 "false" ;
VAL_ 1916 DTCI_DTCTriggered_77C 1 "true" 0 "false" ;
VAL_ 1916 DTCIUnused7_77C 1 "true" 0 "false" ;
VAL_ 1916 DTCIUnused6_77C 1 "true" 0 "false" ;
VAL_ 1916 DTCIUnused5_77C 1 "true" 0 "false" ;
VAL_ 1916 DTCIUnused4_77C 1 "true" 0 "false" ;
VAL_ 1916 DTCIUnused3_77C 1 "true" 0 "false" ;
VAL_ 1916 DTCIUnused2_77C 1 "true" 0 "false" ;
VAL_ 1916 DTCIUnused1_77C 1 "true" 0 "false" ;
VAL_ 1929 DTCI_CodeSupported_789 1 "true" 0 "false" ;
VAL_ 1929 DTCI_CurrentStatus_789 1 "true" 0 "false" ;
VAL_ 1929 DTCI_DTCFaultType_789 3 "Type C" 2 "Type B" 1 "Type A" 0 "Not Supported" ;
VAL_ 1929 DTCI_DTCTriggered_789 1 "true" 0 "false" ;
VAL_ 1929 DTCI_HistStat_789 1 "true" 0 "false" ;
VAL_ 1929 DTCI_TstFldCdClrdStat_789 1 "true" 0 "false" ;
VAL_ 1929 DTCI_TstFldPwrUpSt_789 1 "true" 0 "false" ;
VAL_ 1929 DTCI_TstNPsdCdClrdSt_789 1 "true" 0 "false" ;
VAL_ 1929 DTCI_TstNPsdPwrUpSt_789 1 "true" 0 "false" ;
VAL_ 1929 DTCIUnused1_789 1 "true" 0 "false" ;
VAL_ 1929 DTCIUnused2_789 1 "true" 0 "false" ;
VAL_ 1929 DTCIUnused3_789 1 "true" 0 "false" ;
VAL_ 1929 DTCIUnused4_789 1 "true" 0 "false" ;
VAL_ 1929 DTCIUnused5_789 1 "true" 0 "false" ;
VAL_ 1929 DTCIUnused6_789 1 "true" 0 "false" ;
VAL_ 1929 DTCIUnused7_789 1 "true" 0 "false" ;
VAL_ 1929 DTCI_WrnIndRqdSt_789 1 "true" 0 "false" ;
VAL_ 344 CSS_CoPilotCibAvail 1 "true" 0 "false" ;
VAL_ 344 CSS_CoPilotSysFltStat 5 "Copilot System Failure" 4 "Partial Function Fault Detected" 3 "Redundancy Fault Detected" 2 "Environmental Interference" 1 "Operational" 0 "Unknown" ;
VAL_ 344 CSS_CoPilotRvbAvail 1 "true" 0 "false" ;
VAL_ 344 CSS_CoPilotPcmAvail 1 "true" 0 "false" ;
VAL_ 344 CSS_CoPilotFcaAvail 1 "true" 0 "false" ;
VAL_ 344 CSS_CoPilotBrkExpctd 1 "true" 0 "false" ;
VAL_ 344 StrgAngTrqBsdEstSrfcMuConf 2 "Indeterminate" 1 "Use Data" 0 "Do Not Use Data" ;
VAL_ 344 StrgAngTrqBsdEstSrfcMuCapV 1 "Invalid" 0 "Valid" ;
VAL_ 161 FTimeSyncMstrClockV 1 "Invalid" 0 "Valid" ;
VAL_ 161 SensorModeCmdFCamera 5 "Sensing with Reduced Power" 4 "Undefined" 3 "Radio Silent" 2 "Sensing" 1 "Not Sensing" 0 "Undefined" ;
VAL_ 161 SensorModeCmdSRR 5 "Sensing with Reduced Power" 4 "Undefined" 3 "Radio Silent" 2 "Sensing" 1 "Not Sensing" 0 "Undefined" ;
VAL_ 161 SensorModeCmdLRR 5 "Sensing with Reduced Power" 4 "Undefined" 3 "Radio Silent" 2 "Sensing" 1 "Not Sensing" 0 "Undefined" ;
VAL_ 776 Vpath_Data2ModeInfo 2 "Mid Hi Spped" 1 "Low Speed" 0 "Disabled" ;
VAL_ 776 Vpath_Data2YawRateV 1 "Invalid" 0 "Valid" ;
VAL_ 776 Vpath_Data2LongVelV 1 "Invalid" 0 "Valid" ;
VAL_ 776 Vpath_Data2LatVelV 1 "Invalid" 0 "Valid" ;
VAL_ 776 Vpath_Data2TravlDirctn 3 "Other (excessive side slip)" 2 "reverse / stopped in rvrs gear" 1 "Forward / stopped in frwd gear" 0 "Unknown" ;
VAL_ 774 Vpath_TrnCtrLngOfstV 1 "Invalid" 0 "Valid" ;
VAL_ 774 Vpath_CurvatureV 1 "Invalid" 0 "Valid" ;
VAL_ 768 SmgrMotRollAngleV 1 "Invalid" 0 "Valid" ;
VAL_ 768 SmgrMotPitchAngleV 1 "Invalid" 0 "Valid" ;
VAL_ 768 SmgrMotLongSpeedV 1 "Invalid" 0 "Valid" ;
VAL_ 768 SmgrMotYawRateV 1 "Invalid" 0 "Valid" ;
VAL_ 1033 CLL_Cnfdnc 7 "Reserved4" 6 "Reserved3" 5 "Reserved2" 4 "Reserved1" 3 "Best" 2 "Marking Present" 1 "Weak Marking" 0 "No Lane" ;
VAL_ 1034 CRL_Cnfdnc 7 "Reserved4" 6 "Reserved3" 5 "Reserved2" 4 "Reserved1" 3 "Best" 2 "Marking Present" 1 "Weak Marking" 0 "No Lane" ;
VAL_ 848 FwdVsnEnvIllum 0 "Unknown" 1 "Day" 2 "Dawn/Dusk" 3 "Pre-Dawn/Post Dusk" 4 "Night/Lit" 5 "Night/Unlit" ;
VAL_ 848 LaneSenseSystemOK 1 "true" 0 "false" ;
VAL_ 848 LaneSenseSystemOKV 1 "Invalid" 0 "Valid" ;
VAL_ 848 LaneSenseTimeStampV 1 "Invalid" 0 "Valid" ;
VAL_ 848 LaneSnsLLnPosValid 1 "Invalid" 0 "Valid" ;
VAL_ 848 LnSnsLnChngStatus 2 "Lane Change Right" 1 "Lane Change Left" 0 "Idle" ;
VAL_ 848 LnSnsRLnPosValid 0 "Valid" 1 "Invalid" ;
VAL_ 848 LnSnsTngtOfHdngLnRtV 1 "Invalid" 0 "Valid" ;
VAL_ 849 LnSnsCrvtGrdntRtV 1 "Invalid" 0 "Valid" ;
VAL_ 849 LnSnsLnCrvtrRghtV 1 "Invalid" 0 "Valid" ;
VAL_ 849 LnSnsLnMrkgWdthRt 0 "Narrow" 1 "Wide" ;
VAL_ 849 LnSnsLtAnchrLn 1 "true" 0 "false" ;
VAL_ 849 LnSnsRtAnchrLn 1 "true" 0 "false" ;
VAL_ 850 LnMrkrElvtdLft 1 "true" 0 "false" ;
VAL_ 850 LnMrkrElvtdRght 1 "true" 0 "false" ;
VAL_ 850 LnMrkrTypLft 0 "Unknown" 1 "Solid" 2 "Dashed" 3 "Dotted" ;
VAL_ 850 LnMrkrTypRght 0 "Unknown" 1 "Solid" 2 "Dashed" 3 "Dotted" ;
VAL_ 850 LnSnsLnCrvtrLftV 1 "Invalid" 0 "Valid" ;
VAL_ 850 LnSnsLtLnMrkgWdth 0 "Narrow" 1 "Wide" ;
VAL_ 850 LnSnsTngtOfHdngLnLftV 1 "Invalid" 0 "Valid" ;
VAL_ 851 LnMrkg3AnchrLnLin 1 "true" 0 "false" ;
VAL_ 851 LnMrkg3LnMarkrElvtd 1 "true" 0 "false" ;
VAL_ 851 LnMrkg3LnMrkgWdth 0 "Narrow" 1 "Wide" ;
VAL_ 851 LnMrkg4AnchrLnLin 1 "true" 0 "false" ;
VAL_ 851 LnMrkg4LnMarkrElvtd 1 "true" 0 "false" ;
VAL_ 851 LnMrkg4LnMrkgWdth 0 "Narrow" 1 "Wide" ;
VAL_ 851 LnSnsCrvtGrdntLftV 1 "Invalid" 0 "Valid" ;
VAL_ 852 LnMrkg3LnMrkrTyp 6 "Road Edge" 5 "Double" 4 "Bott’s Dots" 3 "Dotted" 2 "Dashed" 1 "Solid" 0 "None" ;
VAL_ 852 LnMrkg3LnSnsLnCrvtGradV 1 "Invalid" 0 "Valid" ;
VAL_ 852 LnMrkg3LnSnsLnCrvtV 1 "Invalid" 0 "Valid" ;
VAL_ 852 LnMrkg3LnSnsLnDstV 1 "Invalid" 0 "Valid" ;
VAL_ 852 LnMrkg3LnSnsLnHdngTngtV 1 "Invalid" 0 "Valid" ;
VAL_ 853 LnMrkg4LnMrkrTyp 0 "None" 1 "Solid" 2 "Dashed" 3 "Dotted" 4 "Bott’s Dots" 5 "Double" 6 "Road Edge" ;
VAL_ 853 LnMrkg4LnSnsLnCrvtGradV 1 "Invalid" 0 "Valid" ;
VAL_ 853 LnMrkg4LnSnsLnCrvtV 1 "Invalid" 0 "Valid" ;
VAL_ 853 LnMrkg4LnSnsLnDstV 1 "Invalid" 0 "Valid" ;
VAL_ 853 LnMrkg4LnSnsLnHdngTngtV 1 "Invalid" 0 "Valid" ;
VAL_ 854 FwdVsnCnstrctZnDet 0 "Unknown" 1 "Construction Detected" 2 "No Construction Zone Detected" ;
VAL_ 854 FwdVsnEgoVehLnPos 0 "Unknown" 1 "Leftmost Lane" 2 "Rightmost Lane" 3 "In Between" ;
VAL_ 854 FwdVsnRdTypDet 0 "Unknown" 1 "Inside Cities/Villages" 2 "Country Road" 3 "Highway" ;
VAL_ 854 FwdVsnTunnlDetd 0 "Unknown" 1 "Tunnel Detected" 2 "No Tunnel Detected" ;
VAL_ 304 InrtlSnsr1LatAccV 1 "Invalid" 0 "Valid" ;
VAL_ 304 InrtlSnsr1LonAccV 1 "Invalid" 0 "Valid" ;
VAL_ 304 InrtlSnsr1VertAccV 1 "Invalid" 0 "Valid" ;
VAL_ 306 InrtlSnsr1PtchAccV 1 "Invalid" 0 "Valid" ;
VAL_ 306 InrtlSnsr1RollAccV 1 "Invalid" 0 "Valid" ;
VAL_ 306 InrtlSnsr1YawAccV 1 "Invalid" 0 "Valid" ;
VAL_ 308 Inertial1PitchRteV 1 "Invalid" 0 "Valid" ;
VAL_ 308 Inertial1RollRteV 1 "Invalid" 0 "Valid" ;
VAL_ 308 Inertial1YawRteV 1 "Invalid" 0 "Valid" ;
VAL_ 310 Inertial2LatAccV 1 "Invalid" 0 "Valid" ;
VAL_ 310 Inertial2LonAccV 1 "Invalid" 0 "Valid" ;
VAL_ 310 Inertial2VertAccV 1 "Invalid" 0 "Valid" ;
VAL_ 312 InrtlSnsr2PtchAccV 1 "Invalid" 0 "Valid" ;
VAL_ 312 InrtlSnsr2RollAccV 1 "Invalid" 0 "Valid" ;
VAL_ 312 InrtlSnsr2YawAccV 1 "Invalid" 0 "Valid" ;
VAL_ 320 Inertial2PitchRteV 1 "Invalid" 0 "Valid" ;
VAL_ 320 Inertial2RollRteV 1 "Invalid" 0 "Valid" ;
VAL_ 320 Inertial2YawRteV 1 "Invalid" 0 "Valid" ;
VAL_ 784 EngRunAtv 1 "true" 0 "false" ;
VAL_ 784 CPMAPINFO4 1 "Hardware Or Software Error" 0 "No Hardware Or Software Error" ;
VAL_ 784 StrgColCommsFlt 2 "Disabled Communications DTC" 1 "No Communications Fault" 0 "Communications Fault" ;
VAL_ 784 DrDoorOpenSwActV 1 "Invalid" 0 "Valid" ;
VAL_ 784 DrDoorOpenSwAct 1 "true" 0 "false" ;
VAL_ 784 DrvWndPosStat 6 "Fully Opened" 5 "Open More Than C" 4 "Position C" 3 "Posistion B" 2 "Posistion A" 1 "Open Less Than A" 0 "Fully Closed" ;
VAL_ 784 InterLghtStat 1 "Interior Lights On" 0 "Interior Light Off" ;
VAL_ 784 DrvrHndsOnWhlZn3 1 "true" 0 "false" ;
VAL_ 784 DrvrHndsOnWhlZn2 1 "true" 0 "false" ;
VAL_ 784 DrvrHndsOnWhlZn1 1 "true" 0 "false" ;
VAL_ 784 WSWshSwAtv 1 "true" 0 "false" ;
VAL_ 784 WSWprAct 1 "true" 0 "false" ;
VAL_ 784 RtLwBmFld 1 "true" 0 "false" ;
VAL_ 784 OtsdAmbtLtLvlStatV 1 "Invalid" 0 "Valid" ;
VAL_ 784 OtsdAmbtLtLvlStat 2 "Day" 1 "Night" 0 "Unknown" ;
VAL_ 784 LowBmAct 1 "true" 0 "false" ;
VAL_ 784 LftLwBmFld 1 "true" 0 "false" ;
VAL_ 784 HighBmAct 1 "true" 0 "false" ;
VAL_ 784 TrStLgMdAtv 1 "true" 0 "false" ;
VAL_ 784 SysPwrMd 3 "Crank Request" 2 "Run" 1 "Accessory" 0 "Off" ;
VAL_ 784 SysPwrMdV 1 "Invalid" 0 "Valid" ;
VAL_ 1915 DTCI_DTCFaultType_77B 3 "Type C" 2 "Type B" 1 "Type A" 0 "Not Supported" ;
VAL_ 1915 DTCI_CodeSupported_77B 1 "true" 0 "false" ;
VAL_ 1915 DTCI_CurrentStatus_77B 1 "true" 0 "false" ;
VAL_ 1915 DTCI_TstNPsdCdClrdSt_77B 1 "true" 0 "false" ;
VAL_ 1915 DTCI_TstFldCdClrdStat_77B 1 "true" 0 "false" ;
VAL_ 1915 DTCI_HistStat_77B 1 "true" 0 "false" ;
VAL_ 1915 DTCI_TstNPsdPwrUpSt_77B 1 "true" 0 "false" ;
VAL_ 1915 DTCI_TstFldPwrUpSt_77B 1 "true" 0 "false" ;
VAL_ 1915 DTCI_WrnIndRqdSt_77B 1 "true" 0 "false" ;
VAL_ 1915 DTCI_DTCTriggered_77B 1 "true" 0 "false" ;
VAL_ 1915 DTCIUnused7_77B 1 "true" 0 "false" ;
VAL_ 1915 DTCIUnused6_77B 1 "true" 0 "false" ;
VAL_ 1915 DTCIUnused5_77B 1 "true" 0 "false" ;
VAL_ 1915 DTCIUnused4_77B 1 "true" 0 "false" ;
VAL_ 1915 DTCIUnused3_77B 1 "true" 0 "false" ;
VAL_ 1915 DTCIUnused2_77B 1 "true" 0 "false" ;
VAL_ 1915 DTCIUnused1_77B 1 "true" 0 "false" ;
SIG_GROUP_ 1916 DTCInfo_77C 1 : DTCI_DTCFaultType_77C DTCI_CodeSupported_77C DTCI_CurrentStatus_77C DTCI_TstNPsdCdClrdSt_77C DTCI_TstFldCdClrdStat_77C DTCI_HistStat_77C DTCI_TstNPsdPwrUpSt_77C DTCI_TstFldPwrUpSt_77C DTCI_WrnIndRqdSt_77C DTCI_DTCFailType_77C DTCI_DTCNumber_77C DTCI_DTCSource_77C DTCI_DTCTriggered_77C DTCIUnused7_77C DTCIUnused6_77C DTCIUnused5_77C DTCIUnused4_77C DTCIUnused3_77C DTCIUnused2_77C DTCIUnused1_77C;
SIG_GROUP_ 1929 DTCInfo_789 1 : DTCI_CodeSupported_789 DTCI_CurrentStatus_789 DTCI_DTCFailType_789 DTCI_DTCFaultType_789 DTCI_DTCNumber_789 DTCI_DTCSource_789 DTCI_DTCTriggered_789 DTCI_HistStat_789 DTCI_TstFldCdClrdStat_789 DTCI_TstFldPwrUpSt_789 DTCI_TstNPsdCdClrdSt_789 DTCI_TstNPsdPwrUpSt_789 DTCIUnused1_789 DTCIUnused2_789 DTCIUnused3_789 DTCIUnused4_789 DTCIUnused5_789 DTCIUnused6_789 DTCIUnused7_789 DTCI_WrnIndRqdSt_789;
SIG_GROUP_ 344 CoPilotSysStat 1 : CSS_CoPilotCibAvail CSS_CoPilotSysFltStat CSS_CoPilotRvbAvail CSS_CoPilotPcmAvail CSS_CoPilotFcaAvail CSS_CoPilotBrkExpctd;
SIG_GROUP_ 1033 CurvLftLine 1 : CLL_Cnfdnc CLL_ViewRng CLL_CoefdA CLL_CoefA;
SIG_GROUP_ 1034 CurvRghtLine 1 : CRL_Cnfdnc CRL_ViewRng CRL_CoefdA CRL_CoefA;
SIG_GROUP_ 1915 DTCInfo_77B 1 : DTCI_DTCFaultType_77B DTCI_CodeSupported_77B DTCI_CurrentStatus_77B DTCI_TstNPsdCdClrdSt_77B DTCI_TstFldCdClrdStat_77B DTCI_HistStat_77B DTCI_TstNPsdPwrUpSt_77B DTCI_TstFldPwrUpSt_77B DTCI_WrnIndRqdSt_77B DTCI_DTCFailType_77B DTCI_DTCNumber_77B DTCI_DTCSource_77B DTCI_DTCTriggered_77B DTCIUnused7_77B DTCIUnused6_77B DTCIUnused5_77B DTCIUnused4_77B DTCIUnused3_77B DTCIUnused2_77B DTCIUnused1_77B;
